VERSION ""

NS_ :

BS_:

BU_:

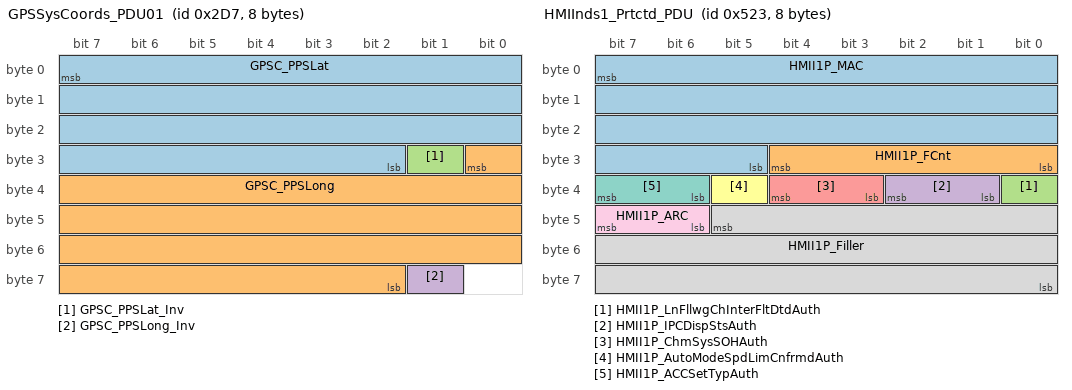
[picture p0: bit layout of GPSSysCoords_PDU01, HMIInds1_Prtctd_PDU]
BO_ 727 GPSSysCoords_PDU01: 8 Vector__XXX
 SG_ GPSC_PPSLat : 7|30@0- (1,0) [-5.36871e+008|5.36871e+008] "ms arc" ACP2_MCU,BSM,VICM,ECM,EOCM,EOCM_HC_Superset,FCM,E44,PCM,VDM,ECP_E
 SG_ GPSC_PPSLong : 24|31@0- (1,0) [-1.07374e+009|1.07374e+009] "ms arc" ACP2_MCU,BSM,VICM,ECM,EOCM,EOCM_HC_Superset,FCM,E44,PCM,VDM,ECP_E
 SG_ GPSC_PPSLat_Inv : 25|1@0+ (1,0) [0|1] "" ACP2_MCU,BSM,VICM,EOCM,EOCM_HC_Superset,FCM,E44,VDM,ECP_E
 SG_ GPSC_PPSLong_Inv : 57|1@0+ (1,0) [0|1] "" ACP2_MCU,BSM,VICM,EOCM,EOCM_HC_Superset,FCM,E44,VDM,ECP_E

BO_ 1385 HMIInds1_PCSM_PDU: 8 Vector__XXX
 SG_ HMIInds1_PCSM : 7|64@0+ (1,0) [0|1.84467e+019] "" ACP2_MCU,EOCM,EOCM_HC_Superset,FCM

BO_ 1315 HMIInds1_Prtctd_PDU: 8 Vector__XXX
 SG_ HMII1P_MAC : 7|27@0+ (1,0) [0|1.34218e+008] "" ACP2_MCU,EOCM,EOCM_HC_Superset,FCM
 SG_ HMII1P_FCnt : 28|5@0+ (1,0) [0|31] "" ACP2_MCU,EOCM,EOCM_HC_Superset,FCM
 SG_ HMII1P_LnFllwgChInterFltDtdAuth : 32|1@0+ (1,0) [0|1] "" ACP2_MCU,EOCM,EOCM_HC_Superset,FCM
 SG_ HMII1P_IPCDispStsAuth : 34|2@0+ (1,0) [0|2] "" ACP2_MCU,EOCM,EOCM_HC_Superset,FCM
 SG_ HMII1P_ChmSysSOHAuth : 36|2@0+ (1,0) [0|2] "" ACP2_MCU,EOCM,EOCM_HC_Superset,FCM
 SG_ HMII1P_AutoModeSpdLimCnfrmdAuth : 37|1@0+ (1,0) [0|1] "" ACP2_MCU,ECM,EOCM,EOCM_HC_Superset,FCM,PCM,ECP_E
 SG_ HMII1P_ACCSetTypAuth : 39|2@0+ (1,0) [0|1] "" ACP2_MCU,EOCM,EOCM_HC_Superset,FCM
 SG_ HMII1P_Filler : 45|22@0+ (1,0) [0|4.1943e+006] "" ACP2_MCU,EOCM,EOCM_HC_Superset,FCM
 SG_ HMII1P_ARC : 47|2@0+ (1,0) [0|3] "" ACP2_MCU,EOCM,EOCM_HC_Superset,FCM

BO_ 2147745832 Message0346_PDU: 6 Vector__XXX
 SG_ Sig3538 : 7|1@0+ (1,0) [0|1] "" CGM

BO_ 916 Message0351_PDU: 8 Vector__XXX
 SG_ Sig3618 : 7|64@0+ (1,0) [0|1.84467e+019] "" BSM_MH

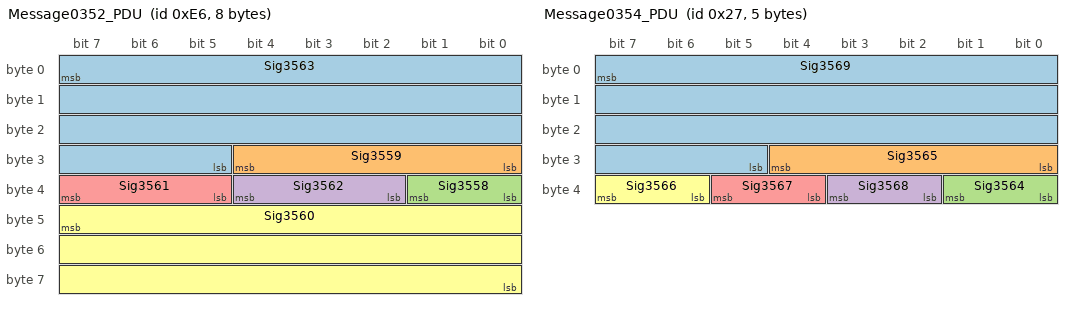
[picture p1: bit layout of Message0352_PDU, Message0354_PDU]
BO_ 230 Message0352_PDU: 8 Vector__XXX
 SG_ Sig3563 : 7|27@0+ (1,0) [0|1.34218e+008] "" BSM_MH
 SG_ Sig3559 : 28|5@0+ (1,0) [0|31] "" BSM_MH
 SG_ Sig3558 : 33|2@0+ (1,0) [0|3] "" BSM_MH
 SG_ Sig3562 : 36|3@0+ (1,0) [0|3] "" BSM_MH
 SG_ Sig3561 : 39|3@0+ (1,0) [0|4] "" BSM_MH
 SG_ Sig3560 : 47|24@0+ (1,0) [0|1.67772e+007] "" BSM_MH

BO_ 915 Message0353_PDU: 8 Vector__XXX
 SG_ Sig3619 : 7|64@0+ (1,0) [0|1.84467e+019] "" ECM,ECP_MC,PCM

BO_ 39 Message0354_PDU: 5 Vector__XXX
 SG_ Sig3569 : 7|27@0+ (1,0) [0|1.34218e+008] "" ECM,ECP_MC,PCM
 SG_ Sig3565 : 28|5@0+ (1,0) [0|31] "" ECM,ECP_MC,PCM
 SG_ Sig3564 : 33|2@0+ (1,0) [0|3] "" ECM,ECP_MC,PCM
 SG_ Sig3568 : 35|2@0+ (1,0) [0|3] "" ECM,ECP_MC,PCM
 SG_ Sig3567 : 37|2@0+ (1,0) [0|2] "" ECM,ECP_MC,PCM
 SG_ Sig3566 : 39|2@0+ (1,0) [0|2] "" ECM,ECP_MC,PCM

BO_ 1384 HptcSt_PCSM_PDU: 8 Vector__XXX
 SG_ HptcSt_PCSM : 7|64@0+ (1,0) [0|1.84467e+019] "" ACP2_MCU,EOCM,EOCM_HC_Superset,FCM

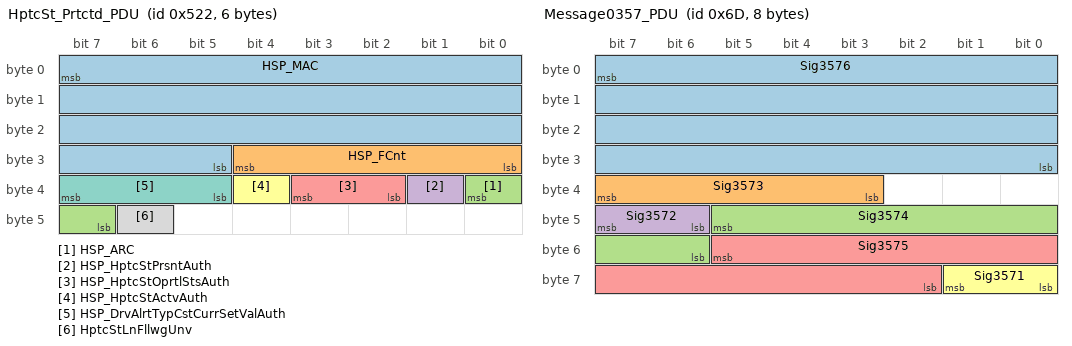
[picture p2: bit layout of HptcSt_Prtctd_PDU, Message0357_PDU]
BO_ 1314 HptcSt_Prtctd_PDU: 6 Vector__XXX
 SG_ HSP_MAC : 7|27@0+ (1,0) [0|1.34218e+008] "" ACP2_MCU,EOCM,EOCM_HC_Superset,FCM
 SG_ HSP_FCnt : 28|5@0+ (1,0) [0|31] "" ACP2_MCU,EOCM,EOCM_HC_Superset,FCM
 SG_ HSP_ARC : 32|2@0+ (1,0) [0|3] "" ACP2_MCU,EOCM,EOCM_HC_Superset,FCM
 SG_ HSP_HptcStPrsntAuth : 33|1@0+ (1,0) [0|1] "" ACP2_MCU,EOCM,EOCM_HC_Superset,FCM
 SG_ HSP_HptcStOprtlStsAuth : 35|2@0+ (1,0) [0|2] "" ACP2_MCU,EOCM,EOCM_HC_Superset,FCM
 SG_ HSP_HptcStActvAuth : 36|1@0+ (1,0) [0|1] "" ACP2_MCU,EOCM,EOCM_HC_Superset,FCM
 SG_ HSP_DrvAlrtTypCstCurrSetValAuth : 39|3@0+ (1,0) [0|2] "" ACP2_MCU,EOCM,EOCM_HC_Superset,FCM,NVM
 SG_ HptcStLnFllwgUnv : 46|1@0+ (1,0) [0|1] "" ACP2_MCU,EOCM,EOCM_HC_Superset,FCM

BO_ 914 HstVehPathParms_PCSM_PDU: 8 Vector__XXX
 SG_ HstVehPathParms_PCSM : 7|64@0+ (1,0) [0|1.84467e+019] "" DMS

BO_ 87 HstVehPathParms_Prtctd_PDU: 32 Vector__XXX
 SG_ HVPPP_MAC : 7|32@0+ (1,0) [0|4.29497e+009] "" CGM,DMS
 SG_ HVPPP_FCnt : 39|5@0+ (1,0) [0|31] "" CGM,DMS
 SG_ HVPPP_HstVehLatVelAuth : 46|8@0+ (0.05,-6.4) [-6.4|6.35] "m/s" CGM,DMS
 SG_ HVPPP_FrwdVsnModeCmdAuth : 47|1@0+ (1,0) [0|1] "" CGM,DMS
 SG_ HVPPP_HstVehLngVelAuth : 53|12@0+ (0.0625,-128) [-128|127.938] "m/s" CGM,DMS,NVM
 SG_ HVPPP_HstVehLatVelAuth_Inv : 54|1@0+ (1,0) [0|1] "" CGM,DMS
 SG_ HVPPP_HstVehPathCrvAuth : 56|16@0- (1e-05,0) [-0.32768|0.32767] "1/m" CGM,DMS
 SG_ HVPPP_HstVehLngVelAuth_Inv : 57|1@0+ (1,0) [0|1] "" CGM,DMS
 SG_ HVPPP_HstVehPathCrvDrvtAuth : 72|15@0+ (0.001,-16) [-16|16.767] "1/m-s" CGM,DMS
 SG_ HVPPP_HstVehPathModeAuth : 89|2@0+ (1,0) [0|2] "" CGM,DMS
 SG_ HVPPP_HstVehSdslAngAuth : 103|12@0+ (0.0625,-128) [-128|127.938] "deg/s" CGM,DMS
 SG_ HVPPP_HstVehTrnCntrLatOfstAuth : 107|14@0+ (1,-8192) [-8192|8191] "m" CGM,DMS
 SG_ HVPPP_HstVehTrnCntrLngOfstAuth : 125|8@0+ (0.1,-12.8) [-12.8|12.7] "m" CGM,DMS
 SG_ HVPPP_HstVehVelAuth : 131|12@0+ (0.0625,-128) [-128|127.938] "m/s" CGM,DMS
 SG_ HVPPP_HstVehTrvlDirAuth : 133|2@0+ (1,0) [0|3] "" CGM,DMS
 SG_ HVPPP_HstVehYawRateAuth : 150|12@0+ (0.0625,-128) [-128|127.938] "deg/s" CGM,DMS,NVM
 SG_ HVPPP_HstVehVelAuth_Inv : 151|1@0+ (1,0) [0|1] "" CGM,DMS
 SG_ HVPPP_LngRngRadarModeCmdAuth : 153|2@0+ (1,0) [0|2] "" CGM,DMS
 SG_ HVPPP_HstVehYawRateAuth_Inv : 154|1@0+ (1,0) [0|1] "" CGM,DMS,NVM
 SG_ HVPPP_ObjSnsrTmSyncMstrClckAuth : 167|32@0+ (1,0) [0|4.29497e+009] "ms" CGM,DMS
 SG_ HVPPP_ARC : 193|2@0+ (1,0) [0|3] "" CGM,DMS
 SG_ HVPPP_ShrtRngRadarModeCmdAuth : 195|2@0+ (1,0) [0|2] "" CGM,DMS
 SG_ HVPPP_ObjsRetndRrwdSnsrsAuth : 197|2@0+ (1,0) [0|2] "" CGM,DMS
 SG_ HVPPP_ObjsRetndFrwdSnsrsAuth : 199|2@0+ (1,0) [0|2] "" CGM,DMS
 SG_ HstVehRideHghtOfst : 201|9@0- (1,0) [-256|255] "mm" CGM,DMS
 SG_ DrvrMonSysModeCmd : 203|2@0+ (1,0) [0|2] "" CGM,DMS
 SG_ LnFllwgFtrStatAuth : 207|4@0+ (1,0) [0|10] "" CGM,DMS
 SG_ HstVehRideHghtOfst_Inv : 208|1@0+ (1,0) [0|1] "" CGM,DMS
 SG_ HVPPP_Filler : 222|19@0+ (1,0) [0|524287] "" CGM,DMS
 SG_ HstVehRideHghtOfstSts : 223|1@0+ (1,0) [0|1] "" CGM,DMS
 SG_ HVPPP_FillerExtnd : 235|20@0+ (1,0) [0|1.04858e+006] "" CGM,DMS

BO_ 687 Message0356_PDU: 8 Vector__XXX
 SG_ Sig3623 : 7|64@0+ (1,0) [0|1.84467e+019] "" Vector__XXX

BO_ 109 Message0357_PDU: 8 Vector__XXX
 SG_ Sig3576 : 7|32@0+ (1,0) [0|4.29497e+009] "" Vector__XXX
 SG_ Sig3573 : 39|5@0+ (1,0) [0|31] "" Vector__XXX
 SG_ Sig3574 : 45|8@0- (0.05,0) [-6.4|6.35] "m/s" Vector__XXX
 SG_ Sig3572 : 47|2@0+ (1,0) [0|3] "" Vector__XXX
 SG_ Sig3575 : 53|12@0- (0.0625,0) [-128|127.938] "m/s" Vector__XXX
 SG_ Sig3571 : 57|2@0+ (1,0) [0|3] "" Vector__XXX

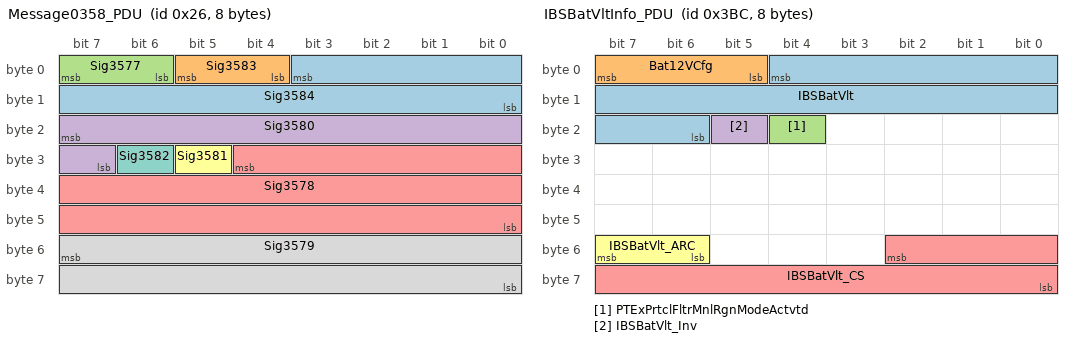
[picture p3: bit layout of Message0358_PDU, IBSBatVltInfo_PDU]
BO_ 38 Message0358_PDU: 8 Vector__XXX
 SG_ Sig3584 : 3|12@0- (0.0625,0) [-128|127.938] "deg/s" Vector__XXX
 SG_ Sig3583 : 5|2@0+ (1,0) [0|3] "" Vector__XXX
 SG_ Sig3577 : 7|2@0+ (1,0) [0|3] "" Vector__XXX
 SG_ Sig3580 : 23|9@0- (1,0) [-256|255] "mm" Vector__XXX
 SG_ Sig3578 : 28|21@0+ (1,0) [0|2.09715e+006] "" Vector__XXX
 SG_ Sig3581 : 29|1@0+ (1,0) [0|1] "" Vector__XXX
 SG_ Sig3582 : 30|1@0+ (1,0) [0|1] "" Vector__XXX
 SG_ Sig3579 : 55|16@0+ (1,0) [0|65535] "" Vector__XXX

BO_ 956 IBSBatVltInfo_PDU: 8 Vector__XXX
 SG_ IBSBatVlt : 4|15@0+ (0.001,0) [0|32.767] "" ECM,PCM
 SG_ Bat12VCfg : 7|3@0+ (1,0) [0|7] "" ECM,PCM
 SG_ PTExPrtclFltrMnlRgnModeActvtd : 20|1@0+ (1,0) [0|1] "" ECM,PCM
 SG_ IBSBatVlt_Inv : 21|1@0+ (1,0) [0|1] "" ECM,PCM
 SG_ IBSBatVlt_CS : 50|11@0+ (1,0) [0|2047] "" ECM,PCM
 SG_ IBSBatVlt_ARC : 55|2@0+ (1,0) [0|3] "" ECM,PCM

BO_ 729 ImoInf_PDU: 8 Vector__XXX
 SG_ ImoInf : 7|64@0+ (1,0) [0|1.84467e+019] "" ECM,PCM,ECP_X1

BO_ 1285 Isolated_GWCGM_PDU02: 6 Vector__XXX
 SG_ HptcStFldIndOn : 15|1@0+ (1,0) [0|1] "" ACP2_MCU,EOCM_HC_Superset,FCM

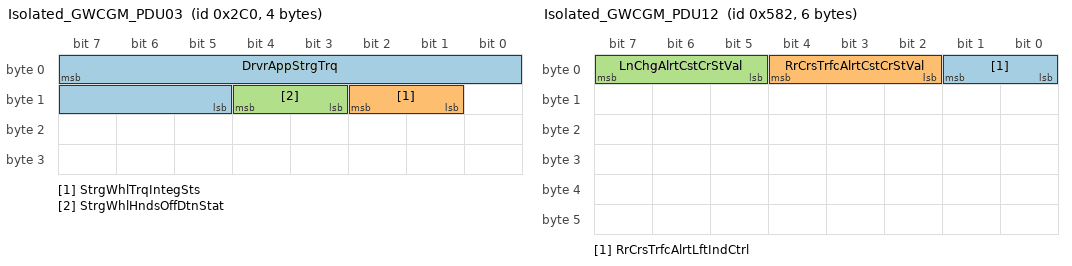
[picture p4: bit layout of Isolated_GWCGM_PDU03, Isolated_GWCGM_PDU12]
BO_ 704 Isolated_GWCGM_PDU03: 4 Vector__XXX
 SG_ DrvrAppStrgTrq : 7|11@0- (0.01,0) [-10.24|10.23] "Nm" Vector__XXX
 SG_ StrgWhlTrqIntegSts : 10|2@0+ (1,0) [0|3] "" Vector__XXX
 SG_ StrgWhlHndsOffDtnStat : 12|2@0+ (1,0) [0|2] "" Vector__XXX

BO_ 1419 Message0367_PDU: 6 Vector__XXX
 SG_ Sig7713 : 1|2@0+ (1,0) [0|3] "" Vector__XXX
 SG_ Sig7709 : 4|3@0+ (1,0) [0|7] "" Vector__XXX
 SG_ Sig3506 : 7|3@0+ (1,0) [0|7] "" Vector__XXX
 SG_ Sig3504 : 8|1@0+ (1,0) [0|1] "" Vector__XXX
 SG_ Sig3503 : 9|1@0+ (1,0) [0|1] "" Vector__XXX
 SG_ Sig3502 : 10|1@0+ (1,0) [0|1] "" Vector__XXX
 SG_ Sig3501 : 11|1@0+ (1,0) [0|1] "" Vector__XXX
 SG_ Sig3500 : 12|1@0+ (1,0) [0|1] "" Vector__XXX
 SG_ Sig3499 : 13|1@0+ (1,0) [0|1] "" Vector__XXX
 SG_ Sig3498 : 14|1@0+ (1,0) [0|1] "" Vector__XXX
 SG_ Sig0451 : 15|1@0+ (1,0) [0|1] "" Vector__XXX
 SG_ Sig7707 : 16|1@0+ (1,0) [0|1] "" Vector__XXX
 SG_ Sig7706 : 17|1@0+ (1,0) [0|1] "" Vector__XXX
 SG_ Sig7705 : 18|1@0+ (1,0) [0|1] "" Vector__XXX
 SG_ Sig7704 : 19|1@0+ (1,0) [0|1] "" Vector__XXX
 SG_ Sig7703 : 20|1@0+ (1,0) [0|1] "" Vector__XXX
 SG_ Sig7702 : 21|1@0+ (1,0) [0|1] "" Vector__XXX
 SG_ Sig7701 : 22|1@0+ (1,0) [0|1] "" Vector__XXX
 SG_ Sig3507 : 23|1@0+ (1,0) [0|1] "" Vector__XXX
 SG_ Sig7710 : 31|1@0+ (1,0) [0|1] "" Vector__XXX

BO_ 1501 Message0368_PDU: 8 Vector__XXX
 SG_ Sig7554 : 7|8@0+ (1,0) [0|255] "" Vector__XXX
 SG_ Sig7559 : 9|6@0+ (1,0) [0|54] "" Vector__XXX
 SG_ Sig7557 : 15|6@0+ (1,0) [0|54] "" Vector__XXX
 SG_ Sig7567 : 19|6@0+ (1,0) [0|45] "" Vector__XXX
 SG_ Sig7569 : 29|6@0+ (1,0) [0|45] "" Vector__XXX
 SG_ Sig7558 : 35|4@0+ (1,0) [0|15] "" Vector__XXX
 SG_ Sig7556 : 39|4@0+ (1,0) [0|15] "" Vector__XXX
 SG_ Sig3474 : 40|1@0+ (1,0) [0|1] "" Vector__XXX
 SG_ Sig3473 : 41|1@0+ (1,0) [0|1] "" Vector__XXX
 SG_ Sig7568 : 44|3@0+ (1,0) [0|5] "" Vector__XXX
 SG_ Sig7566 : 47|3@0+ (1,0) [0|5] "" Vector__XXX
 SG_ Sig7711 : 48|1@0+ (1,0) [0|1] "" Vector__XXX
 SG_ Sig7700 : 49|1@0+ (1,0) [0|1] "" Vector__XXX
 SG_ Sig7564 : 50|1@0+ (1,0) [0|1] "" Vector__XXX
 SG_ Sig7562 : 51|1@0+ (1,0) [0|1] "" Vector__XXX
 SG_ Sig7561 : 52|1@0+ (1,0) [0|1] "" Vector__XXX
 SG_ Sig7560 : 53|1@0+ (1,0) [0|1] "" Vector__XXX
 SG_ Sig7553 : 54|1@0+ (1,0) [0|1] "" Vector__XXX
 SG_ Sig3475 : 55|1@0+ (1,0) [0|1] "" Vector__XXX
 SG_ Sig7712 : 63|1@0+ (1,0) [0|1] "" Vector__XXX

BO_ 1427 Isolated_GWCGM_PDU06: 6 Vector__XXX
 SG_ SBZALCAVisIndStatLt : 7|2@0+ (1,0) [0|2] "" ACP2_MCU,EOCM,EOCM_HC_Superset,FCM

BO_ 1428 Isolated_GWCGM_PDU07: 6 Vector__XXX
 SG_ SBZALCAVisIndStatRt : 7|2@0+ (1,0) [0|2] "" ACP2_MCU,EOCM,EOCM_HC_Superset,FCM

BO_ 1420 Isolated_GWCGM_PDU09: 6 Vector__XXX
 SG_ TLAHSR_HptcStRqstSeqNmb : 1|2@0+ (1,0) [0|3] "counts" Vector__XXX
 SG_ TLAHSR_HptcStRqstPls : 7|6@0+ (1,0) [0|63] "pulses" Vector__XXX

BO_ 1432 Isolated_GWCGM_PDU10: 6 Vector__XXX
 SG_ AutoHgBmActReq : 7|1@0+ (1,0) [0|1] "" Vector__XXX

BO_ 706 Isolated_GWCGM_PDU11: 4 Vector__XXX
 SG_ Sig4151 : 7|8@0- (1,0) [-128|127] "Kph" AHL_AFL,FCM
 SG_ LtFstAprchgVehObjDtd : 15|1@0+ (1,0) [0|1] "" AHL_AFL,FCM

BO_ 1410 Isolated_GWCGM_PDU12: 6 Vector__XXX
 SG_ RrCrsTrfcAlrtLftIndCtrl : 1|2@0+ (1,0) [0|2] "" ACP2_MCU,EOCM,EOCM_HC_Superset,FCM
 SG_ RrCrsTrfcAlrtCstCrStVal : 4|3@0+ (1,0) [0|7] "" ACP2_MCU,EOCM,EOCM_HC_Superset,FCM
 SG_ LnChgAlrtCstCrStVal : 7|3@0+ (1,0) [0|7] "" ACP2_MCU,EOCM,EOCM_HC_Superset,FCM

BO_ 1444 Isolated_GWCGM_PDU13: 6 Vector__XXX
 SG_ LtSdVehObjDtd : 5|1@0+ (1,0) [0|1] "" ACP2_MCU,AHL_AFL,EOCM,EOCM_HC_Superset,FCM
 SG_ SBZALCAOvrllOplSts : 7|2@0+ (1,0) [0|2] "" ACP2_MCU,EOCM,EOCM_HC_Superset,FCM

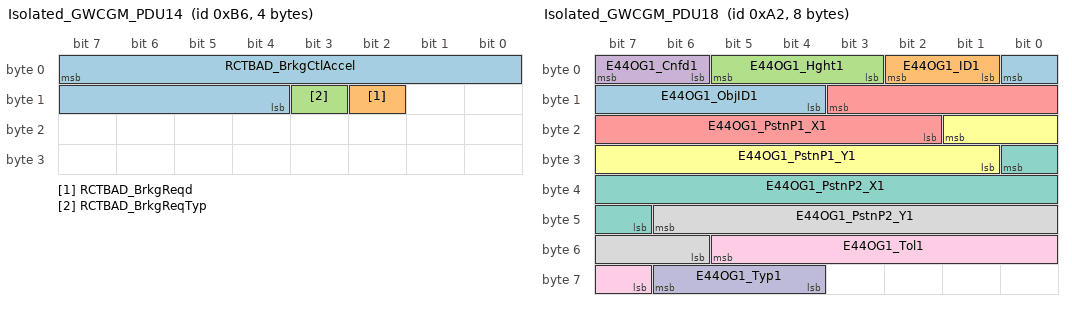
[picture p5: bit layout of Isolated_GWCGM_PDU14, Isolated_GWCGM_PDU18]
BO_ 182 Isolated_GWCGM_PDU14: 4 Vector__XXX
 SG_ RCTBAD_BrkgCtlAccel : 7|12@0- (0.01,0) [-20.48|20.47] "m/s2" EBCM
 SG_ RCTBAD_BrkgReqd : 10|1@0+ (1,0) [0|1] "" ACP2_MCU,EBCM,EOCM,EOCM_HC_Superset
 SG_ RCTBAD_BrkgReqTyp : 11|1@0+ (1,0) [0|1] "" EBCM

BO_ 708 Isolated_GWCGM_PDU16: 4 Vector__XXX
 SG_ Sig5569 : 7|8@0- (1,0) [-128|127] "Kph" AHL_AFL,FCM
 SG_ RtFstAprchgVehObjDtd : 15|1@0+ (1,0) [0|1] "" AHL_AFL,FCM

BO_ 1412 Isolated_GWCGM_PDU17: 6 Vector__XXX
 SG_ RtSdVehObjDtd : 3|1@0+ (1,0) [0|1] "" ACP2_MCU,AHL_AFL,EOCM,EOCM_HC_Superset,FCM
 SG_ RrCrsTrfcAlrtRgIndCtrl : 7|2@0+ (1,0) [0|2] "" ACP2_MCU,EOCM,EOCM_HC_Superset,FCM

BO_ 162 Isolated_GWCGM_PDU18: 8 Vector__XXX
 SG_ E44OG1_ObjID1 : 0|5@0+ (1,0) [0|31] "" FCM
 SG_ E44OG1_ID1 : 2|2@0+ (1,0) [0|3] "" FCM
 SG_ E44OG1_Hght1 : 5|3@0+ (1,0) [0|3] "" FCM
 SG_ E44OG1_Cnfd1 : 7|2@0+ (1,0) [0|3] "" FCM
 SG_ E44OG1_PstnP1_X1 : 11|10@0+ (1,-1023) [-1023|0] "cm" FCM
 SG_ E44OG1_PstnP1_Y1 : 17|9@0- (1,0) [-256|255] "cm" FCM
 SG_ E44OG1_PstnP2_X1 : 24|10@0+ (1,-1023) [-1023|0] "cm" FCM
 SG_ E44OG1_PstnP2_Y1 : 46|9@0- (1,0) [-256|255] "cm" FCM
 SG_ E44OG1_Tol1 : 53|7@0+ (1,0) [0|127] "cm" FCM
 SG_ E44OG1_Typ1 : 62|3@0+ (1,0) [0|6] "" FCM

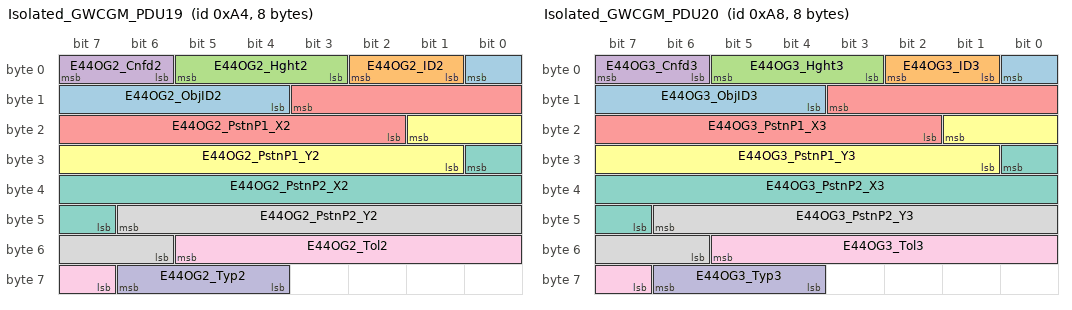
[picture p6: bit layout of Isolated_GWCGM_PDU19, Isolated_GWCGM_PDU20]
BO_ 164 Isolated_GWCGM_PDU19: 8 Vector__XXX
 SG_ E44OG2_ObjID2 : 0|5@0+ (1,0) [0|31] "" FCM
 SG_ E44OG2_ID2 : 2|2@0+ (1,0) [0|3] "" FCM
 SG_ E44OG2_Hght2 : 5|3@0+ (1,0) [0|3] "" FCM
 SG_ E44OG2_Cnfd2 : 7|2@0+ (1,0) [0|3] "" FCM
 SG_ E44OG2_PstnP1_X2 : 11|10@0+ (1,-1023) [-1023|0] "cm" FCM
 SG_ E44OG2_PstnP1_Y2 : 17|9@0- (1,0) [-256|255] "cm" FCM
 SG_ E44OG2_PstnP2_X2 : 24|10@0+ (1,-1023) [-1023|0] "cm" FCM
 SG_ E44OG2_PstnP2_Y2 : 46|9@0- (1,0) [-256|255] "cm" FCM
 SG_ E44OG2_Tol2 : 53|7@0+ (1,0) [0|127] "cm" FCM
 SG_ E44OG2_Typ2 : 62|3@0+ (1,0) [0|6] "" FCM

BO_ 168 Isolated_GWCGM_PDU20: 8 Vector__XXX
 SG_ E44OG3_ObjID3 : 0|5@0+ (1,0) [0|31] "" FCM
 SG_ E44OG3_ID3 : 2|2@0+ (1,0) [0|3] "" FCM
 SG_ E44OG3_Hght3 : 5|3@0+ (1,0) [0|3] "" FCM
 SG_ E44OG3_Cnfd3 : 7|2@0+ (1,0) [0|3] "" FCM
 SG_ E44OG3_PstnP1_X3 : 11|10@0+ (1,-1023) [-1023|0] "cm" FCM
 SG_ E44OG3_PstnP1_Y3 : 17|9@0- (1,0) [-256|255] "cm" FCM
 SG_ E44OG3_PstnP2_X3 : 24|10@0+ (1,-1023) [-1023|0] "cm" FCM
 SG_ E44OG3_PstnP2_Y3 : 46|9@0- (1,0) [-256|255] "cm" FCM
 SG_ E44OG3_Tol3 : 53|7@0+ (1,0) [0|127] "cm" FCM
 SG_ E44OG3_Typ3 : 62|3@0+ (1,0) [0|6] "" FCM

BO_ 2147745821 Message0370_PDU: 1 Vector__XXX
 SG_ Sig4007 : 7|1@0+ (1,0) [0|1] "" CGM

BO_ 1421 LnFllwgFtrStat_CAN2_PDU01: 6 Vector__XXX
 SG_ LnFllwgFtrStat : 7|4@0+ (1,0) [0|10] "" Vector__XXX

BO_ 1383 LnFllwgHptcStReqs_PCSM_PDU: 8 Vector__XXX
 SG_ LnFllwgHptcStReqs_PCSM : 7|64@0+ (1,0) [0|1.84467e+019] "" Vector__XXX

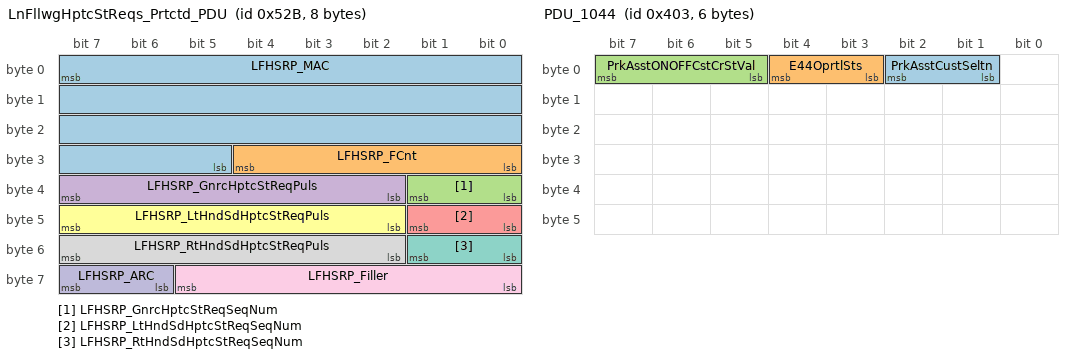
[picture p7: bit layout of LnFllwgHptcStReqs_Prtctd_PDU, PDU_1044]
BO_ 1323 LnFllwgHptcStReqs_Prtctd_PDU: 8 Vector__XXX
 SG_ LFHSRP_MAC : 7|27@0+ (1,0) [0|1.34218e+008] "" Vector__XXX
 SG_ LFHSRP_FCnt : 28|5@0+ (1,0) [0|31] "" Vector__XXX
 SG_ LFHSRP_GnrcHptcStReqSeqNum : 33|2@0+ (1,0) [0|3] "count" Vector__XXX
 SG_ LFHSRP_GnrcHptcStReqPuls : 39|6@0+ (1,0) [0|63] "counts" Vector__XXX
 SG_ LFHSRP_LtHndSdHptcStReqSeqNum : 41|2@0+ (1,0) [0|3] "count" Vector__XXX
 SG_ LFHSRP_LtHndSdHptcStReqPuls : 47|6@0+ (1,0) [0|63] "counts" Vector__XXX
 SG_ LFHSRP_RtHndSdHptcStReqSeqNum : 49|2@0+ (1,0) [0|3] "count" Vector__XXX
 SG_ LFHSRP_RtHndSdHptcStReqPuls : 55|6@0+ (1,0) [0|63] "counts" Vector__XXX
 SG_ LFHSRP_Filler : 61|6@0+ (1,0) [0|63] "" Vector__XXX
 SG_ LFHSRP_ARC : 63|2@0+ (1,0) [0|3] "" Vector__XXX

BO_ 1027 PDU_1044: 6 Vector__XXX
 SG_ PrkAsstCustSeltn : 2|2@0+ (1,0) [0|2] "" FCM
 SG_ E44OprtlSts : 4|2@0+ (1,0) [0|2] "" FCM
 SG_ PrkAsstONOFFCstCrStVal : 7|3@0+ (1,0) [0|7] "" CGM,FCM

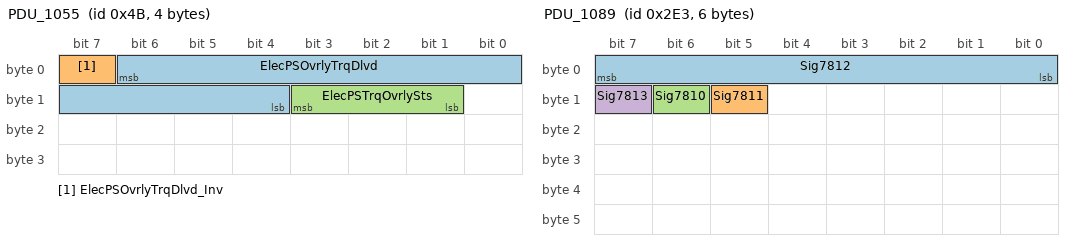
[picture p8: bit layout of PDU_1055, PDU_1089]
BO_ 75 PDU_1055: 4 Vector__XXX
 SG_ ElecPSOvrlyTrqDlvd : 6|11@0- (0.01,0) [-10.24|10.23] "" EBCM
 SG_ ElecPSOvrlyTrqDlvd_Inv : 7|1@0+ (1,0) [0|1] "" EBCM
 SG_ ElecPSTrqOvrlySts : 11|3@0+ (1,0) [0|5] "" CGM,EBCM

BO_ 32 PDU_1062: 6 Vector__XXX
 SG_ StrgEstdRckF : 6|11@0- (25,0) [-25600|25575] "N" ECP_E
 SG_ StrgEstdRckF_Inv : 7|1@0+ (1,0) [0|1] "" ECP_E

BO_ 739 PDU_1089: 6 Vector__XXX
 SG_ Sig7812 : 7|8@0+ (10,500) [500|3050] "RPM" ECM
 SG_ Sig7811 : 13|1@0+ (1,0) [0|1] "" ECM
 SG_ Sig7810 : 14|1@0+ (1,0) [0|1] "" ECM
 SG_ Sig7813 : 15|1@0+ (1,0) [0|1] "" ECM

BO_ 946 PDU_2000: 8 Vector__XXX
 SG_ Sig0417 : 1|2@0+ (1,0) [0|3] "" CGM
 SG_ Sig4160 : 4|3@0+ (1,0) [0|7] "" CGM
 SG_ Sig0415 : 7|3@0+ (1,0) [0|7] "" CGM
 SG_ Sig0109 : 8|1@0+ (1,0) [0|1] "" CGM
 SG_ AFLServHdlmpsIndOn : 9|1@0+ (1,0) [0|1] "" CGM
 SG_ Sig0108 : 10|1@0+ (1,0) [0|1] "" CGM
 SG_ Sig0107 : 11|1@0+ (1,0) [0|1] "" CGM
 SG_ Sig0106 : 12|1@0+ (1,0) [0|1] "" CGM
 SG_ Sig0105 : 13|1@0+ (1,0) [0|1] "" CGM
 SG_ Sig0104 : 14|1@0+ (1,0) [0|1] "" CGM
 SG_ Sig0103 : 15|1@0+ (1,0) [0|1] "" CGM
 SG_ Sig0413 : 16|1@0+ (1,0) [0|1] "" CGM
 SG_ Sig0412 : 17|1@0+ (1,0) [0|1] "" CGM
 SG_ Sig0411 : 18|1@0+ (1,0) [0|1] "" CGM
 SG_ Sig0410 : 19|1@0+ (1,0) [0|1] "" CGM
 SG_ Sig0409 : 20|1@0+ (1,0) [0|1] "" CGM
 SG_ Sig0408 : 21|1@0+ (1,0) [0|1] "" CGM
 SG_ Sig0407 : 22|1@0+ (1,0) [0|1] "" CGM
 SG_ Sig0110 : 23|1@0+ (1,0) [0|1] "" CGM
 SG_ Sig4157 : 24|1@0+ (1,0) [0|1] "" CGM
 SG_ Sig4156 : 25|1@0+ (1,0) [0|1] "" CGM
 SG_ Sig4155 : 26|1@0+ (1,0) [0|1] "" CGM
 SG_ Sig4154 : 27|1@0+ (1,0) [0|1] "" CGM
 SG_ Sig4153 : 28|1@0+ (1,0) [0|1] "" CGM
 SG_ Sig4152 : 29|1@0+ (1,0) [0|1] "" CGM
 SG_ AdvdFrtLgtSysHiBmIndOnReqd : 30|1@0+ (1,0) [0|1] "" CGM
 SG_ Sig0416 : 31|1@0+ (1,0) [0|1] "" CGM
 SG_ Sig4161 : 38|1@0+ (1,0) [0|1] "" CGM
 SG_ Sig4158 : 39|1@0+ (1,0) [0|1] "" CGM

BO_ 701 PDU_2001: 2 Vector__XXX
 SG_ AE44CtrlTctlFdbk : 7|1@0+ (1,0) [0|1] "" CGM,EPS,EPSb

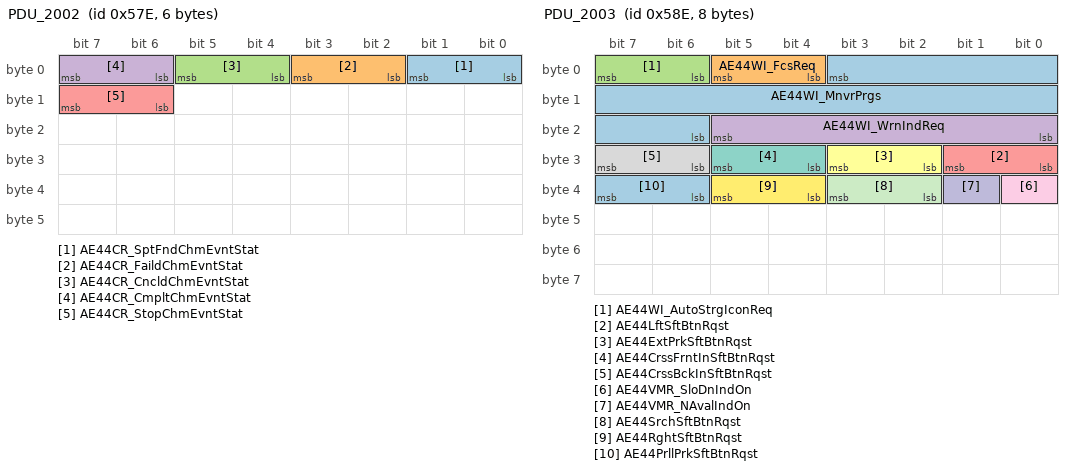
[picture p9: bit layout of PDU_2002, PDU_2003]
BO_ 1406 PDU_2002: 6 Vector__XXX
 SG_ AE44CR_SptFndChmEvntStat : 1|2@0+ (1,0) [0|2] "" CGM
 SG_ AE44CR_FaildChmEvntStat : 3|2@0+ (1,0) [0|2] "" CGM
 SG_ AE44CR_CncldChmEvntStat : 5|2@0+ (1,0) [0|2] "" CGM
 SG_ AE44CR_CmpltChmEvntStat : 7|2@0+ (1,0) [0|2] "" CGM
 SG_ AE44CR_StopChmEvntStat : 15|2@0+ (1,0) [0|2] "" CGM

BO_ 1422 PDU_2003: 8 Vector__XXX
 SG_ AE44WI_MnvrPrgs : 3|14@0+ (0.01,0) [0|163.83] "" CGM
 SG_ AE44WI_FcsReq : 5|2@0+ (1,0) [0|2] "" CGM
 SG_ AE44WI_AutoStrgIconReq : 7|2@0+ (1,0) [0|2] "" CGM
 SG_ AE44WI_WrnIndReq : 21|6@0+ (1,0) [0|59] "" CGM
 SG_ AE44LftSftBtnRqst : 25|2@0+ (1,0) [0|3] "" CGM
 SG_ AE44ExtPrkSftBtnRqst : 27|2@0+ (1,0) [0|3] "" CGM
 SG_ AE44CrssFrntInSftBtnRqst : 29|2@0+ (1,0) [0|3] "" CGM
 SG_ AE44CrssBckInSftBtnRqst : 31|2@0+ (1,0) [0|3] "" CGM
 SG_ AE44VMR_SloDnIndOn : 32|1@0+ (1,0) [0|1] "" CGM
 SG_ AE44VMR_NAvalIndOn : 33|1@0+ (1,0) [0|1] "" CGM
 SG_ AE44SrchSftBtnRqst : 35|2@0+ (1,0) [0|3] "" CGM
 SG_ AE44RghtSftBtnRqst : 37|2@0+ (1,0) [0|3] "" CGM
 SG_ AE44PrllPrkSftBtnRqst : 39|2@0+ (1,0) [0|3] "" CGM

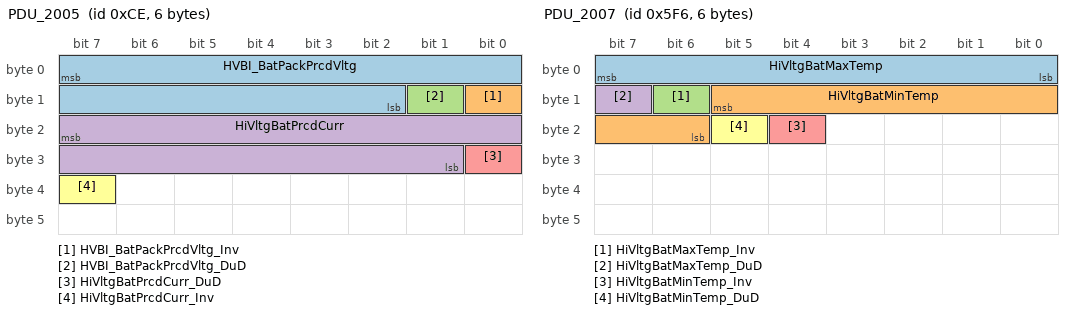
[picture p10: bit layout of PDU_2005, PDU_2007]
BO_ 206 PDU_2005: 6 Vector__XXX
 SG_ HVBI_BatPackPrcdVltg : 7|14@0+ (0.0624,0) [0|1022.3] "V" CGM,ECM,PCM,VDM,ECP_E,ECP_S,ECP_S2,ECP_X1
 SG_ HVBI_BatPackPrcdVltg_Inv : 8|1@0+ (1,0) [0|1] "" CGM,ECM,PCM,VDM,ECP_E,ECP_S,ECP_S2,ECP_X1
 SG_ HVBI_BatPackPrcdVltg_DuD : 9|1@0+ (1,0) [0|1] "" CGM,ECP_X1
 SG_ HiVltgBatPrcdCurr : 23|15@0- (0.3,0) [-4915.2|4914.9] "A" CGM,ECM,PCM,VDM,ECP_E,ECP_S2,ECP_X1
 SG_ HiVltgBatPrcdCurr_DuD : 24|1@0+ (1,0) [0|1] "" ECM,PCM,ECP_E,ECP_S2,ECP_X1
 SG_ HiVltgBatPrcdCurr_Inv : 39|1@0+ (1,0) [0|1] "" CGM,ECM,PCM,VDM,ECP_E,ECP_S2,ECP_X1

BO_ 722 PDU_2006: 16 Vector__XXX
 SG_ HVBSOC_BatSOC : 7|16@0+ (0.0015259,0) [0|100] "%" ADIMa,ADIMb,CGM,ECM,PCM,VDM,ECP_E,ECP_S,ECP_S2,ECP_X1
 SG_ HVBSOC_BatSOCMin : 23|8@0+ (0.392157,0) [0|100] "%" ECM,PCM,ECP_E,ECP_S2,ECP_X1
 SG_ HVBSOC_BatSOCTgt : 31|16@0+ (0.0015259,0) [0|100] "%" ECM,PCM,ECP_E,ECP_S2,ECP_X1
 SG_ HVBVL_VltgLwrLim : 46|10@0+ (0.52,0) [0|531.96] "V" ECM,PCM,ECP_E,ECP_S2,ECP_X1
 SG_ HVBSOC_BatSOC_Inv : 47|1@0+ (1,0) [0|1] "" ADIMa,ADIMb,CGM,ECM,PCM,ECP_E,ECP_S,ECP_S2,ECP_X1
 SG_ HVBVL_VltgLwrLimCrnk : 52|10@0+ (0.52,0) [0|531.96] "V" ECP_E,ECP_S2,ECP_X1
 SG_ HVBVL_VltgUpprLim : 58|10@0+ (0.52,0) [0|531.96] "V" ECM,PCM,ECP_E,ECP_S2,ECP_X1
 SG_ HVBCL_CurrLwrLim : 64|14@0+ (0.3,0) [0|4914.9] "A" ECM,PCM,ECP_E,ECP_S2,ECP_X1
 SG_ HVBCL_CurrUpprLim : 82|14@0+ (0.3,0) [0|4914.9] "A" ECM,PCM,ECP_E,ECP_S2,ECP_X1

BO_ 1526 PDU_2007: 6 Vector__XXX
 SG_ HiVltgBatMaxTemp : 7|8@0+ (0.5,-40) [-40|87.5] "Deg C" CGM,ECM,PCM,VDM,ECP_E,ECP_S,ECP_S2,ECP_X1
 SG_ HiVltgBatMinTemp : 13|8@0+ (0.5,-40) [-40|87.5] "Deg C" CGM,ECM,PCM,VDM,ECP_E,ECP_S,ECP_S2,ECP_X1
 SG_ HiVltgBatMaxTemp_Inv : 14|1@0+ (1,0) [0|1] "" CGM,ECM,PCM,VDM,ECP_E,ECP_S,ECP_S2,ECP_X1
 SG_ HiVltgBatMaxTemp_DuD : 15|1@0+ (1,0) [0|1] "" ECP_X1
 SG_ HiVltgBatMinTemp_Inv : 20|1@0+ (1,0) [0|1] "" CGM,ECM,PCM,VDM,ECP_E,ECP_S,ECP_S2,ECP_X1
 SG_ HiVltgBatMinTemp_DuD : 21|1@0+ (1,0) [0|1] "" ECP_X1

BO_ 721 PDU_2008: 2 Vector__XXX
 SG_ Sig2660 : 6|7@0+ (1,0) [0|127] "%" CGM
 SG_ Sig2661 : 7|1@0+ (1,0) [0|1] "" CGM

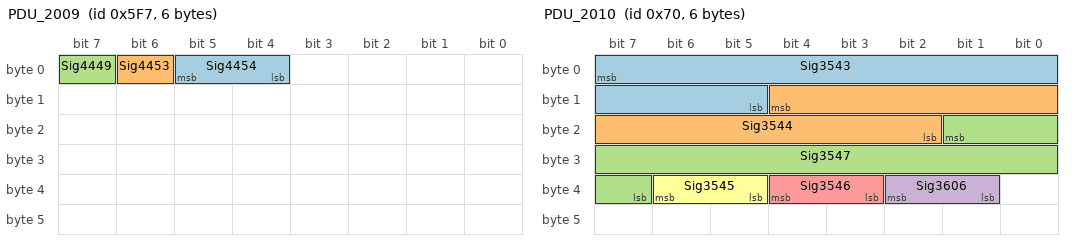
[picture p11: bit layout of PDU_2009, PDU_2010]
BO_ 1527 PDU_2009: 6 Vector__XXX
 SG_ Sig4454 : 5|2@0+ (1,0) [0|3] "" ECM,PCM
 SG_ Sig4453 : 6|1@0+ (1,0) [0|1] "" ECM,PCM
 SG_ Sig4449 : 7|1@0+ (1,0) [0|1] "" ECM,PCM

BO_ 112 PDU_2010: 6 Vector__XXX
 SG_ Sig3543 : 7|11@0+ (0.1,0) [0|204.7] "kW" ECM,PCM
 SG_ Sig3544 : 12|11@0+ (0.1,0) [0|204.7] "kW" ECM,PCM
 SG_ Sig3547 : 17|11@0+ (0.1,0) [0|204.7] "kW" ECM,PCM
 SG_ Sig3606 : 34|2@0+ (1,0) [0|2] "" ECM,PCM
 SG_ Sig3546 : 36|2@0+ (1,0) [0|2] "" ECM,PCM
 SG_ Sig3545 : 38|2@0+ (1,0) [0|2] "" ECM,PCM

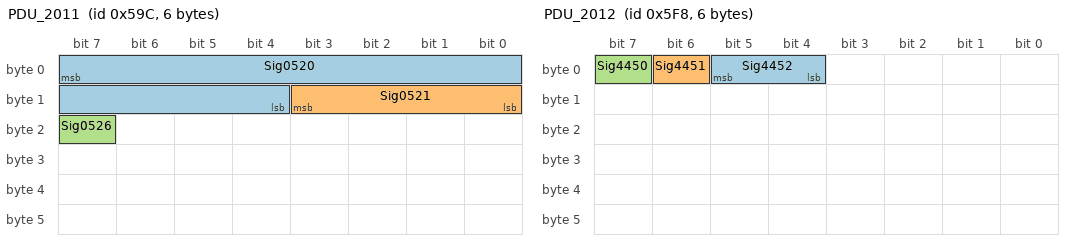
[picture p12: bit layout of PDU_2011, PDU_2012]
BO_ 1436 PDU_2011: 6 Vector__XXX
 SG_ Sig0520 : 7|12@0+ (1,0) [0|4095] "count" ECM,PCM
 SG_ Sig0521 : 11|4@0+ (1,0) [0|15] "" ECM,PCM
 SG_ Sig0526 : 23|1@0+ (1,0) [0|1] "" ECM,PCM

BO_ 1528 PDU_2012: 6 Vector__XXX
 SG_ Sig4452 : 5|2@0+ (1,0) [0|3] "" ECM,PCM
 SG_ Sig4451 : 6|1@0+ (1,0) [0|1] "" ECM,PCM
 SG_ Sig4450 : 7|1@0+ (1,0) [0|1] "" ECM,PCM

BO_ 928 PDU_2013: 6 Vector__XXX
 SG_ Sig4919 : 4|3@0+ (1,0) [0|4] "" ECP_X1
 SG_ HiVltgBatOutOfEngyIndReq : 7|3@0+ (1,0) [0|4] "" CGM

BO_ 723 PDU_2014: 24 Vector__XXX
 SG_ HVBPL_InstnsChrgPwrLim : 7|14@0+ (0.1,0) [0|1638.3] "kW" ECP_E,ECP_S2,ECP_X1
 SG_ HVBPL_InstnsDischrgPwrLim : 9|14@0+ (0.1,0) [0|1638.3] "kW" ECP_E,ECP_S2,ECP_X1
 SG_ HVBPL_LngTrmChrgPwrLim : 27|14@0+ (0.1,0) [0|1638.3] "kW" ECP_E,ECP_S2,ECP_X1
 SG_ HVBPL_LngTrmDischrgPwrLim : 45|14@0+ (0.1,0) [0|1638.3] "kW" ECP_E,ECP_S2,ECP_X1
 SG_ HVBPL_ShrtTrmChrgPwrLim : 63|14@0+ (0.1,0) [0|1638.3] "kW" ECP_E,ECP_S2,ECP_X1
 SG_ PrplDispEngTrq : 73|12@0+ (0.5,-848) [-848|1199.5] "Nm" CGM
 SG_ PrplDispTotTrq : 91|12@0+ (0.5,-848) [-848|1199.5] "Nm" CGM
 SG_ PrplDispEngTrq_Inv : 92|1@0+ (1,0) [0|1] "" CGM
 SG_ PrplDispEngTrq_DuD : 93|1@0+ (1,0) [0|1] "" CGM
 SG_ PwrElecHybAftRunReqTm : 111|11@0+ (0.25,0) [0|511.75] "s" ECM,PCM
 SG_ GrossGridEngyIntoBatSnLstUpdt : 116|10@0+ (0.1,0) [0|102.3] "KWh" ECM,PCM
 SG_ HiVltgThrmlTotPwrUsd : 121|8@0+ (0.2,0) [0|51] "kW" ECP_E,ECP_S2,ECP_X1
 SG_ HiVltgThrmlTotPwrUsd_Inv : 122|1@0+ (1,0) [0|1] "" ECP_E,ECP_S2,ECP_X1
 SG_ NetGridEngyIntoBatSnLstUpdt : 129|9@0+ (0.1,0) [0|51.1] "KWh" ECM,PCM
 SG_ HiVltgThrmlPwrReq : 136|8@0+ (0.2,0) [0|51] "kW" ECP_E,ECP_S2,ECP_X1
 SG_ HiVltgThrmlPwrRqrd : 144|8@0+ (0.2,0) [0|51] "kW" ECP_E,ECP_S2,ECP_X1
 SG_ ChrgSysShfToPrkReqd : 152|1@0+ (1,0) [0|1] "" ECM,PCM,ECP_E,ECP_S,ECP_S2
 SG_ HVBPL_ShrtTrmDischrgPwrLim : 164|14@0+ (0.1,0) [0|1638.3] "kW" ECP_E,ECP_S2,ECP_X1
 SG_ JmpStrtEnbld : 165|1@0+ (1,0) [0|1] "" ECP_X1
 SG_ HiVltgBatGridCnctd : 166|1@0+ (1,0) [0|1] "" ECM,PCM
 SG_ CoolFanFrtEndOutEnbl : 167|1@0+ (1,0) [0|1] "" ECM,PCM

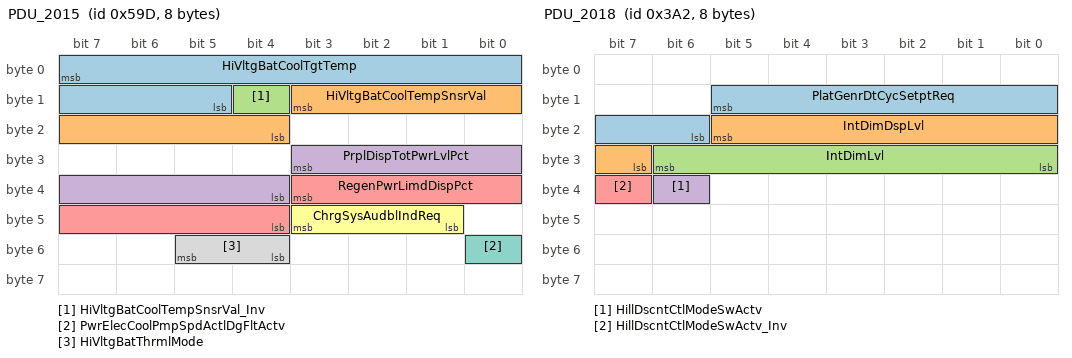
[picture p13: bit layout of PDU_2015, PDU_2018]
BO_ 1437 PDU_2015: 8 Vector__XXX
 SG_ HiVltgBatCoolTgtTemp : 7|11@0+ (0.1,-40) [-40|164.7] "" CGM
 SG_ HiVltgBatCoolTempSnsrVal : 11|8@0+ (1,-40) [-40|215] "Deg C" CGM
 SG_ HiVltgBatCoolTempSnsrVal_Inv : 12|1@0+ (1,0) [0|1] "" CGM
 SG_ PrplDispTotPwrLvlPct : 27|8@0- (1,0) [-128|127] "%" CGM
 SG_ RegenPwrLimdDispPct : 35|8@0- (1,0) [-128|127] "%" CGM
 SG_ ChrgSysAudblIndReq : 43|3@0+ (1,0) [0|7] "" CGM
 SG_ PwrElecCoolPmpSpdActlDgFltActv : 48|1@0+ (1,0) [0|1] "" ECP_E,ECP_S,ECP_S2,ECP_X1
 SG_ HiVltgBatThrmlMode : 53|2@0+ (1,0) [0|2] "" CGM

BO_ 725 PDU_2016: 12 Vector__XXX
 SG_ GPSV_PPSCalcdSpd : 7|8@0+ (1,0) [0|255] "km/h" ACP2_MCU,EOCM,EOCM_HC_Superset,E44,ECP_E
 SG_ GPSV_PPSElvtn : 14|21@0+ (1,-100000) [-100000|1.99715e+006] "cm" ACP2_MCU,EOCM,EOCM_HC_Superset,E44,VDM,ECP_E
 SG_ GPSV_PPSCalcdSpd_Inv : 15|1@0+ (1,0) [0|1] "" ACP2_MCU,EOCM,EOCM_HC_Superset,E44,ECP_E
 SG_ GPSV_PPSHdg : 24|19@0+ (0.001,0) [0|524.287] "deg" ACP2_MCU,EOCM,EOCM_HC_Superset,FCM,E44,VDM,ECP_E
 SG_ GPSV_PPSElvtn_Inv : 25|1@0+ (1,0) [0|1] "" ACP2_MCU,EOCM,EOCM_HC_Superset,E44,VDM,ECP_E
 SG_ GPSQM_PPSPstnDilutnPrcsn : 51|10@0+ (0.1,0) [0|102.3] "m" ACP2_MCU,EOCM,EOCM_HC_Superset,E44
 SG_ GPSQM_PPSPstnDilutnPrcsn_Inv : 52|1@0+ (1,0) [0|1] "" ACP2_MCU,EOCM,EOCM_HC_Superset,E44
 SG_ GPSV_PPSHdg_Inv : 53|1@0+ (1,0) [0|1] "" ACP2_MCU,EOCM,EOCM_HC_Superset,FCM,E44,VDM,ECP_E
 SG_ GPSQM_PPSAbsVelErrEst : 56|5@0+ (1,0) [0|31] "km/hr" ACP2_MCU,EOCM,EOCM_HC_Superset,E44
 SG_ GPSQM_PPSAbsVelErrEst_Inv : 57|1@0+ (1,0) [0|1] "" ACP2_MCU,EOCM,EOCM_HC_Superset,E44
 SG_ GPST_PPSTmOfDy : 66|27@0+ (1,0) [0|1.34218e+008] "ms" ACP2_MCU
 SG_ GPST_PPSTmOfDy_Inv : 67|1@0+ (1,0) [0|1] "" ACP2_MCU

BO_ 720 PDU_2017: 2 Vector__XXX
 SG_ JmpStrtReqd : 7|1@0+ (1,0) [0|1] "" BSM,VICM

BO_ 930 PDU_2018: 8 Vector__XXX
 SG_ PlatGenrDtCycSetptReq : 13|8@0+ (0.39,0) [0|99.45] "%" ECM,PCM
 SG_ IntDimDspLvl : 21|7@0+ (1,0) [0|127] "%" ACP2_MCU,EBCM,EOCM,EOCM_HC_Superset
 SG_ IntDimLvl : 30|7@0+ (1,0) [0|127] "%" EBCM
 SG_ HillDscntCtlModeSwActv : 38|1@0+ (1,0) [0|1] "" EBCM
 SG_ HillDscntCtlModeSwActv_Inv : 39|1@0+ (1,0) [0|1] "" EBCM

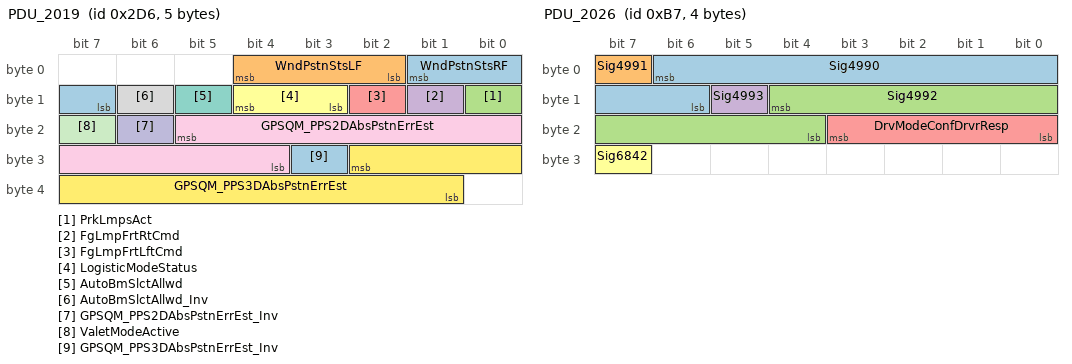
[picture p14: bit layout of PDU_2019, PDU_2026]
BO_ 726 PDU_2019: 5 Vector__XXX
 SG_ WndPstnStsRF : 1|3@0+ (1,0) [0|7] "" ACP2_MCU,DMS,EOCM,EOCM_HC_Superset
 SG_ WndPstnStsLF : 4|3@0+ (1,0) [0|7] "" ACP2_MCU,DMS,EOCM,EOCM_HC_Superset
 SG_ PrkLmpsAct : 8|1@0+ (1,0) [0|1] "" AHL_AFL
 SG_ FgLmpFrtRtCmd : 9|1@0+ (1,0) [0|1] "" FCM
 SG_ FgLmpFrtLftCmd : 10|1@0+ (1,0) [0|1] "" FCM
 SG_ LogisticModeStatus : 12|2@0+ (1,0) [0|3] "" ACP2_MCU,EOCM,EOCM_HC_Superset,FCM
 SG_ AutoBmSlctAllwd : 13|1@0+ (1,0) [0|1] "" FCM
 SG_ AutoBmSlctAllwd_Inv : 14|1@0+ (1,0) [0|1] "" FCM
 SG_ GPSQM_PPS2DAbsPstnErrEst : 21|10@0+ (0.1,0) [0|102.3] "m" ACP2_MCU
 SG_ GPSQM_PPS2DAbsPstnErrEst_Inv : 22|1@0+ (1,0) [0|1] "" ACP2_MCU
 SG_ ValetModeActive : 23|1@0+ (1,0) [0|1] "" EBCM
 SG_ GPSQM_PPS3DAbsPstnErrEst : 26|10@0+ (0.1,0) [0|102.3] "m" ACP2_MCU
 SG_ GPSQM_PPS3DAbsPstnErrEst_Inv : 27|1@0+ (1,0) [0|1] "" ACP2_MCU

BO_ 944 PDU_2020: 6 Vector__XXX
 SG_ EE46etptPrty : 7|2@0+ (1,0) [0|2] "" ECM,PCM

BO_ 1407 PDU_2022: 16 Vector__XXX
 SG_ ChmMngrStat : 7|12@0+ (1,0) [0|4095] "" ACP2_MCU,ADIMa,ADIMb,EOCM,EOCM_HC_Superset,FCM
 SG_ HtdWhlTempAmbtAirEstd : 11|8@0+ (0.5,-40) [-40|87.5] "Deg C" ACP2_MCU,EOCM,EOCM_HC_Superset
 SG_ FrntPCMRspTypCstChgSetReq : 16|3@0+ (1,0) [0|7] "" ACP2_MCU,EOCM,EOCM_HC_Superset,FCM
 SG_ Sig0414 : 19|3@0+ (1,0) [0|7] "" AHL_AFL
 SG_ Sig3505 : 26|3@0+ (1,0) [0|7] "" FCM
 SG_ FrwdImpMtgnOpSlctCstChgSetReq : 29|3@0+ (1,0) [0|7] "" ACP2_MCU,EOCM,EOCM_HC_Superset,FCM
 SG_ Sig7708 : 33|3@0+ (1,0) [0|7] "" FCM
 SG_ Sig4159 : 36|3@0+ (1,0) [0|7] "" AHL_AFL
 SG_ GoNotfrCstChgSetReq : 39|3@0+ (1,0) [0|7] "" ACP2_MCU,EOCM,EOCM_HC_Superset,FCM
 SG_ Sig2570 : 40|2@0+ (1,0) [0|2] "" ECM,PCM
 SG_ DispMeasSysExtnd : 42|2@0+ (1,0) [0|3] "" VICM,FCM
 SG_ CoDrvDrAjrStat : 43|1@0+ (1,0) [0|1] "" ACP2_MCU,EOCM,EOCM_HC_Superset,FCM,E44
 SG_ CoDrvDrAjrStat_Inv : 44|1@0+ (1,0) [0|1] "" ACP2_MCU,EOCM,EOCM_HC_Superset,FCM
 SG_ AutoVehHldSwActv : 45|1@0+ (1,0) [0|1] "" EBCM
 SG_ AutoVehHldSwActv_Inv : 46|1@0+ (1,0) [0|1] "" EBCM
 SG_ LRDrAjrStat_Inv : 48|1@0+ (1,0) [0|1] "" ACP2_MCU,EOCM,EOCM_HC_Superset,FCM
 SG_ LDWCtrlIndStat : 50|2@0+ (1,0) [0|3] "" ACP2_MCU,EOCM,EOCM_HC_Superset,FCM
 SG_ HtdStrgWhlInd : 52|2@0+ (1,0) [0|3] "" ACP2_MCU,EOCM,EOCM_HC_Superset
 SG_ HtdStrgWhlCmd : 54|2@0+ (1,0) [0|3] "" ACP2_MCU,EOCM,EOCM_HC_Superset
 SG_ AE44CrssBckInSftBtnStat : 56|1@0+ (1,0) [0|1] "" ACP2_MCU,EOCM,EOCM_HC_Superset,E44
 SG_ RRDrAjrStat : 57|1@0+ (1,0) [0|1] "" ACP2_MCU,EOCM,EOCM_HC_Superset,FCM,E44
 SG_ RRDrAjrStat_Inv : 58|1@0+ (1,0) [0|1] "" ACP2_MCU,EOCM,EOCM_HC_Superset,FCM
 SG_ Sig4423 : 60|2@0+ (1,0) [0|3] "" NVM
 SG_ Sig4421 : 62|2@0+ (1,0) [0|3] "" NVM
 SG_ LRDrAjrStat : 63|1@0+ (1,0) [0|1] "" ACP2_MCU,EOCM,EOCM_HC_Superset,FCM,E44
 SG_ AE44RghtSftBtnStatIPC : 64|1@0+ (1,0) [0|1] "" ACP2_MCU,EOCM,EOCM_HC_Superset,E44
 SG_ AE44RghtSftBtnStat : 65|1@0+ (1,0) [0|1] "" ACP2_MCU,EOCM,EOCM_HC_Superset,E44
 SG_ AE44PrllPrkSftBtnStat : 66|1@0+ (1,0) [0|1] "" ACP2_MCU,EOCM,EOCM_HC_Superset,E44
 SG_ AE44LftSftBtnStatIPC : 67|1@0+ (1,0) [0|1] "" ACP2_MCU,EOCM,EOCM_HC_Superset,E44
 SG_ AE44LftSftBtnStat : 68|1@0+ (1,0) [0|1] "" ACP2_MCU,EOCM,EOCM_HC_Superset,E44
 SG_ AE44FcStatIPC : 69|1@0+ (1,0) [0|1] "" ACP2_MCU,EOCM,EOCM_HC_Superset,E44
 SG_ AE44FcStatCSM : 70|1@0+ (1,0) [0|1] "" ACP2_MCU,EOCM,EOCM_HC_Superset,E44
 SG_ AE44ExtPrkSftBtnStat : 71|1@0+ (1,0) [0|1] "" ACP2_MCU,EOCM,EOCM_HC_Superset,E44
 SG_ DM5Denied : 72|1@0+ (1,0) [0|1] "" EBCM,ECM,PCM
 SG_ DM4Denied : 73|1@0+ (1,0) [0|1] "" EBCM,ECM,PCM
 SG_ DM3Denied : 74|1@0+ (1,0) [0|1] "" EBCM,ECM,PCM
 SG_ DM2Denied : 75|1@0+ (1,0) [0|1] "" EBCM,ECM,PCM
 SG_ DM1Denied : 76|1@0+ (1,0) [0|1] "" EBCM,ECM,PCM
 SG_ CrshEvntEnbld : 77|1@0+ (1,0) [0|1] "" ACP2_MCU,EOCM,EOCM_HC_Superset,FCM
 SG_ ClsnEvntDatRcrdgTrgrd : 78|1@0+ (1,0) [0|1] "" ACP2_MCU,FCM
 SG_ AE44SrchSftBtnStat : 79|1@0+ (1,0) [0|1] "" ACP2_MCU,EOCM,EOCM_HC_Superset,E44
 SG_ Sig3484 : 80|1@0+ (1,0) [0|1] "" ECM,PCM
 SG_ FlToPsSwAtv : 81|1@0+ (1,0) [0|1] "" AHL_AFL
 SG_ DispMeasSys : 84|1@0+ (1,0) [0|1] "" ACP2_MCU,EBCM,ECM,EOCM,EOCM_HC_Superset,FCM,PCM,ECP_E
 SG_ DM8Denied : 85|1@0+ (1,0) [0|1] "" EBCM,ECM,PCM
 SG_ DM7Denied : 86|1@0+ (1,0) [0|1] "" EBCM,ECM,PCM
 SG_ DM6Denied : 87|1@0+ (1,0) [0|1] "" EBCM,ECM,PCM
 SG_ RstrCstDfltReq : 88|1@0+ (1,0) [0|1] "" AHL_AFL,VICM,FCM
 SG_ LowBmAct : 89|1@0+ (1,0) [0|1] "" ACP2_MCU,AHL_AFL,EOCM,EOCM_HC_Superset,FCM,NVM
 SG_ LDWCSwCktShrtGndDiagFltActv : 90|1@0+ (1,0) [0|1] "" ACP2_MCU,EOCM,EOCM_HC_Superset
 SG_ LDWCSwCktShrtBatOpnDiagFltActv : 91|1@0+ (1,0) [0|1] "" ACP2_MCU,EOCM,EOCM_HC_Superset
 SG_ HtdWhlTempAmbtAirEstdOrgn : 92|1@0+ (1,0) [0|1] "" ACP2_MCU,EOCM,EOCM_HC_Superset
 SG_ HtdStrgWhlEnbl : 93|1@0+ (1,0) [0|1] "" ACP2_MCU,EOCM,EOCM_HC_Superset
 SG_ HtdStrgWhlCtlSrc : 94|1@0+ (1,0) [0|1] "" ACP2_MCU,EOCM,EOCM_HC_Superset
 SG_ HighBmAct : 95|1@0+ (1,0) [0|1] "" AHL_AFL,FCM,NVM
 SG_ SBZAlrtCstCrStVal : 96|3@0+ (1,0) [0|7] "" ACP2_MCU,EOCM,EOCM_HC_Superset,FCM
 SG_ WlcmLgtsActv : 97|1@0+ (1,0) [0|1] "" AHL_AFL,ECM,PCM
 SG_ Sig7578 : 98|1@0+ (1,0) [0|1] "" FCM
 SG_ TargaTopAjrStat : 99|1@0+ (1,0) [0|1] "" EBCM
 SG_ Sig7570 : 100|1@0+ (1,0) [0|1] "" FCM
 SG_ Sig7565 : 101|1@0+ (1,0) [0|1] "" FCM
 SG_ Sig7563 : 102|1@0+ (1,0) [0|1] "" FCM
 SG_ Sig7555 : 103|1@0+ (1,0) [0|1] "" FCM
 SG_ AE44LtSftBtnSts : 104|1@0+ (1,0) [0|1] "" ACP2_MCU,EOCM,EOCM_HC_Superset
 SG_ AE44ExtPrkSftBtnSts : 105|1@0+ (1,0) [0|1] "" ACP2_MCU,EOCM,EOCM_HC_Superset
 SG_ AE44CrssFrntInSftBtnStat : 106|1@0+ (1,0) [0|1] "" ACP2_MCU,EOCM,EOCM_HC_Superset
 SG_ AE44CrsBkInSftBtnSts : 107|1@0+ (1,0) [0|1] "" ACP2_MCU,EOCM,EOCM_HC_Superset
 SG_ Sig0604 : 109|2@0+ (1,0) [0|2] "" ADIMa,ADIMb
 SG_ SuprRmtPrkDctvSoftBtnSts : 112|1@0+ (1,0) [0|1] "" ACP2_MCU,EOCM,EOCM_HC_Superset
 SG_ SD235_ARC : 114|2@0+ (1,0) [0|3] "" ACP2_MCU,EOCM,EOCM_HC_Superset
 SG_ AE44SrchingSftBtnSts : 115|1@0+ (1,0) [0|1] "" ACP2_MCU,EOCM,EOCM_HC_Superset
 SG_ AE44RtSftBtnStsIPC : 116|1@0+ (1,0) [0|1] "" ACP2_MCU,EOCM,EOCM_HC_Superset
 SG_ AE44RtSftBtnSts : 117|1@0+ (1,0) [0|1] "" ACP2_MCU,EOCM,EOCM_HC_Superset
 SG_ AE44ParallelPrkSftBtnSts : 118|1@0+ (1,0) [0|1] "" ACP2_MCU,EOCM,EOCM_HC_Superset
 SG_ AE44LtSftBtnStsIPC : 119|1@0+ (1,0) [0|1] "" ACP2_MCU,EOCM,EOCM_HC_Superset
 SG_ SRPUnableCnctExtSftBtnSts : 123|1@0+ (1,0) [0|1] "" ACP2_MCU,EOCM,EOCM_HC_Superset
 SG_ SRPUnableCnctTryAgnSftBtnSts : 124|1@0+ (1,0) [0|1] "" ACP2_MCU,EOCM,EOCM_HC_Superset
 SG_ SRPSptSeltnRmtSftBtnSts : 125|1@0+ (1,0) [0|1] "" ACP2_MCU,EOCM,EOCM_HC_Superset
 SG_ SRPSptSeltnKeepLkSftBtnSts : 126|1@0+ (1,0) [0|1] "" ACP2_MCU,EOCM,EOCM_HC_Superset
 SG_ SRPSptSeltnAcceptSftBtnSts : 127|1@0+ (1,0) [0|1] "" ACP2_MCU,EOCM,EOCM_HC_Superset

BO_ 1424 PDU_2023: 8 Vector__XXX
 SG_ Sig0076 : 1|6@0+ (1,0) [0|31] "" FCM
 SG_ Sig0074 : 7|6@0+ (1,0) [0|46] "" FCM
 SG_ InfoSysStat : 11|5@0+ (1,0) [0|19] "" VICM
 SG_ Sig0077 : 17|4@0+ (1,0) [0|7] "" FCM
 SG_ CTGI2P_CnvtTopStsAuth_Inv : 18|1@0+ (1,0) [0|1] "" EBCM
 SG_ CTGI2P_CnvtTopStsAuth_DuD : 19|1@0+ (1,0) [0|1] "" EBCM
 SG_ CTGI2P_CnvtTopStsAuth : 22|3@0+ (1,0) [0|5] "" EBCM
 SG_ TDAP_DrvrIdfrAuth : 26|3@0+ (1,0) [0|7] "" ACP2_MCU,AHL_AFL,EBCM,EOCM,EOCM_HC_Superset,FCM
 SG_ Sig0075 : 29|3@0+ (1,0) [0|7] "" FCM
 SG_ Sig0073 : 32|1@0+ (1,0) [0|1] "" FCM
 SG_ Sig0072 : 33|1@0+ (1,0) [0|1] "" FCM
 SG_ TrnSwAct : 35|2@0+ (1,0) [0|2] "" ACP2_MCU,AHL_AFL,ECM,EOCM,EOCM_HC_Superset,FCM,PCM
 SG_ FrtStrgeCmptAjr : 36|1@0+ (1,0) [0|1] "" AHL_AFL,BSM
 SG_ FrtStrgeCmptAjr_Inv : 37|1@0+ (1,0) [0|1] "" AHL_AFL,BSM
 SG_ AE44SftBtnSeltdStatRw : 39|2@0+ (1,0) [0|3] "" ACP2_MCU,EOCM,EOCM_HC_Superset,E44
 SG_ PrkAsstTrHtchPsntCstChgSetReq : 42|3@0+ (1,0) [0|7] "" ACP2_MCU,EOCM,EOCM_HC_Superset
 SG_ PrkAsstOnOffCstChgSetReq : 45|3@0+ (1,0) [0|3] "" ACP2_MCU,EOCM,EOCM_HC_Superset
 SG_ SuprRmtPrkFcsStsVCU : 47|1@0+ (1,0) [0|1] "" ACP2_MCU,EOCM,EOCM_HC_Superset

BO_ 1441 PDU_2024: 32 Vector__XXX
 SG_ RPSU_ExpTmLgth : 2|8@0+ (1,0) [0|255] "min" VICM
 SG_ RPSU_Dy : 7|5@0+ (1,0) [0|31] "day" VICM
 SG_ RPSU_Hr : 10|5@0+ (1,0) [0|31] "hr" VICM
 SG_ RPSU_Mins : 21|6@0+ (1,0) [0|63] "min" VICM
 SG_ RPSU_Secs : 27|6@0+ (1,0) [0|63] "sec" VICM
 SG_ RPSU_Mth : 31|4@0+ (1,0) [0|12] "" VICM
 SG_ RPSU_Yr : 35|8@0+ (1,2000) [2000|2255] "year" VICM
 SG_ RPSU_Sts : 37|2@0+ (1,0) [0|2] "" VICM
 SG_ ONPC_DprtrHrOfDyReq : 40|5@0+ (1,0) [0|31] "h" VICM
 SG_ ONPC_DprtrDyOfWkReq : 43|3@0+ (1,0) [0|7] "" VICM
 SG_ ONPC_DprtrMinOfHrReq : 51|6@0+ (1,0) [0|63] "min" VICM
 SG_ ONPC_TgtChrgLvlReq : 59|7@0+ (1,0) [0|127] "%" VICM
 SG_ ONPC_Req : 61|2@0+ (1,0) [0|2] "" VICM
 SG_ TrlrLgth : 68|12@0+ (1,0) [0|4095] "cm" ACP2_MCU,EOCM,EOCM_HC_Superset,FCM
 SG_ TrlrHght : 72|10@0+ (1,0) [0|1023] "cm" ACP2_MCU,EOCM,EOCM_HC_Superset,FCM
 SG_ TrlrWdth : 94|9@0+ (1,0) [0|511] "cm" ACP2_MCU,EOCM,EOCM_HC_Superset,FCM
 SG_ Sig0631 : 101|8@0+ (1,0) [0|255] "" DMS
 SG_ Sig0632 : 109|8@0+ (1,0) [0|255] "" DMS
 SG_ LnchCtlEngRPMReq : 117|6@0+ (1,0) [0|38] "" EBCM
 SG_ LBCCDRR_PstnNumReq : 120|3@0+ (1,0) [0|4] "" VICM
 SG_ LBCCDRR_ClrStrdPstnReq : 122|2@0+ (1,0) [0|2] "" VICM
 SG_ LnchCtlWhlSlReq : 127|5@0+ (1,0) [0|21] "" EBCM
 SG_ Sig4819 : 129|4@0+ (1,0) [0|15] "" ECM,PCM
 SG_ Sig4614 : 133|4@0+ (1,0) [0|15] "" ECM,PCM
 SG_ AutoLnChgCstChgSetReq : 137|3@0+ (1,0) [0|4] "" ACP2_MCU,EOCM,EOCM_HC_Superset
 SG_ Sig4842 : 141|4@0+ (1,0) [0|15] "" ECM,PCM
 SG_ Sig4867 : 144|3@0+ (1,0) [0|7] "" ECM,PCM
 SG_ LocBsdChrgPstnMdfnReq : 147|3@0+ (1,0) [0|4] "" VICM
 SG_ BrkPadLifeSysDrvrReq : 150|3@0+ (1,0) [0|4] "" EBCM
 SG_ PrkAsstStat : 154|3@0+ (1,0) [0|7] "" ACP2_MCU,CGM,EOCM,EOCM_HC_Superset,FCM
 SG_ Sig4889 : 157|3@0+ (1,0) [0|7] "" ECM,PCM
 SG_ ChrgDatReq : 161|2@0+ (1,0) [0|3] "" VICM
 SG_ ChrgCordThftAlrtCstSetReq : 163|2@0+ (1,0) [0|2] "" VICM
 SG_ LnchCtlModeReq : 169|2@0+ (1,0) [0|3] "" EBCM
 SG_ HillDscntCtlCurrStatReq : 171|2@0+ (1,0) [0|2] "" EBCM
 SG_ ChrgSysAudblIndCstSetReq : 173|2@0+ (1,0) [0|2] "" VICM
 SG_ ChrgPwrLossAlrtCstSetReq : 175|2@0+ (1,0) [0|2] "" VICM
 SG_ Sig4693 : 179|2@0+ (1,0) [0|2] "" ECM,PCM
 SG_ Sig4631 : 181|2@0+ (1,0) [0|2] "" ECM,PCM
 SG_ LocBsdChrgCstSetReq : 183|2@0+ (1,0) [0|2] "" VICM
 SG_ Sig3636 : 184|1@0+ (1,0) [0|1] "" BSM
 SG_ HiVltgBatStopChrgReq : 185|1@0+ (1,0) [0|1] "" VICM
 SG_ Sig3585 : 186|1@0+ (1,0) [0|1] "" AHL_AFL
 SG_ Sig2638 : 187|1@0+ (1,0) [0|1] "" ECM,PCM
 SG_ DrvrSeltdTrlrPrsnt : 188|1@0+ (1,0) [0|1] "" ACP2_MCU,EOCM,EOCM_HC_Superset,FCM
 SG_ Sig0628 : 189|1@0+ (1,0) [0|1] "" NVM
 SG_ Sig7788 : 192|1@0+ (1,0) [0|1] "" PCM,TCM
 SG_ TripBEleclEngyEconRstReqd : 193|1@0+ (1,0) [0|1] "" VICM
 SG_ TripAEleclEngyEconRstReqd : 194|1@0+ (1,0) [0|1] "" VICM
 SG_ StlthModeActv : 195|1@0+ (1,0) [0|1] "" EBCM
 SG_ LnchCtlRelLineLckReqd : 197|1@0+ (1,0) [0|1] "" EBCM
 SG_ LifetmEleclEngyEconRstReqd : 198|1@0+ (1,0) [0|1] "" VICM
 SG_ HzrdReqActv : 199|1@0+ (1,0) [0|1] "" ACP2_MCU,EOCM,EOCM_HC_Superset
 SG_ OvrrdNextPlndCbnPrcndtngReq : 201|2@0+ (1,0) [0|2] "" VICM
 SG_ TrlrProfDrvrReqdSeltn : 206|5@0+ (1,0) [0|21] "" ACP2_MCU,EBCM,EOCM,EOCM_HC_Superset,FCM
 SG_ UIDInStatusSD : 207|1@0+ (1,0) [0|1] "" EBCM

BO_ 1529 PDU_2025: 32 Vector__XXX
 SG_ TmSyncMsg : 7|40@0+ (100,0) [0|1.09951e+014] "ms" AHL_AFL,AHS,ARS,BSM,VECM,VICM,BSM_MH,DCM,DMS,ECM,ECP_MC,EPSRAa,EPS,EPSb,FCM,HUD_CAN,LIB1,NVM,PCM,RDCM,TCCM,TCM,VDM,ECP_E,ECP_S,ECP_S2,ECP_X1
 SG_ UTCHrs : 41|5@0+ (1,0) [0|31] "hour" ACP2_MCU,ECM,EOCM,EOCM_HC_Superset,FCM,PCM,VDM
 SG_ UTCDay_Inv : 42|1@0+ (1,0) [0|1] "" ACP2_MCU,EOCM,EOCM_HC_Superset,FCM,VDM
 SG_ UTCDay : 47|5@0+ (1,0) [0|31] "day" ACP2_MCU,ECM,EOCM,EOCM_HC_Superset,FCM,PCM,VDM
 SG_ UTCMin : 51|6@0+ (1,0) [0|63] "minutes" ACP2_MCU,ECM,EOCM,EOCM_HC_Superset,FCM,PCM,VDM
 SG_ UTCHrs_Inv : 52|1@0+ (1,0) [0|1] "" ACP2_MCU,EOCM,EOCM_HC_Superset,FCM,VDM
 SG_ UTCMth_Inv : 56|1@0+ (1,0) [0|1] "" ACP2_MCU,EOCM,EOCM_HC_Superset,FCM,VDM
 SG_ UTCMth : 60|4@0+ (1,0) [0|12] "" ACP2_MCU,ECM,EOCM,EOCM_HC_Superset,FCM,PCM,VDM
 SG_ UTCMin_Inv : 61|1@0+ (1,0) [0|1] "" ACP2_MCU,EOCM,EOCM_HC_Superset,FCM,VDM
 SG_ UTCYr : 64|8@0+ (1,2000) [2000|2255] "year" ACP2_MCU,ECM,EOCM,EOCM_HC_Superset,FCM,PCM,VDM
 SG_ UTCSec_Inv : 65|1@0+ (1,0) [0|1] "" ACP2_MCU,EOCM,EOCM_HC_Superset,FCM,VDM
 SG_ UTCSec : 71|6@0+ (1,0) [0|63] "seconds" ACP2_MCU,ECM,EOCM,EOCM_HC_Superset,FCM,PCM,VDM
 SG_ UTCYr_Inv : 72|1@0+ (1,0) [0|1] "" ACP2_MCU,EOCM,EOCM_HC_Superset,FCM,VDM
 SG_ EngIdleActvTm : 117|24@0+ (1,0) [0|1.67772e+007] "min" ECM,PCM
 SG_ EngRunActvTm : 141|24@0+ (1,0) [0|1.67772e+007] "min" ECM,PCM
 SG_ ClmCtlTmToRchCbnCmfEstd : 165|12@0+ (1,0) [0|4095] "sec" BSM
 SG_ ClmCtlPwrToMntCbnCmf : 169|10@0+ (0.1,0) [0|102.3] "KW" BSM
 SG_ ClmCtlPwrToRchCbnCmf : 191|10@0+ (0.1,0) [0|102.3] "KW" BSM
 SG_ HtrCoreInltClntTmpCalc : 196|8@0+ (1,-40) [-40|215] "deg C" BSM
 SG_ HtrCoreInltClntTmpCalc_Inv : 197|1@0+ (1,0) [0|1] "" BSM
 SG_ Sig3482 : 204|8@0+ (0.1,0) [0|25.5] "km/L" ECM,PCM
 SG_ ClmCtlCustSetChgd : 224|1@0+ (1,0) [0|1] "" BSM
 SG_ ClmCtlCmfSetRchd : 225|1@0+ (1,0) [0|1] "" BSM
 SG_ ClmCtlCustSeltn : 227|2@0+ (1,0) [0|3] "" BSM
 SG_ RVCOprtgMd : 231|4@0+ (1,0) [0|10] "" FOPM
 SG_ ExtEnvCondChgDtd : 239|1@0+ (1,0) [0|1] "" BSM

BO_ 183 PDU_2026: 4 Vector__XXX
 SG_ Sig4990 : 6|9@0- (1,0) [-256|255] "mm" AHL_AFL
 SG_ Sig4991 : 7|1@0+ (1,0) [0|1] "" AHL_AFL
 SG_ Sig4992 : 12|9@0- (1,0) [-256|255] "mm" AHL_AFL
 SG_ Sig4993 : 13|1@0+ (1,0) [0|1] "" AHL_AFL
 SG_ DrvModeConfDrvrResp : 19|4@0+ (1,0) [0|15] "" EBCM
 SG_ Sig6842 : 31|1@0+ (1,0) [0|1] "" AHL_AFL

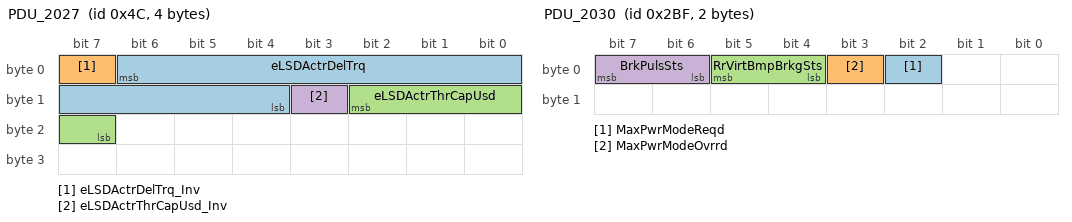
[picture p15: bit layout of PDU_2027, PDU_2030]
BO_ 76 PDU_2027: 4 Vector__XXX
 SG_ eLSDActrDelTrq : 6|11@0+ (5,-5120) [-5120|5115] "Nm" ADIMa,ADIMb,CGM,EBCM,ECP_E
 SG_ eLSDActrDelTrq_Inv : 7|1@0+ (1,0) [0|1] "" ADIMa,ADIMb,CGM,EBCM,ECP_E
 SG_ eLSDActrThrCapUsd : 10|4@0+ (6.7,0) [0|100.5] "%" ADIMa,ADIMb,CGM,EBCM,ECP_E
 SG_ eLSDActrThrCapUsd_Inv : 11|1@0+ (1,0) [0|1] "" ADIMa,ADIMb,CGM,EBCM,ECP_E

BO_ 1480 PDU_2028: 6 Vector__XXX
 SG_ Sig8079 : 6|8@0+ (0.4,0) [0|102] "%" CGM
 SG_ Sig8080 : 7|1@0+ (1,0) [0|1] "" CGM

BO_ 192 PDU_2029: 2 Vector__XXX
 SG_ BrkSysRdGrdAccel : 6|7@0+ (0.0981,-6.2784) [-6.2784|6.1803] "m/s^2" ACP2_MCU,EOCM,EOCM_HC_Superset,FCM
 SG_ BrkSysRdGrdAccel_Inv : 7|1@0+ (1,0) [0|1] "" ACP2_MCU,EOCM,EOCM_HC_Superset,FCM

BO_ 703 PDU_2030: 2 Vector__XXX
 SG_ MaxPwrModeReqd : 2|1@0+ (1,0) [0|1] "" CGM
 SG_ MaxPwrModeOvrrd : 3|1@0+ (1,0) [0|1] "" CGM
 SG_ RrVirtBmpBrkgSts : 5|2@0+ (1,0) [0|2] "" ACP2_MCU,EOCM,EOCM_HC_Superset,FCM
 SG_ BrkPulsSts : 7|2@0+ (1,0) [0|3] "" ACP2_MCU,EOCM,EOCM_HC_Superset,FCM

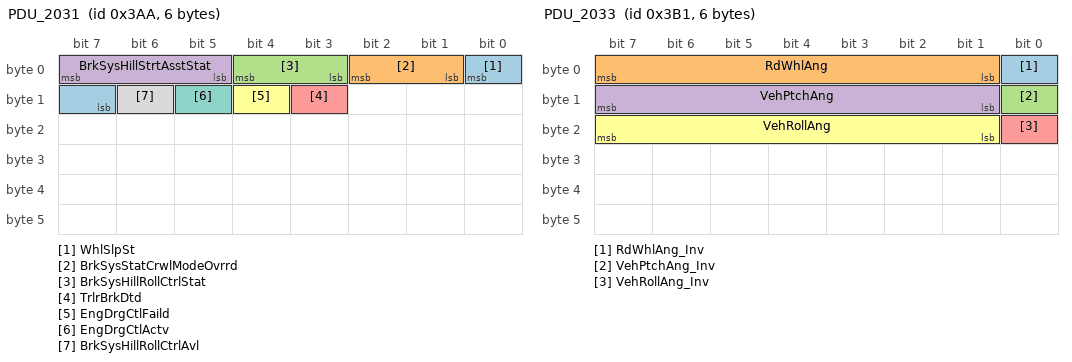
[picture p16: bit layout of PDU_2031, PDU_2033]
BO_ 938 PDU_2031: 6 Vector__XXX
 SG_ WhlSlpSt : 0|2@0+ (1,0) [0|3] "" ACP2_MCU,CGM,ECM,PCM,ECP_E,ECP_S,ECP_S2,ECP_X1
 SG_ BrkSysStatCrwlModeOvrrd : 2|2@0+ (1,0) [0|2] "" ECM,PCM,ECP_E
 SG_ BrkSysHillRollCtrlStat : 4|2@0+ (1,0) [0|3] "" PCM,RDCM,TCCM,TCM
 SG_ BrkSysHillStrtAsstStat : 7|3@0+ (1,0) [0|7] "" CGM,PCM,RDCM,TCCM,TCM
 SG_ TrlrBrkDtd : 11|1@0+ (1,0) [0|1] "" ACP2_MCU,ADIMa,ADIMb,CGM,EOCM,EOCM_HC_Superset,FCM,ECP_E
 SG_ EngDrgCtlFaild : 12|1@0+ (1,0) [0|1] "" PCM,TCM
 SG_ EngDrgCtlActv : 13|1@0+ (1,0) [0|1] "" PCM,TCM
 SG_ BrkSysHillRollCtrlAvl : 14|1@0+ (1,0) [0|1] "" PCM,TCM

BO_ 709 PDU_2032: 2 Vector__XXX
 SG_ TrlrBrkgFOut : 7|8@0+ (0.392157,0) [0|100] "%" CGM

BO_ 945 PDU_2033: 6 Vector__XXX
 SG_ RdWhlAng_Inv : 0|1@0+ (1,0) [0|1] "" ACP2_MCU,CGM
 SG_ RdWhlAng : 7|7@0- (0.703125,0) [-45|44.2969] "deg" ACP2_MCU,CGM
 SG_ VehPtchAng_Inv : 8|1@0+ (1,0) [0|1] "" ACP2_MCU,CGM
 SG_ VehPtchAng : 15|7@0- (0.703125,0) [-45|44.2969] "deg" ACP2_MCU,CGM
 SG_ VehRollAng_Inv : 16|1@0+ (1,0) [0|1] "" ACP2_MCU,CGM
 SG_ VehRollAng : 23|7@0- (0.703125,0) [-45|44.2969] "deg" ACP2_MCU,CGM

BO_ 1414 PDU_2034: 6 Vector__XXX
 SG_ BSTGR_ReqdGr : 5|4@0+ (1,0) [0|10] "" PCM,TCM
 SG_ BSTGR_ReqTyp : 7|2@0+ (1,0) [0|3] "" PCM,TCM

BO_ 1430 PDU_2035: 6 Vector__XXX
 SG_ RrCrsTrfcBrkgSysSts : 7|2@0+ (1,0) [0|2] "" CGM

BO_ 1481 PDU_2036: 8 Vector__XXX
 SG_ BSCERDTC_CdNum : 7|12@0+ (1,0) [0|4095] "" ECM,PCM,ECP_E
 SG_ BSCERDTC_SysDes : 11|4@0+ (1,0) [0|15] "" ECM,PCM,ECP_E
 SG_ EngMntPrfMdRq : 16|3@0+ (1,0) [0|7] "" ECM,PCM
 SG_ ACCPrfMdRq : 19|3@0+ (1,0) [0|7] "" ACP2_MCU,EOCM,EOCM_HC_Superset,FCM
 SG_ TireRRLoTracIndOn : 20|1@0+ (1,0) [0|1] "" CGM
 SG_ TireRFLoTracIndOn : 21|1@0+ (1,0) [0|1] "" CGM
 SG_ TireLRLoTracIndOn : 22|1@0+ (1,0) [0|1] "" CGM
 SG_ TireLFLoTracIndOn : 23|1@0+ (1,0) [0|1] "" CGM
 SG_ RrStrPrfMdRq : 26|3@0+ (1,0) [0|7] "" ARS
 SG_ ExhSndPrfMdRq : 29|3@0+ (1,0) [0|7] "" ECM,PCM
 SG_ WthrSnwModeBrkPedVisDispVal : 33|3@0+ (1,0) [0|7] "" CGM
 SG_ WthrSnwModeActvAeroVisDispVal : 36|3@0+ (1,0) [0|7] "" CGM
 SG_ StrPrfMdRq : 39|3@0+ (1,0) [0|7] "" AHS,CGM,EPS,EPSb,RDCM,TCCM
 SG_ WthrSnwModePwrtrnVisDispVal : 40|3@0+ (1,0) [0|7] "" CGM
 SG_ WthrSnwModeESCVisDispVal : 43|3@0+ (1,0) [0|7] "" CGM
 SG_ WthrSnwModeDrvlineVisDispVal : 46|3@0+ (1,0) [0|7] "" CGM
 SG_ WthrSnwModeSndVisDispVal : 50|3@0+ (1,0) [0|7] "" CGM
 SG_ WthrSnwModeRideHghtVisDispVal : 53|3@0+ (1,0) [0|7] "" CGM
 SG_ DrvModeConfIndReq : 58|3@0+ (1,0) [0|7] "" CGM
 SG_ ESCPrs : 59|1@0+ (1,0) [0|1] "" ECM,PCM,TCM
 SG_ BrkSysCtlEmsnsRltdMalfActv : 60|1@0+ (1,0) [0|1] "" ECM,PCM,ECP_E
 SG_ WthrSnwModeSpnsnVisDispVal : 63|3@0+ (1,0) [0|7] "" CGM

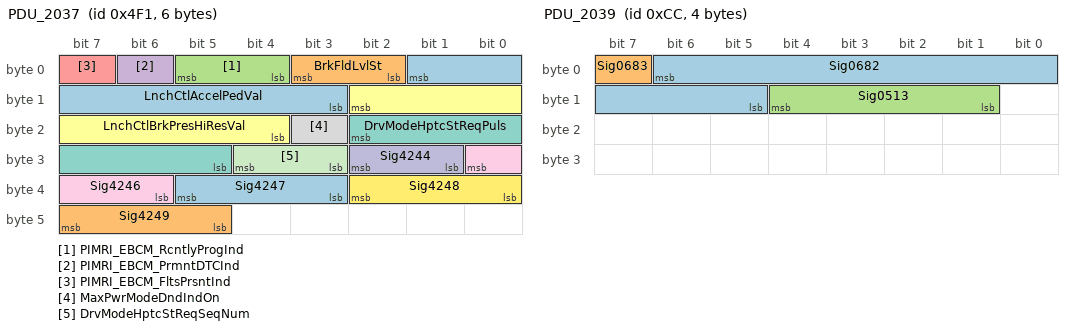
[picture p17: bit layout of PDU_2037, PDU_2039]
BO_ 1265 PDU_2037: 6 Vector__XXX
 SG_ LnchCtlAccelPedVal : 1|7@0+ (1,0) [0|127] "%" CGM
 SG_ BrkFldLvlSt : 3|2@0+ (1,0) [0|2] "" CGM,ECM,PCM,VDM,ECP_E
 SG_ PIMRI_EBCM_RcntlyProgInd : 5|2@0+ (1,0) [0|3] "" ECM,PCM,ECP_E
 SG_ PIMRI_EBCM_PrmntDTCInd : 6|1@0+ (1,0) [0|1] "" ECM,PCM,ECP_E
 SG_ PIMRI_EBCM_FltsPrsntInd : 7|1@0+ (1,0) [0|1] "" ECM,PCM,ECP_E
 SG_ LnchCtlBrkPresHiResVal : 10|7@0+ (1,0) [0|127] "%" CGM
 SG_ DrvModeHptcStReqPuls : 18|6@0+ (1,0) [0|63] "" CGM
 SG_ MaxPwrModeDndIndOn : 19|1@0+ (1,0) [0|1] "" CGM
 SG_ Sig4246 : 24|3@0+ (1,0) [0|4] "" ADIMa,ADIMb
 SG_ Sig4244 : 26|2@0+ (1,0) [0|3] "" ADIMa,ADIMb
 SG_ DrvModeHptcStReqSeqNum : 28|2@0+ (1,0) [0|3] "" CGM
 SG_ Sig4248 : 34|3@0+ (1,0) [0|4] "" ADIMa,ADIMb
 SG_ Sig4247 : 37|3@0+ (1,0) [0|4] "" ADIMa,ADIMb
 SG_ Sig4249 : 47|3@0+ (1,0) [0|4] "" ADIMa,ADIMb

BO_ 69 PDU_2038: 24 Vector__XXX
 SG_ Sig2438 : 7|15@0+ (2,-22534) [-22534|43000] "Nm" TCM
 SG_ Sig2617 : 8|15@0+ (2,-22534) [-22534|43000] "" TCM
 SG_ Sig0676 : 24|12@0+ (0.5,-848) [-848|1199.5] "Nm" TCM
 SG_ Sig0677 : 25|1@0+ (1,0) [0|1] "" TCM
 SG_ Sig0678 : 43|12@0+ (0.5,-848) [-848|1199.5] "Nm" TCM
 SG_ Sig0679 : 44|1@0+ (1,0) [0|1] "" TCM
 SG_ Sig0680 : 62|12@0+ (0.5,-848) [-848|1199.5] "Nm" TCM
 SG_ Sig0681 : 63|1@0+ (1,0) [0|1] "" TCM
 SG_ Sig0684 : 65|12@0+ (0.5,-848) [-848|1199.5] "Nm" TCM
 SG_ Sig0685 : 66|1@0+ (1,0) [0|1] "" TCM
 SG_ Sig0686 : 84|12@0+ (0.5,-848) [-848|1199.5] "Nm" TCM
 SG_ Sig0687 : 85|1@0+ (1,0) [0|1] "" TCM
 SG_ Sig2629 : 88|1@0+ (1,0) [0|1] "" TCM
 SG_ Sig2628 : 103|12@0+ (0.5,-848) [-848|1199.5] "Nm" TCM
 SG_ EngPrdctStdyStTrq : 106|12@0+ (0.5,-848) [-848|1199.5] "Nm" EBCM,TCM
 SG_ EngPrdctStdyStTrq_Inv : 107|1@0+ (1,0) [0|1] "" EBCM,TCM
 SG_ Sig2664 : 126|11@0+ (0.00390625,0) [0|7.99609] "" TCM
 SG_ Sig2665 : 131|11@0+ (0.00390625,0) [0|7.99609] "" TCM
 SG_ Sig2610 : 136|8@0+ (0.00390625,0) [0|0.996094] "" TCM
 SG_ Sig2612 : 144|8@0+ (0.00390625,0) [0|0.996094] "" TCM
 SG_ Sig0606 : 152|3@0+ (1,0) [0|7] "" TCM
 SG_ Sig2624 : 162|3@0+ (1,0) [0|7] "" TCM
 SG_ Sig0607 : 165|3@0+ (1,0) [0|7] "" TCM
 SG_ Sig2657 : 169|3@0+ (1,0) [0|6] "" TCM
 SG_ Sig2656 : 172|3@0+ (1,0) [0|7] "" TCM
 SG_ Sig2625 : 175|3@0+ (1,0) [0|6] "" TCM
 SG_ Sig7777 : 178|1@0+ (1,0) [0|1] "" TCM
 SG_ Sig7778 : 179|1@0+ (1,0) [0|1] "" TCM
 SG_ Sig2622 : 180|1@0+ (1,0) [0|1] "" CGM,TCM
 SG_ Sig2609 : 181|1@0+ (1,0) [0|1] "" TCM
 SG_ Sig0474 : 182|1@0+ (1,0) [0|1] "" TCM

BO_ 204 PDU_2039: 4 Vector__XXX
 SG_ Sig0682 : 6|10@0- (0.5,0) [-256|255.5] "Nm" TCM
 SG_ Sig0683 : 7|1@0+ (1,0) [0|1] "" TCM
 SG_ Sig0513 : 12|4@0+ (1,0) [0|15] "counts" ECP_MC

BO_ 681 PDU_2040: 2 Vector__XXX
 SG_ Sig2613 : 5|1@0+ (1,0) [0|1] "" CGM,TCM
 SG_ Sig2611 : 7|2@0+ (1,0) [0|3] "" CGM,RDCM,TCCM,TCM

BO_ 933 PDU_2041: 16 Vector__XXX
 SG_ Sig2670 : 7|16@0+ (0.25,0) [0|16383.8] "rpm" TCM
 SG_ Sig2522 : 18|4@0+ (1,0) [0|15] "" CGM
 SG_ Sig2521 : 19|1@0+ (1,0) [0|1] "" CGM
 SG_ Sig2520 : 23|4@0+ (1,0) [0|15] "" CGM
 SG_ Sig2669 : 28|10@0+ (8,0) [0|8184] "rpm" TCM
 SG_ Sig2523 : 30|2@0+ (1,0) [0|2] "" CGM
 SG_ EASSI_StrtStpSt : 32|2@0+ (1,0) [0|3] "" ACP2_MCU,AHL_AFL,BSM,VICM,BSM_MH,CGM,EBCM,EOCM,EOCM_HC_Superset,FCM,RDCM,TCCM,TCM,ECP_X1
 SG_ EASSI_StlDtd : 33|1@0+ (1,0) [0|1] "" EBCM,TCM,ECP_X1
 SG_ EASSI_FlRqOn : 34|1@0+ (1,0) [0|1] "" CGM,TCM
 SG_ Sig2413 : 40|8@0- (0.78125,0) [-100|99.2188] "%" CGM
 SG_ Sig2466 : 41|1@0+ (1,0) [0|1] "" TCM
 SG_ Sig2465 : 42|1@0+ (1,0) [0|1] "" TCM,ECP_X1
 SG_ Sig2464 : 43|1@0+ (1,0) [0|1] "" TCM,ECP_X1
 SG_ Sig2463 : 46|3@0+ (1,0) [0|7] "" TCM,ECP_X1
 SG_ Sig2623 : 48|8@0+ (8,0) [0|2040] "rpm" TCM
 SG_ GenFldDutCyc : 56|8@0+ (0.392157,0) [0|100] "%" CGM
 SG_ Sig2584 : 64|7@0+ (1,0) [0|127] "%" CGM
 SG_ Sig2554 : 73|2@0+ (1,0) [0|3] "" TCM
 SG_ Sig2562 : 80|3@0+ (1,0) [0|1] "" TCM
 SG_ Sig2561 : 83|3@0+ (1,0) [0|1] "" TCM
 SG_ Sig2555 : 87|4@0+ (1,0) [0|10] "" TCM
 SG_ Sig7805 : 90|3@0+ (1,0) [0|2] "" ECP_X1
 SG_ Sig2608 : 93|3@0+ (1,0) [0|5] "" CGM,TCM
 SG_ EngAtStpNtPrbl : 96|1@0+ (1,0) [0|1] "" CGM,TCM
 SG_ Sig0470 : 97|1@0+ (1,0) [0|1] "" TCM
 SG_ Sig2589 : 99|2@0+ (1,0) [0|2] "" TCM
 SG_ Sig2571 : 101|2@0+ (1,0) [0|2] "" CGM
 SG_ CltTpTrvAchv : 102|1@0+ (1,0) [0|1] "" ACP2_MCU,CGM,EBCM,EOCM,EOCM_HC_Superset,FCM
 SG_ CltTpTrvAchv_Inv : 103|1@0+ (1,0) [0|1] "" ACP2_MCU,CGM,EBCM,EOCM,EOCM_HC_Superset,FCM
 SG_ Sig8060 : 104|1@0+ (1,0) [0|1] "" TCM
 SG_ Sig7665 : 105|1@0+ (1,0) [0|1] "" TCM
 SG_ Sig5015 : 106|1@0+ (1,0) [0|1] "" CGM,TCM
 SG_ GlwPlgCrnkDlyActv : 107|1@0+ (1,0) [0|1] "" CGM
 SG_ Sig2662 : 108|1@0+ (1,0) [0|1] "" TCM
 SG_ Sig2632 : 109|1@0+ (1,0) [0|1] "" TCM
 SG_ Sig2616 : 110|1@0+ (1,0) [0|1] "" TCM
 SG_ Sig2603 : 111|1@0+ (1,0) [0|1] "" TCM
 SG_ Sig2560 : 114|7@0+ (1,0) [0|127] "%" TCM
 SG_ Sig2559 : 117|3@0+ (1,0) [0|5] "" TCM
 SG_ Sig2556 : 119|2@0+ (1,0) [0|3] "" TCM
 SG_ Sig0665 : 121|1@0+ (1,0) [0|1] "" ECP_X1
 SG_ Sig5717 : 123|2@0+ (1,0) [0|3] "" ECP_X1

BA_DEF_ SG_  "SignalType" STRING ;
BA_DEF_ SG_  "SignalLongName" STRING ;
BA_DEF_ BO_  "GenMsgCycleTime" INT 0 10000;
BA_DEF_ BO_  "GenMsgSendType" ENUM "cyclicX","spontanX","cyclicIfActiveX","spontanWithDelay","cyclicAndSpontanX","cyclicAndSpontanWithDelay","spontanWithRepetition","cyclicIfActiveAndSpontanWD";
BA_DEF_ BO_  "VFrameFormat" ENUM  "StandardCAN","ExtendedCAN","reserved","reserved","reserved","reserved","reserved","reserved","reserved","reserved","reserved","reserved","reserved","reserved","StandardCAN_FD","ExtendedCAN_FD";
BA_DEF_DEF_  "SignalType" "";
BA_DEF_DEF_  "SignalLongName" "";
BA_DEF_DEF_  "GenMsgCycleTime" 0;
BA_DEF_DEF_  "GenMsgSendType" "cyclicX";
BA_DEF_DEF_  "VFrameFormat" "StandardCAN";
BA_ "GenMsgCycleTime" BO_ 727 100;
BA_ "VFrameFormat" BO_ 727 14;
BA_ "GenMsgCycleTime" BO_ 1385 3500;
BA_ "VFrameFormat" BO_ 1385 14;
BA_ "GenMsgCycleTime" BO_ 1315 1000;
BA_ "VFrameFormat" BO_ 1315 14;
BA_ "GenMsgCycleTime" BO_ 2147745832 1000;
BA_ "VFrameFormat" BO_ 916 14;
BA_ "GenMsgCycleTime" BO_ 230 25;
BA_ "VFrameFormat" BO_ 230 14;
BA_ "VFrameFormat" BO_ 915 14;
BA_ "GenMsgCycleTime" BO_ 39 20;
BA_ "VFrameFormat" BO_ 39 14;
BA_ "GenMsgCycleTime" BO_ 1384 3500;
BA_ "VFrameFormat" BO_ 1384 14;
BA_ "GenMsgCycleTime" BO_ 1314 500;
BA_ "VFrameFormat" BO_ 1314 14;
BA_ "VFrameFormat" BO_ 914 14;
BA_ "GenMsgCycleTime" BO_ 87 10;
BA_ "VFrameFormat" BO_ 87 14;
BA_ "VFrameFormat" BO_ 687 14;
BA_ "GenMsgCycleTime" BO_ 109 20;
BA_ "VFrameFormat" BO_ 109 14;
BA_ "GenMsgCycleTime" BO_ 38 20;
BA_ "VFrameFormat" BO_ 38 14;
BA_ "GenMsgCycleTime" BO_ 956 100;
BA_ "VFrameFormat" BO_ 956 14;
BA_ "GenMsgCycleTime" BO_ 729 100;
BA_ "VFrameFormat" BO_ 729 14;
BA_ "GenMsgCycleTime" BO_ 1285 1000;
BA_ "VFrameFormat" BO_ 1285 14;
BA_ "GenMsgCycleTime" BO_ 704 100;
BA_ "VFrameFormat" BO_ 704 14;
BA_ "GenMsgCycleTime" BO_ 1419 1000;
BA_ "VFrameFormat" BO_ 1419 14;
BA_ "GenMsgCycleTime" BO_ 1501 1000;
BA_ "VFrameFormat" BO_ 1501 14;
BA_ "GenMsgCycleTime" BO_ 1427 1000;
BA_ "VFrameFormat" BO_ 1427 14;
BA_ "GenMsgCycleTime" BO_ 1428 1000;
BA_ "VFrameFormat" BO_ 1428 14;
BA_ "GenMsgCycleTime" BO_ 1420 1000;
BA_ "VFrameFormat" BO_ 1420 14;
BA_ "GenMsgCycleTime" BO_ 1432 1000;
BA_ "VFrameFormat" BO_ 1432 14;
BA_ "GenMsgCycleTime" BO_ 706 100;
BA_ "VFrameFormat" BO_ 706 14;
BA_ "GenMsgCycleTime" BO_ 1410 1000;
BA_ "VFrameFormat" BO_ 1410 14;
BA_ "GenMsgCycleTime" BO_ 1444 1000;
BA_ "VFrameFormat" BO_ 1444 14;
BA_ "GenMsgCycleTime" BO_ 182 50;
BA_ "VFrameFormat" BO_ 182 14;
BA_ "GenMsgCycleTime" BO_ 708 100;
BA_ "VFrameFormat" BO_ 708 14;
BA_ "GenMsgCycleTime" BO_ 1412 1000;
BA_ "VFrameFormat" BO_ 1412 14;
BA_ "GenMsgCycleTime" BO_ 162 50;
BA_ "VFrameFormat" BO_ 162 14;
BA_ "GenMsgCycleTime" BO_ 164 50;
BA_ "VFrameFormat" BO_ 164 14;
BA_ "GenMsgCycleTime" BO_ 168 50;
BA_ "VFrameFormat" BO_ 168 14;
BA_ "GenMsgCycleTime" BO_ 2147745821 1000;
BA_ "GenMsgCycleTime" BO_ 1421 1000;
BA_ "VFrameFormat" BO_ 1421 14;
BA_ "GenMsgCycleTime" BO_ 1383 3500;
BA_ "VFrameFormat" BO_ 1383 14;
BA_ "GenMsgCycleTime" BO_ 1323 1000;
BA_ "VFrameFormat" BO_ 1323 14;
BA_ "GenMsgCycleTime" BO_ 1027 1000;
BA_ "VFrameFormat" BO_ 1027 14;
BA_ "GenMsgCycleTime" BO_ 75 10;
BA_ "VFrameFormat" BO_ 75 14;
BA_ "GenMsgCycleTime" BO_ 32 10;
BA_ "VFrameFormat" BO_ 32 14;
BA_ "GenMsgCycleTime" BO_ 739 100;
BA_ "VFrameFormat" BO_ 739 14;
BA_ "GenMsgCycleTime" BO_ 946 500;
BA_ "VFrameFormat" BO_ 946 14;
BA_ "GenMsgCycleTime" BO_ 701 100;
BA_ "VFrameFormat" BO_ 701 14;
BA_ "GenMsgCycleTime" BO_ 1406 1000;
BA_ "VFrameFormat" BO_ 1406 14;
BA_ "GenMsgCycleTime" BO_ 1422 1000;
BA_ "VFrameFormat" BO_ 1422 14;
BA_ "GenMsgCycleTime" BO_ 206 25;
BA_ "VFrameFormat" BO_ 206 14;
BA_ "GenMsgCycleTime" BO_ 722 100;
BA_ "VFrameFormat" BO_ 722 14;
BA_ "GenMsgCycleTime" BO_ 1526 1000;
BA_ "VFrameFormat" BO_ 1526 14;
BA_ "GenMsgCycleTime" BO_ 721 100;
BA_ "VFrameFormat" BO_ 721 14;
BA_ "GenMsgCycleTime" BO_ 1527 1000;
BA_ "VFrameFormat" BO_ 1527 14;
BA_ "GenMsgCycleTime" BO_ 112 20;
BA_ "VFrameFormat" BO_ 112 14;
BA_ "GenMsgCycleTime" BO_ 1436 1000;
BA_ "VFrameFormat" BO_ 1436 14;
BA_ "GenMsgCycleTime" BO_ 1528 1000;
BA_ "VFrameFormat" BO_ 1528 14;
BA_ "GenMsgCycleTime" BO_ 928 250;
BA_ "VFrameFormat" BO_ 928 14;
BA_ "GenMsgCycleTime" BO_ 723 100;
BA_ "VFrameFormat" BO_ 723 14;
BA_ "GenMsgCycleTime" BO_ 1437 1000;
BA_ "VFrameFormat" BO_ 1437 14;
BA_ "GenMsgCycleTime" BO_ 725 100;
BA_ "VFrameFormat" BO_ 725 14;
BA_ "GenMsgCycleTime" BO_ 720 100;
BA_ "VFrameFormat" BO_ 720 14;
BA_ "GenMsgCycleTime" BO_ 930 250;
BA_ "VFrameFormat" BO_ 930 14;
BA_ "GenMsgCycleTime" BO_ 726 100;
BA_ "VFrameFormat" BO_ 726 14;
BA_ "GenMsgCycleTime" BO_ 944 250;
BA_ "VFrameFormat" BO_ 944 14;
BA_ "GenMsgCycleTime" BO_ 1407 1000;
BA_ "VFrameFormat" BO_ 1407 14;
BA_ "GenMsgCycleTime" BO_ 1424 1000;
BA_ "VFrameFormat" BO_ 1424 14;
BA_ "GenMsgCycleTime" BO_ 1441 1000;
BA_ "VFrameFormat" BO_ 1441 14;
BA_ "GenMsgCycleTime" BO_ 1529 1000;
BA_ "VFrameFormat" BO_ 1529 14;
BA_ "GenMsgCycleTime" BO_ 183 50;
BA_ "VFrameFormat" BO_ 183 14;
BA_ "GenMsgCycleTime" BO_ 76 10;
BA_ "VFrameFormat" BO_ 76 14;
BA_ "GenMsgCycleTime" BO_ 1480 1000;
BA_ "VFrameFormat" BO_ 1480 14;
BA_ "GenMsgCycleTime" BO_ 192 30;
BA_ "VFrameFormat" BO_ 192 14;
BA_ "GenMsgCycleTime" BO_ 703 100;
BA_ "VFrameFormat" BO_ 703 14;
BA_ "GenMsgCycleTime" BO_ 938 250;
BA_ "VFrameFormat" BO_ 938 14;
BA_ "GenMsgCycleTime" BO_ 709 100;
BA_ "VFrameFormat" BO_ 709 14;
BA_ "GenMsgCycleTime" BO_ 945 250;
BA_ "VFrameFormat" BO_ 945 14;
BA_ "GenMsgCycleTime" BO_ 1414 1000;
BA_ "VFrameFormat" BO_ 1414 14;
BA_ "GenMsgCycleTime" BO_ 1430 1000;
BA_ "VFrameFormat" BO_ 1430 14;
BA_ "GenMsgCycleTime" BO_ 1481 1000;
BA_ "VFrameFormat" BO_ 1481 14;
BA_ "GenMsgCycleTime" BO_ 1265 1000;
BA_ "VFrameFormat" BO_ 1265 14;
BA_ "GenMsgCycleTime" BO_ 69 12.5;
BA_ "VFrameFormat" BO_ 69 14;
BA_ "GenMsgCycleTime" BO_ 204 25;
BA_ "VFrameFormat" BO_ 204 14;
BA_ "GenMsgCycleTime" BO_ 681 100;
BA_ "VFrameFormat" BO_ 681 14;
BA_ "GenMsgCycleTime" BO_ 933 250;
BA_ "VFrameFormat" BO_ 933 14;
BA_ "SignalLongName" SG_ 727 GPSC_PPSLat "Global Positioning System Coordinates : Precise Positioning System Latitude";
BA_ "SignalLongName" SG_ 727 GPSC_PPSLong "Global Positioning System Coordinates : Precise Positioning System Longitude";
BA_ "SignalType" SG_ 727 GPSC_PPSLat_Inv "ENM";
BA_ "SignalLongName" SG_ 727 GPSC_PPSLat_Inv "Global Positioning System Coordinates : Precise Positioning System Latitude Invalid";
BA_ "SignalType" SG_ 727 GPSC_PPSLong_Inv "ENM";
BA_ "SignalLongName" SG_ 727 GPSC_PPSLong_Inv "Global Positioning System Coordinates : Precise Positioning System Longitude Invalid";
BA_ "SignalLongName" SG_ 1385 HMIInds1_PCSM "HMI Indications 1 Protected Counter Sync Message";
BA_ "SignalLongName" SG_ 1315 HMII1P_MAC "HMI Indications 1 Protected : MAC";
BA_ "SignalLongName" SG_ 1315 HMII1P_FCnt "HMI Indications 1 Protected : Freshness Counter";
BA_ "SignalType" SG_ 1315 HMII1P_LnFllwgChInterFltDtdAuth "ENM";
BA_ "SignalLongName" SG_ 1315 HMII1P_LnFllwgChInterFltDtdAuth "HMI Indications 1 Protected : Lane Following Chime Interface Fault Detected Authenticated";
BA_ "SignalType" SG_ 1315 HMII1P_IPCDispStsAuth "ENM";
BA_ "SignalLongName" SG_ 1315 HMII1P_IPCDispStsAuth "HMI Indications 1 Protected : IPC Display Status Authenticated";
BA_ "SignalType" SG_ 1315 HMII1P_ChmSysSOHAuth "ENM";
BA_ "SignalLongName" SG_ 1315 HMII1P_ChmSysSOHAuth "HMI Indications 1 Protected : Chime System State of Health Authenticated";
BA_ "SignalType" SG_ 1315 HMII1P_AutoModeSpdLimCnfrmdAuth "ENM";
BA_ "SignalLongName" SG_ 1315 HMII1P_AutoModeSpdLimCnfrmdAuth "HMI Indications 1 Protected : Auto Mode Speed Limit Confirmed Authenticated";
BA_ "SignalType" SG_ 1315 HMII1P_ACCSetTypAuth "ENM";
BA_ "SignalLongName" SG_ 1315 HMII1P_ACCSetTypAuth "HMI Indications 1 Protected : Adaptive Cruise Control Setting Type Authenticated";
BA_ "SignalLongName" SG_ 1315 HMII1P_Filler "HMI Indications 1 Protected : Filler";
BA_ "SignalLongName" SG_ 1315 HMII1P_ARC "HMI Indications 1 Protected : Alive Rolling Count";
BA_ "SignalType" SG_ 2147745832 Sig3538 "ENM";
BA_ "SignalLongName" SG_ 2147745832 Sig3538 "Signal3912";
BA_ "SignalLongName" SG_ 916 Sig3618 "Signal3982";
BA_ "SignalLongName" SG_ 230 Sig3563 "Signal3981";
BA_ "SignalLongName" SG_ 230 Sig3559 "Signal3978";
BA_ "SignalLongName" SG_ 230 Sig3558 "Signal3976";
BA_ "SignalType" SG_ 230 Sig3562 "ENM";
BA_ "SignalLongName" SG_ 230 Sig3562 "Signal3980";
BA_ "SignalType" SG_ 230 Sig3561 "ENM";
BA_ "SignalLongName" SG_ 230 Sig3561 "Signal3979";
BA_ "SignalLongName" SG_ 230 Sig3560 "Signal3977";
BA_ "SignalLongName" SG_ 915 Sig3619 "Signal3989";
BA_ "SignalLongName" SG_ 39 Sig3569 "Signal3988";
BA_ "SignalLongName" SG_ 39 Sig3565 "Signal3984";
BA_ "SignalLongName" SG_ 39 Sig3564 "Signal3983";
BA_ "SignalType" SG_ 39 Sig3568 "ENM";
BA_ "SignalLongName" SG_ 39 Sig3568 "Signal3987";
BA_ "SignalType" SG_ 39 Sig3567 "ENM";
BA_ "SignalLongName" SG_ 39 Sig3567 "Signal3985";
BA_ "SignalType" SG_ 39 Sig3566 "ENM";
BA_ "SignalLongName" SG_ 39 Sig3566 "Signal3986";
BA_ "SignalLongName" SG_ 1384 HptcSt_PCSM "Haptic Seat Protected Counter Sync Message";
BA_ "SignalLongName" SG_ 1314 HSP_MAC "Haptic Seat Protected : MAC";
BA_ "SignalLongName" SG_ 1314 HSP_FCnt "Haptic Seat Protected : Freshness Counter";
BA_ "SignalLongName" SG_ 1314 HSP_ARC "Haptic Seat Protected : Alive Rolling Count";
BA_ "SignalType" SG_ 1314 HSP_HptcStPrsntAuth "ENM";
BA_ "SignalLongName" SG_ 1314 HSP_HptcStPrsntAuth "Haptic Seat Protected : Haptic Seat Present Authenticated";
BA_ "SignalType" SG_ 1314 HSP_HptcStOprtlStsAuth "ENM";
BA_ "SignalLongName" SG_ 1314 HSP_HptcStOprtlStsAuth "Haptic Seat Protected : Haptic Seat Operational Status Authenticated";
BA_ "SignalType" SG_ 1314 HSP_HptcStActvAuth "ENM";
BA_ "SignalLongName" SG_ 1314 HSP_HptcStActvAuth "Haptic Seat Protected : Haptic Seat Active Authenticated";
BA_ "SignalType" SG_ 1314 HSP_DrvAlrtTypCstCurrSetValAuth "ENM";
BA_ "SignalLongName" SG_ 1314 HSP_DrvAlrtTypCstCurrSetValAuth "Haptic Seat Protected : Driver Alert Type Customization Current Setting Value Authenticated";
BA_ "SignalType" SG_ 1314 HptcStLnFllwgUnv "ENM";
BA_ "SignalLongName" SG_ 1314 HptcStLnFllwgUnv "Haptic Seat Protected : Haptic Seat Lane Following Unavailable";
BA_ "SignalLongName" SG_ 914 HstVehPathParms_PCSM "Host Vehicle Path Parameters Protected Counter Sync Message";
BA_ "SignalLongName" SG_ 87 HVPPP_MAC "Host Vehicle Path Parameters Protected : MAC";
BA_ "SignalLongName" SG_ 87 HVPPP_FCnt "Host Vehicle Path Parameters Protected : Freshness Counter";
BA_ "SignalLongName" SG_ 87 HVPPP_HstVehLatVelAuth "Host Vehicle Path Parameters Protected : Host Vehicle Lateral Velocity Authenticated";
BA_ "SignalType" SG_ 87 HVPPP_FrwdVsnModeCmdAuth "ENM";
BA_ "SignalLongName" SG_ 87 HVPPP_FrwdVsnModeCmdAuth "Host Vehicle Path Parameters Protected : Forward Vision Mode Command Authenticated";
BA_ "SignalLongName" SG_ 87 HVPPP_HstVehLngVelAuth "Host Vehicle Path Parameters Protected : Host Vehicle Longitudinal Velocity Authenticated";
BA_ "SignalType" SG_ 87 HVPPP_HstVehLatVelAuth_Inv "ENM";
BA_ "SignalLongName" SG_ 87 HVPPP_HstVehLatVelAuth_Inv "Host Vehicle Path Parameters Protected : Host Vehicle Lateral Velocity Authenticated Invalid";
BA_ "SignalLongName" SG_ 87 HVPPP_HstVehPathCrvAuth "Host Vehicle Path Parameters Protected : Host Vehicle Path Curvature Authenticated";
BA_ "SignalType" SG_ 87 HVPPP_HstVehLngVelAuth_Inv "ENM";
BA_ "SignalLongName" SG_ 87 HVPPP_HstVehLngVelAuth_Inv "Host Vehicle Path Parameters Protected : Host Vehicle Longitudinal Velocity Authenticated Invalid";
BA_ "SignalLongName" SG_ 87 HVPPP_HstVehPathCrvDrvtAuth "Host Vehicle Path Parameters Protected : Host Vehicle Path Curvature Derivative Authenticated";
BA_ "SignalType" SG_ 87 HVPPP_HstVehPathModeAuth "ENM";
BA_ "SignalLongName" SG_ 87 HVPPP_HstVehPathModeAuth "Host Vehicle Path Parameters Protected : Host Vehicle Path Mode Authenticated";
BA_ "SignalLongName" SG_ 87 HVPPP_HstVehSdslAngAuth "Host Vehicle Path Parameters Protected : Host Vehicle Sideslip Angle Authenticated";
BA_ "SignalLongName" SG_ 87 HVPPP_HstVehTrnCntrLatOfstAuth "Host Vehicle Path Parameters Protected : Host Vehicle Turn Center Lateral Offset Authenticated";
BA_ "SignalLongName" SG_ 87 HVPPP_HstVehTrnCntrLngOfstAuth "Host Vehicle Path Parameters Protected : Host Vehicle Turn Center Longitudinal Offset Authenticated";
BA_ "SignalLongName" SG_ 87 HVPPP_HstVehVelAuth "Host Vehicle Path Parameters Protected : Host Vehicle Velocity Authenticated";
BA_ "SignalType" SG_ 87 HVPPP_HstVehTrvlDirAuth "ENM";
BA_ "SignalLongName" SG_ 87 HVPPP_HstVehTrvlDirAuth "Host Vehicle Path Parameters Protected : Host Vehicle Travel Direction Authenticated";
BA_ "SignalLongName" SG_ 87 HVPPP_HstVehYawRateAuth "Host Vehicle Path Parameters Protected : Host Vehicle Yaw Rate Authenticated";
BA_ "SignalType" SG_ 87 HVPPP_HstVehVelAuth_Inv "ENM";
BA_ "SignalLongName" SG_ 87 HVPPP_HstVehVelAuth_Inv "Host Vehicle Path Parameters Protected : Host Vehicle Velocity Authenticated Invalid";
BA_ "SignalType" SG_ 87 HVPPP_LngRngRadarModeCmdAuth "ENM";
BA_ "SignalLongName" SG_ 87 HVPPP_LngRngRadarModeCmdAuth "Host Vehicle Path Parameters Protected : Long Range Radar Mode Command Authenticated";
BA_ "SignalType" SG_ 87 HVPPP_HstVehYawRateAuth_Inv "ENM";
BA_ "SignalLongName" SG_ 87 HVPPP_HstVehYawRateAuth_Inv "Host Vehicle Path Parameters Protected : Host Vehicle Yaw Rate Authenticated Invalid";
BA_ "SignalLongName" SG_ 87 HVPPP_ObjSnsrTmSyncMstrClckAuth "Host Vehicle Path Parameters Protected : Object Sensor Time Sync Master Clock Authenticated";
BA_ "SignalLongName" SG_ 87 HVPPP_ARC "Host Vehicle Path Parameters Protected : Alive Rolling Count";
BA_ "SignalType" SG_ 87 HVPPP_ShrtRngRadarModeCmdAuth "ENM";
BA_ "SignalLongName" SG_ 87 HVPPP_ShrtRngRadarModeCmdAuth "Host Vehicle Path Parameters Protected : Short Range Radar Mode Command Authenticated";
BA_ "SignalType" SG_ 87 HVPPP_ObjsRetndRrwdSnsrsAuth "ENM";
BA_ "SignalLongName" SG_ 87 HVPPP_ObjsRetndRrwdSnsrsAuth "Host Vehicle Path Parameters Protected : Objects Returned from Rearward Sensors Authenticated";
BA_ "SignalType" SG_ 87 HVPPP_ObjsRetndFrwdSnsrsAuth "ENM";
BA_ "SignalLongName" SG_ 87 HVPPP_ObjsRetndFrwdSnsrsAuth "Host Vehicle Path Parameters Protected : Objects Returned from Forward Sensors Authenticated";
BA_ "SignalLongName" SG_ 87 HstVehRideHghtOfst "Host Vehicle Path Parameters Protected : Host Vehicle Ride Height Offset";
BA_ "SignalType" SG_ 87 DrvrMonSysModeCmd "ENM";
BA_ "SignalLongName" SG_ 87 DrvrMonSysModeCmd "Host Vehicle Path Parameters Protected : Driver Monitoring System Mode Command";
BA_ "SignalType" SG_ 87 LnFllwgFtrStatAuth "ENM";
BA_ "SignalLongName" SG_ 87 LnFllwgFtrStatAuth "Host Vehicle Path Parameters Protected : Lane Following Feature State Authenticated";
BA_ "SignalType" SG_ 87 HstVehRideHghtOfst_Inv "ENM";
BA_ "SignalLongName" SG_ 87 HstVehRideHghtOfst_Inv "Host Vehicle Path Parameters Protected : Host Vehicle Ride Height Offset Invalid";
BA_ "SignalLongName" SG_ 87 HVPPP_Filler "Host Vehicle Path Parameters Protected : Filler";
BA_ "SignalType" SG_ 87 HstVehRideHghtOfstSts "ENM";
BA_ "SignalLongName" SG_ 87 HstVehRideHghtOfstSts "Host Vehicle Path Parameters Protected : Host Vehicle Ride Height Offset Status";
BA_ "SignalLongName" SG_ 87 HVPPP_FillerExtnd "Host Vehicle Path Parameters Protected : Filler Extended";
BA_ "SignalLongName" SG_ 687 Sig3623 "Signal4008";
BA_ "SignalLongName" SG_ 109 Sig3576 "Signal3999";
BA_ "SignalLongName" SG_ 109 Sig3573 "Signal3996";
BA_ "SignalLongName" SG_ 109 Sig3574 "Signal3997";
BA_ "SignalLongName" SG_ 109 Sig3572 "Signal3995";
BA_ "SignalLongName" SG_ 109 Sig3575 "Signal3998";
BA_ "SignalLongName" SG_ 109 Sig3571 "Signal3994";
BA_ "SignalLongName" SG_ 38 Sig3584 "Signal4007";
BA_ "SignalType" SG_ 38 Sig3583 "ENM";
BA_ "SignalLongName" SG_ 38 Sig3583 "Signal4006";
BA_ "SignalLongName" SG_ 38 Sig3577 "Signal4000";
BA_ "SignalLongName" SG_ 38 Sig3580 "Signal4003";
BA_ "SignalLongName" SG_ 38 Sig3578 "Signal4001";
BA_ "SignalType" SG_ 38 Sig3581 "ENM";
BA_ "SignalLongName" SG_ 38 Sig3581 "Signal4005";
BA_ "SignalType" SG_ 38 Sig3582 "ENM";
BA_ "SignalLongName" SG_ 38 Sig3582 "Signal4004";
BA_ "SignalLongName" SG_ 38 Sig3579 "Signal4002";
BA_ "SignalLongName" SG_ 956 IBSBatVlt "IBS 12V Battery Voltage Information : IBS 12V Battery Voltage";
BA_ "SignalType" SG_ 956 Bat12VCfg "ENM";
BA_ "SignalLongName" SG_ 956 Bat12VCfg "IBS 12V Battery Voltage Information : Battery 12V Configuration";
BA_ "SignalType" SG_ 956 PTExPrtclFltrMnlRgnModeActvtd "ENM";
BA_ "SignalLongName" SG_ 956 PTExPrtclFltrMnlRgnModeActvtd "IBS 12V Battery Voltage Information : Powertrain Exhaust Particle Filter Manual Regeneration Mode Activated";
BA_ "SignalType" SG_ 956 IBSBatVlt_Inv "ENM";
BA_ "SignalLongName" SG_ 956 IBSBatVlt_Inv "IBS 12V Battery Voltage Information : IBS 12V Battery Voltage Invalid";
BA_ "SignalLongName" SG_ 956 IBSBatVlt_CS "IBS 12V Battery Voltage Information : IBS 12V Battery Voltage Checksum";
BA_ "SignalLongName" SG_ 956 IBSBatVlt_ARC "IBS 12V Battery Voltage Information : IBS 12V Battery Voltage Alive Rolling Count";
BA_ "SignalLongName" SG_ 729 ImoInf "Response to Challenge";
BA_ "SignalType" SG_ 1285 HptcStFldIndOn "ENM";
BA_ "SignalLongName" SG_ 1285 HptcStFldIndOn "Haptic Seat Failed Indication On";
BA_ "SignalLongName" SG_ 704 DrvrAppStrgTrq "Driver Applied Steering Torque";
BA_ "SignalType" SG_ 704 StrgWhlTrqIntegSts "ENM";
BA_ "SignalLongName" SG_ 704 StrgWhlTrqIntegSts "Steering Wheel Torque Integrity Status";
BA_ "SignalType" SG_ 704 StrgWhlHndsOffDtnStat "ENM";
BA_ "SignalLongName" SG_ 704 StrgWhlHndsOffDtnStat "Steering Wheel Hands Off Detection State";
BA_ "SignalType" SG_ 1419 Sig7713 "ENM";
BA_ "SignalLongName" SG_ 1419 Sig7713 "Signal7611";
BA_ "SignalType" SG_ 1419 Sig7709 "ENM";
BA_ "SignalLongName" SG_ 1419 Sig7709 "Signal7607";
BA_ "SignalType" SG_ 1419 Sig3506 "ENM";
BA_ "SignalLongName" SG_ 1419 Sig3506 "Signal3895";
BA_ "SignalType" SG_ 1419 Sig3504 "ENM";
BA_ "SignalLongName" SG_ 1419 Sig3504 "Signal3893";
BA_ "SignalType" SG_ 1419 Sig3503 "ENM";
BA_ "SignalLongName" SG_ 1419 Sig3503 "Signal3892";
BA_ "SignalType" SG_ 1419 Sig3502 "ENM";
BA_ "SignalLongName" SG_ 1419 Sig3502 "Signal3891";
BA_ "SignalType" SG_ 1419 Sig3501 "ENM";
BA_ "SignalLongName" SG_ 1419 Sig3501 "Signal3890";
BA_ "SignalType" SG_ 1419 Sig3500 "ENM";
BA_ "SignalLongName" SG_ 1419 Sig3500 "Signal3889";
BA_ "SignalType" SG_ 1419 Sig3499 "ENM";
BA_ "SignalLongName" SG_ 1419 Sig3499 "Signal3888";
BA_ "SignalType" SG_ 1419 Sig3498 "ENM";
BA_ "SignalLongName" SG_ 1419 Sig3498 "Signal3887";
BA_ "SignalType" SG_ 1419 Sig0451 "ENM";
BA_ "SignalLongName" SG_ 1419 Sig0451 "Signal0310";
BA_ "SignalType" SG_ 1419 Sig7707 "ENM";
BA_ "SignalLongName" SG_ 1419 Sig7707 "Signal7605";
BA_ "SignalType" SG_ 1419 Sig7706 "ENM";
BA_ "SignalLongName" SG_ 1419 Sig7706 "Signal7604";
BA_ "SignalType" SG_ 1419 Sig7705 "ENM";
BA_ "SignalLongName" SG_ 1419 Sig7705 "Signal7603";
BA_ "SignalType" SG_ 1419 Sig7704 "ENM";
BA_ "SignalLongName" SG_ 1419 Sig7704 "Signal7602";
BA_ "SignalType" SG_ 1419 Sig7703 "ENM";
BA_ "SignalLongName" SG_ 1419 Sig7703 "Signal7601";
BA_ "SignalType" SG_ 1419 Sig7702 "ENM";
BA_ "SignalLongName" SG_ 1419 Sig7702 "Signal7600";
BA_ "SignalType" SG_ 1419 Sig7701 "ENM";
BA_ "SignalLongName" SG_ 1419 Sig7701 "Signal7599";
BA_ "SignalType" SG_ 1419 Sig3507 "ENM";
BA_ "SignalLongName" SG_ 1419 Sig3507 "Signal3896";
BA_ "SignalType" SG_ 1419 Sig7710 "ENM";
BA_ "SignalLongName" SG_ 1419 Sig7710 "Signal7608";
BA_ "SignalLongName" SG_ 1501 Sig7554 "Signal7613";
BA_ "SignalType" SG_ 1501 Sig7559 "ENM";
BA_ "SignalLongName" SG_ 1501 Sig7559 "Signal7627";
BA_ "SignalType" SG_ 1501 Sig7557 "ENM";
BA_ "SignalLongName" SG_ 1501 Sig7557 "Signal7629";
BA_ "SignalType" SG_ 1501 Sig7567 "ENM";
BA_ "SignalLongName" SG_ 1501 Sig7567 "Signal7660";
BA_ "SignalType" SG_ 1501 Sig7569 "ENM";
BA_ "SignalLongName" SG_ 1501 Sig7569 "Signal7662";
BA_ "SignalType" SG_ 1501 Sig7558 "ENM";
BA_ "SignalLongName" SG_ 1501 Sig7558 "Signal7626";
BA_ "SignalType" SG_ 1501 Sig7556 "ENM";
BA_ "SignalLongName" SG_ 1501 Sig7556 "Signal7628";
BA_ "SignalType" SG_ 1501 Sig3474 "ENM";
BA_ "SignalLongName" SG_ 1501 Sig3474 "Signal3336";
BA_ "SignalType" SG_ 1501 Sig3473 "ENM";
BA_ "SignalLongName" SG_ 1501 Sig3473 "Signal3335";
BA_ "SignalType" SG_ 1501 Sig7568 "ENM";
BA_ "SignalLongName" SG_ 1501 Sig7568 "Signal7661";
BA_ "SignalType" SG_ 1501 Sig7566 "ENM";
BA_ "SignalLongName" SG_ 1501 Sig7566 "Signal7659";
BA_ "SignalType" SG_ 1501 Sig7711 "ENM";
BA_ "SignalLongName" SG_ 1501 Sig7711 "Signal7609";
BA_ "SignalType" SG_ 1501 Sig7700 "ENM";
BA_ "SignalLongName" SG_ 1501 Sig7700 "Signal7598";
BA_ "SignalType" SG_ 1501 Sig7564 "ENM";
BA_ "SignalLongName" SG_ 1501 Sig7564 "Signal7647";
BA_ "SignalType" SG_ 1501 Sig7562 "ENM";
BA_ "SignalLongName" SG_ 1501 Sig7562 "Signal7644";
BA_ "SignalType" SG_ 1501 Sig7561 "ENM";
BA_ "SignalLongName" SG_ 1501 Sig7561 "Signal7631";
BA_ "SignalType" SG_ 1501 Sig7560 "ENM";
BA_ "SignalLongName" SG_ 1501 Sig7560 "Signal7630";
BA_ "SignalType" SG_ 1501 Sig7553 "ENM";
BA_ "SignalLongName" SG_ 1501 Sig7553 "Signal7612";
BA_ "SignalType" SG_ 1501 Sig3475 "ENM";
BA_ "SignalLongName" SG_ 1501 Sig3475 "Signal3337";
BA_ "SignalType" SG_ 1501 Sig7712 "ENM";
BA_ "SignalLongName" SG_ 1501 Sig7712 "Signal7610";
BA_ "SignalType" SG_ 1427 SBZALCAVisIndStatLt "ENM";
BA_ "SignalLongName" SG_ 1427 SBZALCAVisIndStatLt "SBZA - LCA Visual Indication State Left";
BA_ "SignalType" SG_ 1428 SBZALCAVisIndStatRt "ENM";
BA_ "SignalLongName" SG_ 1428 SBZALCAVisIndStatRt "SBZA - LCA Visual Indication State Right";
BA_ "SignalLongName" SG_ 1420 TLAHSR_HptcStRqstSeqNmb "Traffic Light Assist Haptic Seat Request : Traffic Light Assist Haptic Seat Request Sequence Number";
BA_ "SignalLongName" SG_ 1420 TLAHSR_HptcStRqstPls "Traffic Light Assist Haptic Seat Request : Traffic Light Assist Haptic Seat Request Pulses";
BA_ "SignalType" SG_ 1432 AutoHgBmActReq "ENM";
BA_ "SignalLongName" SG_ 1432 AutoHgBmActReq "Auto High Beam Activation Request";
BA_ "SignalLongName" SG_ 706 Sig4151 "Signal4125";
BA_ "SignalType" SG_ 706 LtFstAprchgVehObjDtd "ENM";
BA_ "SignalLongName" SG_ 706 LtFstAprchgVehObjDtd "Left Fast Approaching Vehicle Object Detected";
BA_ "SignalType" SG_ 1410 RrCrsTrfcAlrtLftIndCtrl "ENM";
BA_ "SignalLongName" SG_ 1410 RrCrsTrfcAlrtLftIndCtrl "Rear Cross Traffic Alert Left Indication Control";
BA_ "SignalType" SG_ 1410 RrCrsTrfcAlrtCstCrStVal "ENM";
BA_ "SignalLongName" SG_ 1410 RrCrsTrfcAlrtCstCrStVal "Rear Cross Traffic Alert Customization Current Setting Value";
BA_ "SignalType" SG_ 1410 LnChgAlrtCstCrStVal "ENM";
BA_ "SignalLongName" SG_ 1410 LnChgAlrtCstCrStVal "Lane Change Alert Customization Current Setting Value";
BA_ "SignalType" SG_ 1444 LtSdVehObjDtd "ENM";
BA_ "SignalLongName" SG_ 1444 LtSdVehObjDtd "Left Side Vehicle Object Detected";
BA_ "SignalType" SG_ 1444 SBZALCAOvrllOplSts "ENM";
BA_ "SignalLongName" SG_ 1444 SBZALCAOvrllOplSts "Side Blind Zone Alert Lane Change Alert Overall Operational Status";
BA_ "SignalLongName" SG_ 182 RCTBAD_BrkgCtlAccel "Rear Cross Traffic Braking Automatic Data : Braking Control Acceleration";
BA_ "SignalType" SG_ 182 RCTBAD_BrkgReqd "ENM";
BA_ "SignalLongName" SG_ 182 RCTBAD_BrkgReqd "Rear Cross Traffic Braking Automatic Data : Braking Requested";
BA_ "SignalType" SG_ 182 RCTBAD_BrkgReqTyp "ENM";
BA_ "SignalLongName" SG_ 182 RCTBAD_BrkgReqTyp "Rear Cross Traffic Braking Automatic Data : Braking Request Type";
BA_ "SignalLongName" SG_ 708 Sig5569 "Signal5352";
BA_ "SignalType" SG_ 708 RtFstAprchgVehObjDtd "ENM";
BA_ "SignalLongName" SG_ 708 RtFstAprchgVehObjDtd "Right Fast Approaching Vehicle Object Detected";
BA_ "SignalType" SG_ 1412 RtSdVehObjDtd "ENM";
BA_ "SignalLongName" SG_ 1412 RtSdVehObjDtd "Right Side Vehicle Object Detected";
BA_ "SignalType" SG_ 1412 RrCrsTrfcAlrtRgIndCtrl "ENM";
BA_ "SignalLongName" SG_ 1412 RrCrsTrfcAlrtRgIndCtrl "Rear Cross Traffic Alert Right Indication Control";
BA_ "SignalLongName" SG_ 162 E44OG1_ObjID1 "Park Assist Objects Group 1 : Object ID 1";
BA_ "SignalLongName" SG_ 162 E44OG1_ID1 "Park Assist Objects Group 1 : ID 1";
BA_ "SignalType" SG_ 162 E44OG1_Hght1 "ENM";
BA_ "SignalLongName" SG_ 162 E44OG1_Hght1 "Park Assist Objects Group 1 : Height 1";
BA_ "SignalType" SG_ 162 E44OG1_Cnfd1 "ENM";
BA_ "SignalLongName" SG_ 162 E44OG1_Cnfd1 "Park Assist Objects Group 1 : Confidence 1";
BA_ "SignalLongName" SG_ 162 E44OG1_PstnP1_X1 "Park Assist Objects Group 1 : Position P1_X 1";
BA_ "SignalLongName" SG_ 162 E44OG1_PstnP1_Y1 "Park Assist Objects Group 1 : Position P1_Y 1";
BA_ "SignalLongName" SG_ 162 E44OG1_PstnP2_X1 "Park Assist Objects Group 1 : Position P2_X 1";
BA_ "SignalLongName" SG_ 162 E44OG1_PstnP2_Y1 "Park Assist Objects Group 1 : Position P2_Y 1";
BA_ "SignalLongName" SG_ 162 E44OG1_Tol1 "Park Assist Objects Group 1 : Tolerance 1";
BA_ "SignalType" SG_ 162 E44OG1_Typ1 "ENM";
BA_ "SignalLongName" SG_ 162 E44OG1_Typ1 "Park Assist Objects Group 1 : Type 1";
BA_ "SignalLongName" SG_ 164 E44OG2_ObjID2 "Park Assist Objects Group 2 : Object ID 2";
BA_ "SignalLongName" SG_ 164 E44OG2_ID2 "Park Assist Objects Group 2 : ID 2";
BA_ "SignalType" SG_ 164 E44OG2_Hght2 "ENM";
BA_ "SignalLongName" SG_ 164 E44OG2_Hght2 "Park Assist Objects Group 2 : Height 2";
BA_ "SignalType" SG_ 164 E44OG2_Cnfd2 "ENM";
BA_ "SignalLongName" SG_ 164 E44OG2_Cnfd2 "Park Assist Objects Group 2 : Confidence 2";
BA_ "SignalLongName" SG_ 164 E44OG2_PstnP1_X2 "Park Assist Objects Group 2 : Position P1_X 2";
BA_ "SignalLongName" SG_ 164 E44OG2_PstnP1_Y2 "Park Assist Objects Group 2 : Position P1_Y 2";
BA_ "SignalLongName" SG_ 164 E44OG2_PstnP2_X2 "Park Assist Objects Group 2 : Position P2_X 2";
BA_ "SignalLongName" SG_ 164 E44OG2_PstnP2_Y2 "Park Assist Objects Group 2 : Position P2_Y 2";
BA_ "SignalLongName" SG_ 164 E44OG2_Tol2 "Park Assist Objects Group 2 : Tolerance 2";
BA_ "SignalType" SG_ 164 E44OG2_Typ2 "ENM";
BA_ "SignalLongName" SG_ 164 E44OG2_Typ2 "Park Assist Objects Group 2 : Type 2";
BA_ "SignalLongName" SG_ 168 E44OG3_ObjID3 "Park Assist Objects Group 3 : Object ID 3";
BA_ "SignalLongName" SG_ 168 E44OG3_ID3 "Park Assist Objects Group 3 : ID 3";
BA_ "SignalType" SG_ 168 E44OG3_Hght3 "ENM";
BA_ "SignalLongName" SG_ 168 E44OG3_Hght3 "Park Assist Objects Group 3 : Height 3";
BA_ "SignalType" SG_ 168 E44OG3_Cnfd3 "ENM";
BA_ "SignalLongName" SG_ 168 E44OG3_Cnfd3 "Park Assist Objects Group 3 : Confidence 3";
BA_ "SignalLongName" SG_ 168 E44OG3_PstnP1_X3 "Park Assist Objects Group 3 : Position P1_X 3";
BA_ "SignalLongName" SG_ 168 E44OG3_PstnP1_Y3 "Park Assist Objects Group 3 : Position P1_Y 3";
BA_ "SignalLongName" SG_ 168 E44OG3_PstnP2_X3 "Park Assist Objects Group 3 : Position P2_X 3";
BA_ "SignalLongName" SG_ 168 E44OG3_PstnP2_Y3 "Park Assist Objects Group 3 : Position P2_Y 3";
BA_ "SignalLongName" SG_ 168 E44OG3_Tol3 "Park Assist Objects Group 3 : Tolerance 3";
BA_ "SignalType" SG_ 168 E44OG3_Typ3 "ENM";
BA_ "SignalLongName" SG_ 168 E44OG3_Typ3 "Park Assist Objects Group 3 : Type 3";
BA_ "SignalType" SG_ 2147745821 Sig4007 "ENM";
BA_ "SignalLongName" SG_ 2147745821 Sig4007 "Signal4053";
BA_ "SignalType" SG_ 1421 LnFllwgFtrStat "ENM";
BA_ "SignalLongName" SG_ 1421 LnFllwgFtrStat "Lane Following Feature State";
BA_ "SignalLongName" SG_ 1383 LnFllwgHptcStReqs_PCSM "Lane Following Haptic Seat Requests Protected Counter Sync Message";
BA_ "SignalLongName" SG_ 1323 LFHSRP_MAC "Lane Following Haptic Seat Requests Protected : MAC";
BA_ "SignalLongName" SG_ 1323 LFHSRP_FCnt "Lane Following Haptic Seat Requests Protected : Freshness Counter";
BA_ "SignalLongName" SG_ 1323 LFHSRP_GnrcHptcStReqSeqNum "Lane Following Haptic Seat Requests Protected : Generic Haptic Seat Request Sequence Number Authenticated";
BA_ "SignalLongName" SG_ 1323 LFHSRP_GnrcHptcStReqPuls "Lane Following Haptic Seat Requests Protected : Generic Haptic Seat Request Pulses Authenticated";
BA_ "SignalLongName" SG_ 1323 LFHSRP_LtHndSdHptcStReqSeqNum "Lane Following Haptic Seat Requests Protected : Left Hand Side Haptic Seat Request Sequence Number Authenticated";
BA_ "SignalLongName" SG_ 1323 LFHSRP_LtHndSdHptcStReqPuls "Lane Following Haptic Seat Requests Protected : Left Hand Side Haptic Seat Request Pulses Authenticated";
BA_ "SignalLongName" SG_ 1323 LFHSRP_RtHndSdHptcStReqSeqNum "Lane Following Haptic Seat Requests Protected : Right Hand Side Haptic Seat Request Sequence Number Authenticated";
BA_ "SignalLongName" SG_ 1323 LFHSRP_RtHndSdHptcStReqPuls "Lane Following Haptic Seat Requests Protected : Right Hand Side Haptic Seat Request Pulses Authenticated";
BA_ "SignalLongName" SG_ 1323 LFHSRP_Filler "Lane Following Haptic Seat Requests Protected : Filler";
BA_ "SignalLongName" SG_ 1323 LFHSRP_ARC "Lane Following Haptic Seat Requests Protected : Alive Rolling Count";
BA_ "SignalType" SG_ 1027 PrkAsstCustSeltn "ENM";
BA_ "SignalLongName" SG_ 1027 PrkAsstCustSeltn "Park Assist Customer Selection";
BA_ "SignalType" SG_ 1027 E44OprtlSts "ENM";
BA_ "SignalLongName" SG_ 1027 E44OprtlSts "Park Assist Operational Status";
BA_ "SignalType" SG_ 1027 PrkAsstONOFFCstCrStVal "ENM";
BA_ "SignalLongName" SG_ 1027 PrkAsstONOFFCstCrStVal "Park Assist On Off Customization Current Setting Value";
BA_ "SignalLongName" SG_ 75 ElecPSOvrlyTrqDlvd "Electronic Power Steering OverlayTorque Delivered";
BA_ "SignalType" SG_ 75 ElecPSOvrlyTrqDlvd_Inv "ENM";
BA_ "SignalLongName" SG_ 75 ElecPSOvrlyTrqDlvd_Inv "Electronic Power Steering Overlay Torque Delivered Invalid";
BA_ "SignalType" SG_ 75 ElecPSTrqOvrlySts "ENM";
BA_ "SignalLongName" SG_ 75 ElecPSTrqOvrlySts "Electronic Power Steering Torque Overlay Status";
BA_ "SignalLongName" SG_ 32 StrgEstdRckF "Steering Estimated Rack Force";
BA_ "SignalType" SG_ 32 StrgEstdRckF_Inv "ENM";
BA_ "SignalLongName" SG_ 32 StrgEstdRckF_Inv "Steering Estimated Rack Force Invalid";
BA_ "SignalLongName" SG_ 739 Sig7812 "Signal7831";
BA_ "SignalType" SG_ 739 Sig7811 "ENM";
BA_ "SignalLongName" SG_ 739 Sig7811 "Signal7830";
BA_ "SignalType" SG_ 739 Sig7810 "ENM";
BA_ "SignalLongName" SG_ 739 Sig7810 "Signal7829";
BA_ "SignalType" SG_ 739 Sig7813 "ENM";
BA_ "SignalLongName" SG_ 739 Sig7813 "Signal7832";
BA_ "SignalType" SG_ 946 Sig0417 "ENM";
BA_ "SignalLongName" SG_ 946 Sig0417 "Signal0173";
BA_ "SignalType" SG_ 946 Sig4160 "ENM";
BA_ "SignalLongName" SG_ 946 Sig4160 "Signal4185";
BA_ "SignalType" SG_ 946 Sig0415 "ENM";
BA_ "SignalLongName" SG_ 946 Sig0415 "Signal0171";
BA_ "SignalType" SG_ 946 Sig0109 "ENM";
BA_ "SignalLongName" SG_ 946 Sig0109 "Signal0051";
BA_ "SignalType" SG_ 946 AFLServHdlmpsIndOn "ENM";
BA_ "SignalLongName" SG_ 946 AFLServHdlmpsIndOn "Adaptive Forward Lighting Service Headlamps Indication On";
BA_ "SignalType" SG_ 946 Sig0108 "ENM";
BA_ "SignalLongName" SG_ 946 Sig0108 "Signal0050";
BA_ "SignalType" SG_ 946 Sig0107 "ENM";
BA_ "SignalLongName" SG_ 946 Sig0107 "Signal0049";
BA_ "SignalType" SG_ 946 Sig0106 "ENM";
BA_ "SignalLongName" SG_ 946 Sig0106 "Signal0048";
BA_ "SignalType" SG_ 946 Sig0105 "ENM";
BA_ "SignalLongName" SG_ 946 Sig0105 "Signal0047";
BA_ "SignalType" SG_ 946 Sig0104 "ENM";
BA_ "SignalLongName" SG_ 946 Sig0104 "Signal0046";
BA_ "SignalType" SG_ 946 Sig0103 "ENM";
BA_ "SignalLongName" SG_ 946 Sig0103 "Signal0045";
BA_ "SignalType" SG_ 946 Sig0413 "ENM";
BA_ "SignalLongName" SG_ 946 Sig0413 "Signal0169";
BA_ "SignalType" SG_ 946 Sig0412 "ENM";
BA_ "SignalLongName" SG_ 946 Sig0412 "Signal0168";
BA_ "SignalType" SG_ 946 Sig0411 "ENM";
BA_ "SignalLongName" SG_ 946 Sig0411 "Signal0167";
BA_ "SignalType" SG_ 946 Sig0410 "ENM";
BA_ "SignalLongName" SG_ 946 Sig0410 "Signal0166";
BA_ "SignalType" SG_ 946 Sig0409 "ENM";
BA_ "SignalLongName" SG_ 946 Sig0409 "Signal0165";
BA_ "SignalType" SG_ 946 Sig0408 "ENM";
BA_ "SignalLongName" SG_ 946 Sig0408 "Signal0164";
BA_ "SignalType" SG_ 946 Sig0407 "ENM";
BA_ "SignalLongName" SG_ 946 Sig0407 "Signal0163";
BA_ "SignalType" SG_ 946 Sig0110 "ENM";
BA_ "SignalLongName" SG_ 946 Sig0110 "Signal0052";
BA_ "SignalType" SG_ 946 Sig4157 "ENM";
BA_ "SignalLongName" SG_ 946 Sig4157 "Signal4182";
BA_ "SignalType" SG_ 946 Sig4156 "ENM";
BA_ "SignalLongName" SG_ 946 Sig4156 "Signal4181";
BA_ "SignalType" SG_ 946 Sig4155 "ENM";
BA_ "SignalLongName" SG_ 946 Sig4155 "Signal4180";
BA_ "SignalType" SG_ 946 Sig4154 "ENM";
BA_ "SignalLongName" SG_ 946 Sig4154 "Signal4179";
BA_ "SignalType" SG_ 946 Sig4153 "ENM";
BA_ "SignalLongName" SG_ 946 Sig4153 "Signal4178";
BA_ "SignalType" SG_ 946 Sig4152 "ENM";
BA_ "SignalLongName" SG_ 946 Sig4152 "Signal4177";
BA_ "SignalType" SG_ 946 AdvdFrtLgtSysHiBmIndOnReqd "ENM";
BA_ "SignalLongName" SG_ 946 AdvdFrtLgtSysHiBmIndOnReqd "Advanced Front Lighting System High Beam Indication On Requested";
BA_ "SignalType" SG_ 946 Sig0416 "ENM";
BA_ "SignalLongName" SG_ 946 Sig0416 "Signal0172";
BA_ "SignalType" SG_ 946 Sig4161 "ENM";
BA_ "SignalLongName" SG_ 946 Sig4161 "Signal4186";
BA_ "SignalType" SG_ 946 Sig4158 "ENM";
BA_ "SignalLongName" SG_ 946 Sig4158 "Signal4183";
BA_ "SignalType" SG_ 701 AE44CtrlTctlFdbk "ENM";
BA_ "SignalLongName" SG_ 701 AE44CtrlTctlFdbk "Advanced Park Assist Advanced Park Assist Control Tactile Feedback";
BA_ "SignalType" SG_ 1406 AE44CR_SptFndChmEvntStat "ENM";
BA_ "SignalLongName" SG_ 1406 AE44CR_SptFndChmEvntStat "Advanced Park Assist Chime Requests : Advanced Park Assist Spot Found Chime Event State";
BA_ "SignalType" SG_ 1406 AE44CR_FaildChmEvntStat "ENM";
BA_ "SignalLongName" SG_ 1406 AE44CR_FaildChmEvntStat "Advanced Park Assist Chime Requests : Advanced Park Assist Failed Chime Event State";
BA_ "SignalType" SG_ 1406 AE44CR_CncldChmEvntStat "ENM";
BA_ "SignalLongName" SG_ 1406 AE44CR_CncldChmEvntStat "Advanced Park Assist Chime Requests : Advanced Park Assist Canceled Chime Event State";
BA_ "SignalType" SG_ 1406 AE44CR_CmpltChmEvntStat "ENM";
BA_ "SignalLongName" SG_ 1406 AE44CR_CmpltChmEvntStat "Advanced Park Assist Chime Requests : Advanced Park Assist Complete Chime Event State";
BA_ "SignalType" SG_ 1406 AE44CR_StopChmEvntStat "ENM";
BA_ "SignalLongName" SG_ 1406 AE44CR_StopChmEvntStat "Advanced Park Assist Chime Requests : Advanced Park Assist Stop Chime Event State";
BA_ "SignalLongName" SG_ 1422 AE44WI_MnvrPrgs "Advanced Park Assist Warning Indications : Advanced Park Assist Maneuver Progress";
BA_ "SignalType" SG_ 1422 AE44WI_FcsReq "ENM";
BA_ "SignalLongName" SG_ 1422 AE44WI_FcsReq "Advanced Park Assist Warning Indications : Advanced Park Assist Focus Request";
BA_ "SignalType" SG_ 1422 AE44WI_AutoStrgIconReq "ENM";
BA_ "SignalLongName" SG_ 1422 AE44WI_AutoStrgIconReq "Advanced Park Assist Warning Indications : Advanced Park Assist Auto Steering Icon Request";
BA_ "SignalType" SG_ 1422 AE44WI_WrnIndReq "ENM";
BA_ "SignalLongName" SG_ 1422 AE44WI_WrnIndReq "Advanced Park Assist Warning Indications : Advanced Park Assist Warning Indication Request";
BA_ "SignalType" SG_ 1422 AE44LftSftBtnRqst "ENM";
BA_ "SignalLongName" SG_ 1422 AE44LftSftBtnRqst "Advanced Park Assist Left Soft Button Request";
BA_ "SignalType" SG_ 1422 AE44ExtPrkSftBtnRqst "ENM";
BA_ "SignalLongName" SG_ 1422 AE44ExtPrkSftBtnRqst "Advanced Park Assist Exit Park Soft Button Request";
BA_ "SignalType" SG_ 1422 AE44CrssFrntInSftBtnRqst "ENM";
BA_ "SignalLongName" SG_ 1422 AE44CrssFrntInSftBtnRqst "Advanced Park Assist Cross Front-In Soft Button Reques";
BA_ "SignalType" SG_ 1422 AE44CrssBckInSftBtnRqst "ENM";
BA_ "SignalLongName" SG_ 1422 AE44CrssBckInSftBtnRqst "Advanced Park Assist Cross Back-In Soft Button Request";
BA_ "SignalType" SG_ 1422 AE44VMR_SloDnIndOn "ENM";
BA_ "SignalLongName" SG_ 1422 AE44VMR_SloDnIndOn "Advanced Park Assist Visual Message Requests : Advanced Park Assist Slow Down Indication On";
BA_ "SignalType" SG_ 1422 AE44VMR_NAvalIndOn "ENM";
BA_ "SignalLongName" SG_ 1422 AE44VMR_NAvalIndOn "Advanced Park Assist Visual Message Requests : Advanced Park Assist Not Available Indication On";
BA_ "SignalType" SG_ 1422 AE44SrchSftBtnRqst "ENM";
BA_ "SignalLongName" SG_ 1422 AE44SrchSftBtnRqst "Advanced Park Assist Searching Soft Button Request";
BA_ "SignalType" SG_ 1422 AE44RghtSftBtnRqst "ENM";
BA_ "SignalLongName" SG_ 1422 AE44RghtSftBtnRqst "Advanced Park Assist Right Soft Button Request";
BA_ "SignalType" SG_ 1422 AE44PrllPrkSftBtnRqst "ENM";
BA_ "SignalLongName" SG_ 1422 AE44PrllPrkSftBtnRqst "Advanced Park Assist Parallel Parking Soft Button Request";
BA_ "SignalLongName" SG_ 206 HVBI_BatPackPrcdVltg "High Voltage Battery Information : Battery Pack Processed Voltage";
BA_ "SignalType" SG_ 206 HVBI_BatPackPrcdVltg_Inv "ENM";
BA_ "SignalLongName" SG_ 206 HVBI_BatPackPrcdVltg_Inv "High Voltage Battery Information : Battery Pack Processed Voltage Invalid";
BA_ "SignalType" SG_ 206 HVBI_BatPackPrcdVltg_DuD "ENM";
BA_ "SignalLongName" SG_ 206 HVBI_BatPackPrcdVltg_DuD "High Voltage Battery Information : Battery Pack Processed Voltage Don't Use Data";
BA_ "SignalLongName" SG_ 206 HiVltgBatPrcdCurr "High Voltage Battery Processed Current";
BA_ "SignalType" SG_ 206 HiVltgBatPrcdCurr_DuD "ENM";
BA_ "SignalLongName" SG_ 206 HiVltgBatPrcdCurr_DuD "High Voltage Battery Processed Current Don't Use Data";
BA_ "SignalType" SG_ 206 HiVltgBatPrcdCurr_Inv "ENM";
BA_ "SignalLongName" SG_ 206 HiVltgBatPrcdCurr_Inv "High Voltage Battery Processed Current Invalid";
BA_ "SignalLongName" SG_ 722 HVBSOC_BatSOC "High Voltage Battery State of Charge : Battery State of Charge";
BA_ "SignalLongName" SG_ 722 HVBSOC_BatSOCMin "High Voltage Battery State of Charge : Battery State of Charge Minimum";
BA_ "SignalLongName" SG_ 722 HVBSOC_BatSOCTgt "High Voltage Battery State of Charge : Battery State of Charge Target";
BA_ "SignalLongName" SG_ 722 HVBVL_VltgLwrLim "High Voltage Battery Voltage Limit : Voltage Lower Limit";
BA_ "SignalType" SG_ 722 HVBSOC_BatSOC_Inv "ENM";
BA_ "SignalLongName" SG_ 722 HVBSOC_BatSOC_Inv "High Voltage Battery State of Charge : Battery State of Charge Invalid";
BA_ "SignalLongName" SG_ 722 HVBVL_VltgLwrLimCrnk "High Voltage Battery Voltage Limit : Voltage Lower Limit Crank";
BA_ "SignalLongName" SG_ 722 HVBVL_VltgUpprLim "High Voltage Battery Voltage Limit : Voltage Upper Limit";
BA_ "SignalLongName" SG_ 722 HVBCL_CurrLwrLim "High Voltage Battery Current Limit : Current Lower Limit";
BA_ "SignalLongName" SG_ 722 HVBCL_CurrUpprLim "High Voltage Battery Current Limit : Current Upper Limit";
BA_ "SignalLongName" SG_ 1526 HiVltgBatMaxTemp "High Voltage Battery Maximum Temperature";
BA_ "SignalLongName" SG_ 1526 HiVltgBatMinTemp "High Voltage Battery Minimum Temperature";
BA_ "SignalType" SG_ 1526 HiVltgBatMaxTemp_Inv "ENM";
BA_ "SignalLongName" SG_ 1526 HiVltgBatMaxTemp_Inv "High Voltage Battery Maximum Temperature Invalid";
BA_ "SignalType" SG_ 1526 HiVltgBatMaxTemp_DuD "ENM";
BA_ "SignalLongName" SG_ 1526 HiVltgBatMaxTemp_DuD "High Voltage Battery Maximum Temperature Don't Use Data";
BA_ "SignalType" SG_ 1526 HiVltgBatMinTemp_Inv "ENM";
BA_ "SignalLongName" SG_ 1526 HiVltgBatMinTemp_Inv "High Voltage Battery Minimum Temperature Invalid";
BA_ "SignalType" SG_ 1526 HiVltgBatMinTemp_DuD "ENM";
BA_ "SignalLongName" SG_ 1526 HiVltgBatMinTemp_DuD "High Voltage Battery Minimum Temperature Don't Use Data";
BA_ "SignalLongName" SG_ 721 Sig2660 "Signal2667";
BA_ "SignalType" SG_ 721 Sig2661 "ENM";
BA_ "SignalLongName" SG_ 721 Sig2661 "Signal2668";
BA_ "SignalLongName" SG_ 1527 Sig4454 "Signal5075";
BA_ "SignalType" SG_ 1527 Sig4453 "ENM";
BA_ "SignalLongName" SG_ 1527 Sig4453 "Signal5074";
BA_ "SignalType" SG_ 1527 Sig4449 "ENM";
BA_ "SignalLongName" SG_ 1527 Sig4449 "Signal5073";
BA_ "SignalLongName" SG_ 112 Sig3543 "Signal3962";
BA_ "SignalLongName" SG_ 112 Sig3544 "Signal3963";
BA_ "SignalLongName" SG_ 112 Sig3547 "Signal3951";
BA_ "SignalType" SG_ 112 Sig3606 "ENM";
BA_ "SignalLongName" SG_ 112 Sig3606 "Signal3950";
BA_ "SignalType" SG_ 112 Sig3546 "ENM";
BA_ "SignalLongName" SG_ 112 Sig3546 "Signal3949";
BA_ "SignalType" SG_ 112 Sig3545 "ENM";
BA_ "SignalLongName" SG_ 112 Sig3545 "Signal3948";
BA_ "SignalLongName" SG_ 1436 Sig0520 "Signal0421";
BA_ "SignalType" SG_ 1436 Sig0521 "ENM";
BA_ "SignalLongName" SG_ 1436 Sig0521 "Signal0422";
BA_ "SignalType" SG_ 1436 Sig0526 "ENM";
BA_ "SignalLongName" SG_ 1436 Sig0526 "Signal0423";
BA_ "SignalLongName" SG_ 1528 Sig4452 "Signal5078";
BA_ "SignalType" SG_ 1528 Sig4451 "ENM";
BA_ "SignalLongName" SG_ 1528 Sig4451 "Signal5077";
BA_ "SignalType" SG_ 1528 Sig4450 "ENM";
BA_ "SignalLongName" SG_ 1528 Sig4450 "Signal5076";
BA_ "SignalType" SG_ 928 Sig4919 "ENM";
BA_ "SignalLongName" SG_ 928 Sig4919 "Signal4649";
BA_ "SignalType" SG_ 928 HiVltgBatOutOfEngyIndReq "ENM";
BA_ "SignalLongName" SG_ 928 HiVltgBatOutOfEngyIndReq "High Voltage Battery Out Of Energy Indication Request";
BA_ "SignalLongName" SG_ 723 HVBPL_InstnsChrgPwrLim "High Voltage Battery Power Limit : Crank Charge Power Limit";
BA_ "SignalLongName" SG_ 723 HVBPL_InstnsDischrgPwrLim "High Voltage Battery Power Limit : Crank Discharge Power Limit";
BA_ "SignalLongName" SG_ 723 HVBPL_LngTrmChrgPwrLim "High Voltage Battery Power Limit : Long Term Charge Power Limit";
BA_ "SignalLongName" SG_ 723 HVBPL_LngTrmDischrgPwrLim "High Voltage Battery Power Limit : Long Term Discharge Power Limit";
BA_ "SignalLongName" SG_ 723 HVBPL_ShrtTrmChrgPwrLim "High Voltage Battery Power Limit : Short Term Charge Power Limit";
BA_ "SignalLongName" SG_ 723 PrplDispEngTrq "Propulsion Display Engine Torque";
BA_ "SignalLongName" SG_ 723 PrplDispTotTrq "Propulsion Display Total Torque";
BA_ "SignalType" SG_ 723 PrplDispEngTrq_Inv "ENM";
BA_ "SignalLongName" SG_ 723 PrplDispEngTrq_Inv "Propulsion Display Engine Torque Invalid";
BA_ "SignalType" SG_ 723 PrplDispEngTrq_DuD "ENM";
BA_ "SignalLongName" SG_ 723 PrplDispEngTrq_DuD "Propulsion Display Engine Torque Don't Use Data";
BA_ "SignalLongName" SG_ 723 PwrElecHybAftRunReqTm "Power Electronics Hybrid After Run Request Time";
BA_ "SignalLongName" SG_ 723 GrossGridEngyIntoBatSnLstUpdt "Gross Grid Energy Into Battery Since Last Update";
BA_ "SignalLongName" SG_ 723 HiVltgThrmlTotPwrUsd "High Voltage Thermal Total Power Used";
BA_ "SignalType" SG_ 723 HiVltgThrmlTotPwrUsd_Inv "ENM";
BA_ "SignalLongName" SG_ 723 HiVltgThrmlTotPwrUsd_Inv "High Voltage Thermal Total Power Used Invalid";
BA_ "SignalLongName" SG_ 723 NetGridEngyIntoBatSnLstUpdt "Net Grid Energy Into Battery Since Last Update";
BA_ "SignalLongName" SG_ 723 HiVltgThrmlPwrReq "High Voltage Thermal Power Request";
BA_ "SignalLongName" SG_ 723 HiVltgThrmlPwrRqrd "High Voltage Thermal Power Required";
BA_ "SignalType" SG_ 723 ChrgSysShfToPrkReqd "ENM";
BA_ "SignalLongName" SG_ 723 ChrgSysShfToPrkReqd "Charging System Shift To Park Requested";
BA_ "SignalLongName" SG_ 723 HVBPL_ShrtTrmDischrgPwrLim "High Voltage Battery Power Limit : Short Term Discharge Power Limit";
BA_ "SignalType" SG_ 723 JmpStrtEnbld "ENM";
BA_ "SignalLongName" SG_ 723 JmpStrtEnbld "Jump Start Enabled";
BA_ "SignalType" SG_ 723 HiVltgBatGridCnctd "ENM";
BA_ "SignalLongName" SG_ 723 HiVltgBatGridCnctd "High Voltage Battery Grid Connected";
BA_ "SignalType" SG_ 723 CoolFanFrtEndOutEnbl "ENM";
BA_ "SignalLongName" SG_ 723 CoolFanFrtEndOutEnbl "Cooling Fan Front End Output Enable";
BA_ "SignalLongName" SG_ 1437 HiVltgBatCoolTgtTemp "High Voltage Battery Coolant Target Temperature";
BA_ "SignalLongName" SG_ 1437 HiVltgBatCoolTempSnsrVal "High Voltage Battery Coolant Temperature Sensor Value";
BA_ "SignalType" SG_ 1437 HiVltgBatCoolTempSnsrVal_Inv "ENM";
BA_ "SignalLongName" SG_ 1437 HiVltgBatCoolTempSnsrVal_Inv "High Voltage Battery Coolant Temperature Sensor Value Invalid";
BA_ "SignalLongName" SG_ 1437 PrplDispTotPwrLvlPct "Propulsion Display Total Power Level Percent";
BA_ "SignalLongName" SG_ 1437 RegenPwrLimdDispPct "Regenerative Power Limited Display Percent";
BA_ "SignalType" SG_ 1437 ChrgSysAudblIndReq "ENM";
BA_ "SignalLongName" SG_ 1437 ChrgSysAudblIndReq "Charging System Audible Indication Request";
BA_ "SignalType" SG_ 1437 PwrElecCoolPmpSpdActlDgFltActv "ENM";
BA_ "SignalLongName" SG_ 1437 PwrElecCoolPmpSpdActlDgFltActv "Power Electronics Coolant Pump Speed Actual Diagnostic Fault Active";
BA_ "SignalType" SG_ 1437 HiVltgBatThrmlMode "ENM";
BA_ "SignalLongName" SG_ 1437 HiVltgBatThrmlMode "High Voltage Battery Thermal Mode";
BA_ "SignalLongName" SG_ 725 GPSV_PPSCalcdSpd "Global Positioning System Velocity : Precise Positioning System Calculated Speed";
BA_ "SignalLongName" SG_ 725 GPSV_PPSElvtn "Global Positioning System Velocity : Precise Positioning System Elevation";
BA_ "SignalType" SG_ 725 GPSV_PPSCalcdSpd_Inv "ENM";
BA_ "SignalLongName" SG_ 725 GPSV_PPSCalcdSpd_Inv "Global Positioning System Velocity : Precise Positioning System Calculated Speed Invalid";
BA_ "SignalLongName" SG_ 725 GPSV_PPSHdg "Global Positioning System Velocity : Precise Positioning System Heading";
BA_ "SignalType" SG_ 725 GPSV_PPSElvtn_Inv "ENM";
BA_ "SignalLongName" SG_ 725 GPSV_PPSElvtn_Inv "Global Positioning System Velocity : Precise Positioning System Elevation Invalid";
BA_ "SignalLongName" SG_ 725 GPSQM_PPSPstnDilutnPrcsn "Global Positioning System Quality Metrics : Precise Positioning System Position Dilution of Precision";
BA_ "SignalType" SG_ 725 GPSQM_PPSPstnDilutnPrcsn_Inv "ENM";
BA_ "SignalLongName" SG_ 725 GPSQM_PPSPstnDilutnPrcsn_Inv "Global Positioning System Quality Metrics : Precise Positioning System Position Dilution of Precision Invalid";
BA_ "SignalType" SG_ 725 GPSV_PPSHdg_Inv "ENM";
BA_ "SignalLongName" SG_ 725 GPSV_PPSHdg_Inv "Global Positioning System Velocity : Precise Positioning System Heading Invalid";
BA_ "SignalLongName" SG_ 725 GPSQM_PPSAbsVelErrEst "Global Positioning System Quality Metrics : Precise Positioning System Absolute Velocity Error Estimate";
BA_ "SignalType" SG_ 725 GPSQM_PPSAbsVelErrEst_Inv "ENM";
BA_ "SignalLongName" SG_ 725 GPSQM_PPSAbsVelErrEst_Inv "Global Positioning System Quality Metrics : Precise Positioning System Absolute Velocity Error Estimate Invalid";
BA_ "SignalLongName" SG_ 725 GPST_PPSTmOfDy "Global Positioning System Time : Precise Positioning System Time of Day";
BA_ "SignalType" SG_ 725 GPST_PPSTmOfDy_Inv "ENM";
BA_ "SignalLongName" SG_ 725 GPST_PPSTmOfDy_Inv "Global Positioning System Time : Precise Positioning System Time of Day Invalid";
BA_ "SignalType" SG_ 720 JmpStrtReqd "ENM";
BA_ "SignalLongName" SG_ 720 JmpStrtReqd "Jump Start Requested";
BA_ "SignalLongName" SG_ 930 PlatGenrDtCycSetptReq "Platform Generator Duty Cycle Setpoint Request";
BA_ "SignalLongName" SG_ 930 IntDimDspLvl "Interior Dimming Display Level";
BA_ "SignalLongName" SG_ 930 IntDimLvl "Interior Dimming Backlighting Level";
BA_ "SignalType" SG_ 930 HillDscntCtlModeSwActv "ENM";
BA_ "SignalLongName" SG_ 930 HillDscntCtlModeSwActv "Hill Descent Control Mode Switch Active";
BA_ "SignalType" SG_ 930 HillDscntCtlModeSwActv_Inv "ENM";
BA_ "SignalLongName" SG_ 930 HillDscntCtlModeSwActv_Inv "Hill Descent Control Mode Switch Active Invalid";
BA_ "SignalType" SG_ 726 WndPstnStsRF "ENM";
BA_ "SignalLongName" SG_ 726 WndPstnStsRF "Window Position Status Right Front";
BA_ "SignalType" SG_ 726 WndPstnStsLF "ENM";
BA_ "SignalLongName" SG_ 726 WndPstnStsLF "Window Position Status Left Front";
BA_ "SignalType" SG_ 726 PrkLmpsAct "ENM";
BA_ "SignalLongName" SG_ 726 PrkLmpsAct "Park Lamps Active";
BA_ "SignalType" SG_ 726 FgLmpFrtRtCmd "ENM";
BA_ "SignalLongName" SG_ 726 FgLmpFrtRtCmd "Fog Lamp Front Right Command";
BA_ "SignalType" SG_ 726 FgLmpFrtLftCmd "ENM";
BA_ "SignalLongName" SG_ 726 FgLmpFrtLftCmd "Fog Lamp Front Left Command";
BA_ "SignalType" SG_ 726 LogisticModeStatus "ENM";
BA_ "SignalLongName" SG_ 726 LogisticModeStatus "Logistic Mode Status";
BA_ "SignalType" SG_ 726 AutoBmSlctAllwd "ENM";
BA_ "SignalLongName" SG_ 726 AutoBmSlctAllwd "Automatic Beam Select Allowed";
BA_ "SignalType" SG_ 726 AutoBmSlctAllwd_Inv "ENM";
BA_ "SignalLongName" SG_ 726 AutoBmSlctAllwd_Inv "Automatic Beam Select Allowed Invalid";
BA_ "SignalLongName" SG_ 726 GPSQM_PPS2DAbsPstnErrEst "Global Positioning System Quality Metrics : Precise Positioning System 2D Absolute Position Error Estimate";
BA_ "SignalType" SG_ 726 GPSQM_PPS2DAbsPstnErrEst_Inv "ENM";
BA_ "SignalLongName" SG_ 726 GPSQM_PPS2DAbsPstnErrEst_Inv "Global Positioning System Quality Metrics : Precise Positioning System 2D Absolute Position Error Estimate Invalid";
BA_ "SignalType" SG_ 726 ValetModeActive "ENM";
BA_ "SignalLongName" SG_ 726 ValetModeActive "Valet Mode Lock Information : Valet Mode Active";
BA_ "SignalLongName" SG_ 726 GPSQM_PPS3DAbsPstnErrEst "Global Positioning System Quality Metrics : Precise Positioning System 3D Absolute Position Error Estimate";
BA_ "SignalType" SG_ 726 GPSQM_PPS3DAbsPstnErrEst_Inv "ENM";
BA_ "SignalLongName" SG_ 726 GPSQM_PPS3DAbsPstnErrEst_Inv "Global Positioning System Quality Metrics : Precise Positioning System 3D Absolute Position Error Estimate Invalid";
BA_ "SignalType" SG_ 944 EE46etptPrty "ENM";
BA_ "SignalLongName" SG_ 944 EE46etptPrty "Electric Power Management Setpoint Priority";
BA_ "SignalLongName" SG_ 1407 ChmMngrStat "Chime Manager Status";
BA_ "SignalLongName" SG_ 1407 HtdWhlTempAmbtAirEstd "Heated Wheel Temperature Ambient Air Estimated";
BA_ "SignalType" SG_ 1407 FrntPCMRspTypCstChgSetReq "ENM";
BA_ "SignalLongName" SG_ 1407 FrntPCMRspTypCstChgSetReq "Front PCM Response Type Customization Change Setting Request";
BA_ "SignalType" SG_ 1407 Sig0414 "ENM";
BA_ "SignalLongName" SG_ 1407 Sig0414 "Signal0170";
BA_ "SignalType" SG_ 1407 Sig3505 "ENM";
BA_ "SignalLongName" SG_ 1407 Sig3505 "Signal3894";
BA_ "SignalType" SG_ 1407 FrwdImpMtgnOpSlctCstChgSetReq "ENM";
BA_ "SignalLongName" SG_ 1407 FrwdImpMtgnOpSlctCstChgSetReq "Forward Impact Mitigation Operation Select Customization Change Setting Request";
BA_ "SignalType" SG_ 1407 Sig7708 "ENM";
BA_ "SignalLongName" SG_ 1407 Sig7708 "Signal7606";
BA_ "SignalType" SG_ 1407 Sig4159 "ENM";
BA_ "SignalLongName" SG_ 1407 Sig4159 "Signal4184";
BA_ "SignalType" SG_ 1407 GoNotfrCstChgSetReq "ENM";
BA_ "SignalLongName" SG_ 1407 GoNotfrCstChgSetReq "Go Notifier Customization Change Setting Request";
BA_ "SignalType" SG_ 1407 Sig2570 "ENM";
BA_ "SignalLongName" SG_ 1407 Sig2570 "Signal2565";
BA_ "SignalType" SG_ 1407 DispMeasSysExtnd "ENM";
BA_ "SignalLongName" SG_ 1407 DispMeasSysExtnd "Display Measurement System Extended";
BA_ "SignalType" SG_ 1407 CoDrvDrAjrStat "ENM";
BA_ "SignalLongName" SG_ 1407 CoDrvDrAjrStat "Co-Driver Door Ajar Status";
BA_ "SignalType" SG_ 1407 CoDrvDrAjrStat_Inv "ENM";
BA_ "SignalLongName" SG_ 1407 CoDrvDrAjrStat_Inv "Co-Driver Door Ajar Status Invalid";
BA_ "SignalType" SG_ 1407 AutoVehHldSwActv "ENM";
BA_ "SignalLongName" SG_ 1407 AutoVehHldSwActv "Automatic Vehicle Hold Switch Active";
BA_ "SignalType" SG_ 1407 AutoVehHldSwActv_Inv "ENM";
BA_ "SignalLongName" SG_ 1407 AutoVehHldSwActv_Inv "Automatic Vehicle Hold Switch Active Invalid";
BA_ "SignalType" SG_ 1407 LRDrAjrStat_Inv "ENM";
BA_ "SignalLongName" SG_ 1407 LRDrAjrStat_Inv "Left Rear Door Ajar Status Invalid";
BA_ "SignalType" SG_ 1407 LDWCtrlIndStat "ENM";
BA_ "SignalLongName" SG_ 1407 LDWCtrlIndStat "Lane Detection Warning And Control Indicator Status";
BA_ "SignalType" SG_ 1407 HtdStrgWhlInd "ENM";
BA_ "SignalLongName" SG_ 1407 HtdStrgWhlInd "Heated Steering Wheel Indication";
BA_ "SignalType" SG_ 1407 HtdStrgWhlCmd "ENM";
BA_ "SignalLongName" SG_ 1407 HtdStrgWhlCmd "Heated Steering Wheel Command";
BA_ "SignalType" SG_ 1407 AE44CrssBckInSftBtnStat "ENM";
BA_ "SignalLongName" SG_ 1407 AE44CrssBckInSftBtnStat "Advanced Park Assist Cross Back-In Soft Button Status";
BA_ "SignalType" SG_ 1407 RRDrAjrStat "ENM";
BA_ "SignalLongName" SG_ 1407 RRDrAjrStat "Right Rear Door Ajar Status";
BA_ "SignalType" SG_ 1407 RRDrAjrStat_Inv "ENM";
BA_ "SignalLongName" SG_ 1407 RRDrAjrStat_Inv "Right Rear Door Ajar Status Invalid";
BA_ "SignalType" SG_ 1407 Sig4423 "ENM";
BA_ "SignalLongName" SG_ 1407 Sig4423 "Signal4614";
BA_ "SignalType" SG_ 1407 Sig4421 "ENM";
BA_ "SignalLongName" SG_ 1407 Sig4421 "Signal4612";
BA_ "SignalType" SG_ 1407 LRDrAjrStat "ENM";
BA_ "SignalLongName" SG_ 1407 LRDrAjrStat "Left Rear Door Ajar Status";
BA_ "SignalType" SG_ 1407 AE44RghtSftBtnStatIPC "ENM";
BA_ "SignalLongName" SG_ 1407 AE44RghtSftBtnStatIPC "Advanced Park Assist Right Soft Button Status IPC";
BA_ "SignalType" SG_ 1407 AE44RghtSftBtnStat "ENM";
BA_ "SignalLongName" SG_ 1407 AE44RghtSftBtnStat "Advanced Park Assist Right Soft Button Status";
BA_ "SignalType" SG_ 1407 AE44PrllPrkSftBtnStat "ENM";
BA_ "SignalLongName" SG_ 1407 AE44PrllPrkSftBtnStat "Advanced Park Assist Parallel Parking Soft Button Status";
BA_ "SignalType" SG_ 1407 AE44LftSftBtnStatIPC "ENM";
BA_ "SignalLongName" SG_ 1407 AE44LftSftBtnStatIPC "Advanced Park Assist Left Soft Button Status IPC";
BA_ "SignalType" SG_ 1407 AE44LftSftBtnStat "ENM";
BA_ "SignalLongName" SG_ 1407 AE44LftSftBtnStat "Advanced Park Assist Left Soft Button Status";
BA_ "SignalType" SG_ 1407 AE44FcStatIPC "ENM";
BA_ "SignalLongName" SG_ 1407 AE44FcStatIPC "Advanced Park Assist Focus Status IPC";
BA_ "SignalType" SG_ 1407 AE44FcStatCSM "ENM";
BA_ "SignalLongName" SG_ 1407 AE44FcStatCSM "Advanced Park Assist Focus Status CSM";
BA_ "SignalType" SG_ 1407 AE44ExtPrkSftBtnStat "ENM";
BA_ "SignalLongName" SG_ 1407 AE44ExtPrkSftBtnStat "Advanced Park Assist Exit Park Soft Button Status";
BA_ "SignalType" SG_ 1407 DM5Denied "ENM";
BA_ "SignalLongName" SG_ 1407 DM5Denied "Drive Mode 5 Denied";
BA_ "SignalType" SG_ 1407 DM4Denied "ENM";
BA_ "SignalLongName" SG_ 1407 DM4Denied "Drive Mode 4 Denied";
BA_ "SignalType" SG_ 1407 DM3Denied "ENM";
BA_ "SignalLongName" SG_ 1407 DM3Denied "Drive Mode 3 Denied";
BA_ "SignalType" SG_ 1407 DM2Denied "ENM";
BA_ "SignalLongName" SG_ 1407 DM2Denied "Drive Mode 2 Denied";
BA_ "SignalType" SG_ 1407 DM1Denied "ENM";
BA_ "SignalLongName" SG_ 1407 DM1Denied "Drive Mode 1 Denied";
BA_ "SignalType" SG_ 1407 CrshEvntEnbld "ENM";
BA_ "SignalLongName" SG_ 1407 CrshEvntEnbld "Crash Event Enabled";
BA_ "SignalType" SG_ 1407 ClsnEvntDatRcrdgTrgrd "ENM";
BA_ "SignalLongName" SG_ 1407 ClsnEvntDatRcrdgTrgrd "Collision Event Data Recording Triggered";
BA_ "SignalType" SG_ 1407 AE44SrchSftBtnStat "ENM";
BA_ "SignalLongName" SG_ 1407 AE44SrchSftBtnStat "Advanced Park Assist Searching Soft Button Status";
BA_ "SignalType" SG_ 1407 Sig3484 "ENM";
BA_ "SignalLongName" SG_ 1407 Sig3484 "Signal3342";
BA_ "SignalType" SG_ 1407 FlToPsSwAtv "ENM";
BA_ "SignalLongName" SG_ 1407 FlToPsSwAtv "Flash To Pass Active";
BA_ "SignalType" SG_ 1407 DispMeasSys "ENM";
BA_ "SignalLongName" SG_ 1407 DispMeasSys "Display Measurement System";
BA_ "SignalType" SG_ 1407 DM8Denied "ENM";
BA_ "SignalLongName" SG_ 1407 DM8Denied "Drive Mode 8 Denied";
BA_ "SignalType" SG_ 1407 DM7Denied "ENM";
BA_ "SignalLongName" SG_ 1407 DM7Denied "Drive Mode 7 Denied";
BA_ "SignalType" SG_ 1407 DM6Denied "ENM";
BA_ "SignalLongName" SG_ 1407 DM6Denied "Drive Mode 6 Denied";
BA_ "SignalType" SG_ 1407 RstrCstDfltReq "ENM";
BA_ "SignalLongName" SG_ 1407 RstrCstDfltReq "Restore Customization Defaults Request";
BA_ "SignalType" SG_ 1407 LowBmAct "ENM";
BA_ "SignalLongName" SG_ 1407 LowBmAct "Low Beams Active";
BA_ "SignalType" SG_ 1407 LDWCSwCktShrtGndDiagFltActv "ENM";
BA_ "SignalLongName" SG_ 1407 LDWCSwCktShrtGndDiagFltActv "LaneDetectionWarningandControlSwitchCircuitShorttoGroundDiagnosticFaultActive";
BA_ "SignalType" SG_ 1407 LDWCSwCktShrtBatOpnDiagFltActv "ENM";
BA_ "SignalLongName" SG_ 1407 LDWCSwCktShrtBatOpnDiagFltActv "LaneDetectionWarningandControlSwitchCircuitShorttoBatteryorOpenDiagnosticFaultActive";
BA_ "SignalType" SG_ 1407 HtdWhlTempAmbtAirEstdOrgn "ENM";
BA_ "SignalLongName" SG_ 1407 HtdWhlTempAmbtAirEstdOrgn "Heated Wheel Temperature Ambient Air Estimated Origin";
BA_ "SignalType" SG_ 1407 HtdStrgWhlEnbl "ENM";
BA_ "SignalLongName" SG_ 1407 HtdStrgWhlEnbl "Heated Steering Wheel Enable";
BA_ "SignalType" SG_ 1407 HtdStrgWhlCtlSrc "ENM";
BA_ "SignalLongName" SG_ 1407 HtdStrgWhlCtlSrc "Heated Steering Wheel Control Source";
BA_ "SignalType" SG_ 1407 HighBmAct "ENM";
BA_ "SignalLongName" SG_ 1407 HighBmAct "High Beams Active";
BA_ "SignalType" SG_ 1407 SBZAlrtCstCrStVal "ENM";
BA_ "SignalLongName" SG_ 1407 SBZAlrtCstCrStVal "Side Blind Zone Alert Customization Current Setting Value";
BA_ "SignalType" SG_ 1407 WlcmLgtsActv "ENM";
BA_ "SignalLongName" SG_ 1407 WlcmLgtsActv "Welcome Lights Active";
BA_ "SignalType" SG_ 1407 Sig7578 "ENM";
BA_ "SignalLongName" SG_ 1407 Sig7578 "Signal7557";
BA_ "SignalType" SG_ 1407 TargaTopAjrStat "ENM";
BA_ "SignalLongName" SG_ 1407 TargaTopAjrStat "Targa Top Ajar Status";
BA_ "SignalType" SG_ 1407 Sig7570 "ENM";
BA_ "SignalLongName" SG_ 1407 Sig7570 "Signal7663";
BA_ "SignalType" SG_ 1407 Sig7565 "ENM";
BA_ "SignalLongName" SG_ 1407 Sig7565 "Signal7648";
BA_ "SignalType" SG_ 1407 Sig7563 "ENM";
BA_ "SignalLongName" SG_ 1407 Sig7563 "Signal7645";
BA_ "SignalType" SG_ 1407 Sig7555 "ENM";
BA_ "SignalLongName" SG_ 1407 Sig7555 "Signal7614";
BA_ "SignalType" SG_ 1407 AE44LtSftBtnSts "ENM";
BA_ "SignalLongName" SG_ 1407 AE44LtSftBtnSts "Advanced Park Assist Soft Button Status : Advanced Park Assist Left Soft Button Status";
BA_ "SignalType" SG_ 1407 AE44ExtPrkSftBtnSts "ENM";
BA_ "SignalLongName" SG_ 1407 AE44ExtPrkSftBtnSts "Advanced Park Assist Soft Button Status : Advanced Park Assist Exit Park Soft Button Status";
BA_ "SignalType" SG_ 1407 AE44CrssFrntInSftBtnStat "ENM";
BA_ "SignalLongName" SG_ 1407 AE44CrssFrntInSftBtnStat "Advanced Park Assist Soft Button Status : Advanced Park Assist Cross Front-In Soft Button Status";
BA_ "SignalType" SG_ 1407 AE44CrsBkInSftBtnSts "ENM";
BA_ "SignalLongName" SG_ 1407 AE44CrsBkInSftBtnSts "Advanced Park Assist Soft Button Status : Advanced Park Assist Cross Back-In Soft Button Status";
BA_ "SignalType" SG_ 1407 Sig0604 "ENM";
BA_ "SignalLongName" SG_ 1407 Sig0604 "Signal0534";
BA_ "SignalType" SG_ 1407 SuprRmtPrkDctvSoftBtnSts "ENM";
BA_ "SignalLongName" SG_ 1407 SuprRmtPrkDctvSoftBtnSts "Serial Data 235 : Supervised Remote Parking Deactivation Soft Button Status";
BA_ "SignalLongName" SG_ 1407 SD235_ARC "Serial Data 235 : Alive Rolling Count";
BA_ "SignalType" SG_ 1407 AE44SrchingSftBtnSts "ENM";
BA_ "SignalLongName" SG_ 1407 AE44SrchingSftBtnSts "Advanced Park Assist Soft Button Status : Advanced Park Assist Searching Soft Button Status";
BA_ "SignalType" SG_ 1407 AE44RtSftBtnStsIPC "ENM";
BA_ "SignalLongName" SG_ 1407 AE44RtSftBtnStsIPC "Advanced Park Assist Soft Button Status : Advanced Park Assist Right Soft Button Status IPC";
BA_ "SignalType" SG_ 1407 AE44RtSftBtnSts "ENM";
BA_ "SignalLongName" SG_ 1407 AE44RtSftBtnSts "Advanced Park Assist Soft Button Status : Advanced Park Assist Right Soft Button Status";
BA_ "SignalType" SG_ 1407 AE44ParallelPrkSftBtnSts "ENM";
BA_ "SignalLongName" SG_ 1407 AE44ParallelPrkSftBtnSts "Advanced Park Assist Soft Button Status : Advanced Park Assist Parallel Parking Soft Button Status";
BA_ "SignalType" SG_ 1407 AE44LtSftBtnStsIPC "ENM";
BA_ "SignalLongName" SG_ 1407 AE44LtSftBtnStsIPC "Advanced Park Assist Soft Button Status : Advanced Park Assist Left Soft Button Status IPC";
BA_ "SignalType" SG_ 1407 SRPUnableCnctExtSftBtnSts "ENM";
BA_ "SignalLongName" SG_ 1407 SRPUnableCnctExtSftBtnSts "Supervised Remote Parking Unable to Connect Status : Supervised Remote Parking Unable to Connect Exit Soft Button Status";
BA_ "SignalType" SG_ 1407 SRPUnableCnctTryAgnSftBtnSts "ENM";
BA_ "SignalLongName" SG_ 1407 SRPUnableCnctTryAgnSftBtnSts "Supervised Remote Parking Unable to Connect Status : Supervised Remote Parking Unable To Connect Try Again Soft Button Status";
BA_ "SignalType" SG_ 1407 SRPSptSeltnRmtSftBtnSts "ENM";
BA_ "SignalLongName" SG_ 1407 SRPSptSeltnRmtSftBtnSts "Serial Data 235 : Supervised Remote Parking Spot Selection Remote Soft Button Status";
BA_ "SignalType" SG_ 1407 SRPSptSeltnKeepLkSftBtnSts "ENM";
BA_ "SignalLongName" SG_ 1407 SRPSptSeltnKeepLkSftBtnSts "Serial Data 235 : Supervised Remote Parking Spot Selection Keep Looking Soft Button Status";
BA_ "SignalType" SG_ 1407 SRPSptSeltnAcceptSftBtnSts "ENM";
BA_ "SignalLongName" SG_ 1407 SRPSptSeltnAcceptSftBtnSts "Serial Data 235 : Supervised Remote Parking Spot Selection Accept Soft Button Status";
BA_ "SignalType" SG_ 1424 Sig0076 "ENM";
BA_ "SignalLongName" SG_ 1424 Sig0076 "Signal0009";
BA_ "SignalType" SG_ 1424 Sig0074 "ENM";
BA_ "SignalLongName" SG_ 1424 Sig0074 "Signal0005";
BA_ "SignalType" SG_ 1424 InfoSysStat "ENM";
BA_ "SignalLongName" SG_ 1424 InfoSysStat "Infotainment System State";
BA_ "SignalType" SG_ 1424 Sig0077 "ENM";
BA_ "SignalLongName" SG_ 1424 Sig0077 "Signal0011";
BA_ "SignalType" SG_ 1424 CTGI2P_CnvtTopStsAuth_Inv "ENM";
BA_ "SignalLongName" SG_ 1424 CTGI2P_CnvtTopStsAuth_Inv "Convertible Top General Information 2 Protected : Convertible Top Status Authenticated Invalid";
BA_ "SignalType" SG_ 1424 CTGI2P_CnvtTopStsAuth_DuD "ENM";
BA_ "SignalLongName" SG_ 1424 CTGI2P_CnvtTopStsAuth_DuD "Convertible Top General Information 2 Protected : Convertible Top Status Authenticated Don't Use Data";
BA_ "SignalType" SG_ 1424 CTGI2P_CnvtTopStsAuth "ENM";
BA_ "SignalLongName" SG_ 1424 CTGI2P_CnvtTopStsAuth "Convertible Top General Information 2 Protected : Convertible Top Status Authenticated";
BA_ "SignalType" SG_ 1424 TDAP_DrvrIdfrAuth "ENM";
BA_ "SignalLongName" SG_ 1424 TDAP_DrvrIdfrAuth "Serial Data 5 Protected : Driver Identifier Authenticated";
BA_ "SignalType" SG_ 1424 Sig0075 "ENM";
BA_ "SignalLongName" SG_ 1424 Sig0075 "Signal0007";
BA_ "SignalType" SG_ 1424 Sig0073 "ENM";
BA_ "SignalLongName" SG_ 1424 Sig0073 "Signal0004";
BA_ "SignalType" SG_ 1424 Sig0072 "ENM";
BA_ "SignalLongName" SG_ 1424 Sig0072 "Signal0003";
BA_ "SignalType" SG_ 1424 TrnSwAct "ENM";
BA_ "SignalLongName" SG_ 1424 TrnSwAct "Turn Switch Activation";
BA_ "SignalType" SG_ 1424 FrtStrgeCmptAjr "ENM";
BA_ "SignalLongName" SG_ 1424 FrtStrgeCmptAjr "Front Storage Compartment Ajar";
BA_ "SignalType" SG_ 1424 FrtStrgeCmptAjr_Inv "ENM";
BA_ "SignalLongName" SG_ 1424 FrtStrgeCmptAjr_Inv "Front Storage Compartment Ajar Invalid";
BA_ "SignalType" SG_ 1424 AE44SftBtnSeltdStatRw "ENM";
BA_ "SignalLongName" SG_ 1424 AE44SftBtnSeltdStatRw "Advanced Park Assist Soft Button Selected State Raw";
BA_ "SignalType" SG_ 1424 PrkAsstTrHtchPsntCstChgSetReq "ENM";
BA_ "SignalLongName" SG_ 1424 PrkAsstTrHtchPsntCstChgSetReq "Park Assist Trailer Hitch Present Customization Change Setting Request";
BA_ "SignalType" SG_ 1424 PrkAsstOnOffCstChgSetReq "ENM";
BA_ "SignalLongName" SG_ 1424 PrkAsstOnOffCstChgSetReq "Park Assist On Off Customization Change Setting Request";
BA_ "SignalType" SG_ 1424 SuprRmtPrkFcsStsVCU "ENM";
BA_ "SignalLongName" SG_ 1424 SuprRmtPrkFcsStsVCU "Supervised Remote Parking Focus Status VCU";
BA_ "SignalLongName" SG_ 1441 RPSU_ExpTmLgth "Remote Programming Scheduled Update : Expected Time Length";
BA_ "SignalLongName" SG_ 1441 RPSU_Dy "Remote Programming Scheduled Update : Day";
BA_ "SignalLongName" SG_ 1441 RPSU_Hr "Remote Programming Scheduled Update : Hour";
BA_ "SignalLongName" SG_ 1441 RPSU_Mins "Remote Programming Scheduled Update : Minutes";
BA_ "SignalLongName" SG_ 1441 RPSU_Secs "Remote Programming Scheduled Update : Seconds";
BA_ "SignalType" SG_ 1441 RPSU_Mth "ENM";
BA_ "SignalLongName" SG_ 1441 RPSU_Mth "Remote Programming Scheduled Update : Month";
BA_ "SignalLongName" SG_ 1441 RPSU_Yr "Remote Programming Scheduled Update : Year";
BA_ "SignalType" SG_ 1441 RPSU_Sts "ENM";
BA_ "SignalLongName" SG_ 1441 RPSU_Sts "Remote Programming Scheduled Update : Status";
BA_ "SignalLongName" SG_ 1441 ONPC_DprtrHrOfDyReq "Override Next Planned Charge : Departure Hour of Day Request";
BA_ "SignalType" SG_ 1441 ONPC_DprtrDyOfWkReq "ENM";
BA_ "SignalLongName" SG_ 1441 ONPC_DprtrDyOfWkReq "Override Next Planned Charge : Departure Day of Week Request";
BA_ "SignalLongName" SG_ 1441 ONPC_DprtrMinOfHrReq "Override Next Planned Charge : Departure Minute of Hour Request";
BA_ "SignalLongName" SG_ 1441 ONPC_TgtChrgLvlReq "Override Next Planned Charge : Target Charge Level Request";
BA_ "SignalType" SG_ 1441 ONPC_Req "ENM";
BA_ "SignalLongName" SG_ 1441 ONPC_Req "Override Next Planned Charge : Request";
BA_ "SignalLongName" SG_ 1441 TrlrLgth "Trailer Length";
BA_ "SignalLongName" SG_ 1441 TrlrHght "Trailer Height";
BA_ "SignalLongName" SG_ 1441 TrlrWdth "Trailer Width";
BA_ "SignalLongName" SG_ 1441 Sig0631 "Signal0544";
BA_ "SignalLongName" SG_ 1441 Sig0632 "Signal0545";
BA_ "SignalType" SG_ 1441 LnchCtlEngRPMReq "ENM";
BA_ "SignalLongName" SG_ 1441 LnchCtlEngRPMReq "Launch Control Engine RPM Request";
BA_ "SignalType" SG_ 1441 LBCCDRR_PstnNumReq "ENM";
BA_ "SignalLongName" SG_ 1441 LBCCDRR_PstnNumReq "Location Based Charging Customer Data Reset Request : Position Number Request";
BA_ "SignalType" SG_ 1441 LBCCDRR_ClrStrdPstnReq "ENM";
BA_ "SignalLongName" SG_ 1441 LBCCDRR_ClrStrdPstnReq "Location Based Charging Customer Data Reset Request : Clear Stored Position Request";
BA_ "SignalType" SG_ 1441 LnchCtlWhlSlReq "ENM";
BA_ "SignalLongName" SG_ 1441 LnchCtlWhlSlReq "Launch Control Wheel Slip Request";
BA_ "SignalType" SG_ 1441 Sig4819 "ENM";
BA_ "SignalLongName" SG_ 1441 Sig4819 "Signal5003";
BA_ "SignalType" SG_ 1441 Sig4614 "ENM";
BA_ "SignalLongName" SG_ 1441 Sig4614 "Signal4921";
BA_ "SignalType" SG_ 1441 AutoLnChgCstChgSetReq "ENM";
BA_ "SignalLongName" SG_ 1441 AutoLnChgCstChgSetReq "Automatic Lane Change Customization Change Setting Request";
BA_ "SignalType" SG_ 1441 Sig4842 "ENM";
BA_ "SignalLongName" SG_ 1441 Sig4842 "Signal5024";
BA_ "SignalType" SG_ 1441 Sig4867 "ENM";
BA_ "SignalLongName" SG_ 1441 Sig4867 "Signal5038";
BA_ "SignalType" SG_ 1441 LocBsdChrgPstnMdfnReq "ENM";
BA_ "SignalLongName" SG_ 1441 LocBsdChrgPstnMdfnReq "Location Based Charging Position Modification Request";
BA_ "SignalType" SG_ 1441 BrkPadLifeSysDrvrReq "ENM";
BA_ "SignalLongName" SG_ 1441 BrkPadLifeSysDrvrReq "Brake Pad Life System Driver Request";
BA_ "SignalType" SG_ 1441 PrkAsstStat "ENM";
BA_ "SignalLongName" SG_ 1441 PrkAsstStat "Park Assist Status";
BA_ "SignalType" SG_ 1441 Sig4889 "ENM";
BA_ "SignalLongName" SG_ 1441 Sig4889 "Signal5051";
BA_ "SignalType" SG_ 1441 ChrgDatReq "ENM";
BA_ "SignalLongName" SG_ 1441 ChrgDatReq "Charging Data Request";
BA_ "SignalType" SG_ 1441 ChrgCordThftAlrtCstSetReq "ENM";
BA_ "SignalLongName" SG_ 1441 ChrgCordThftAlrtCstSetReq "Charge Cord Theft Alert Customization Setting Request";
BA_ "SignalType" SG_ 1441 LnchCtlModeReq "ENM";
BA_ "SignalLongName" SG_ 1441 LnchCtlModeReq "Launch Control Mode Request";
BA_ "SignalType" SG_ 1441 HillDscntCtlCurrStatReq "ENM";
BA_ "SignalLongName" SG_ 1441 HillDscntCtlCurrStatReq "Hill Descent Control Current State Request";
BA_ "SignalType" SG_ 1441 ChrgSysAudblIndCstSetReq "ENM";
BA_ "SignalLongName" SG_ 1441 ChrgSysAudblIndCstSetReq "Charge System Audible Indication Customization Setting Request";
BA_ "SignalType" SG_ 1441 ChrgPwrLossAlrtCstSetReq "ENM";
BA_ "SignalLongName" SG_ 1441 ChrgPwrLossAlrtCstSetReq "Charge Power Loss Alert Customization Setting Request";
BA_ "SignalType" SG_ 1441 Sig4693 "ENM";
BA_ "SignalLongName" SG_ 1441 Sig4693 "Signal4939";
BA_ "SignalType" SG_ 1441 Sig4631 "ENM";
BA_ "SignalLongName" SG_ 1441 Sig4631 "Signal4929";
BA_ "SignalType" SG_ 1441 LocBsdChrgCstSetReq "ENM";
BA_ "SignalLongName" SG_ 1441 LocBsdChrgCstSetReq "Location Based Charging Customization Setting Request";
BA_ "SignalType" SG_ 1441 Sig3636 "ENM";
BA_ "SignalLongName" SG_ 1441 Sig3636 "Signal4021";
BA_ "SignalType" SG_ 1441 HiVltgBatStopChrgReq "ENM";
BA_ "SignalLongName" SG_ 1441 HiVltgBatStopChrgReq "High Voltage Battery Stop Charging Request";
BA_ "SignalType" SG_ 1441 Sig3585 "ENM";
BA_ "SignalLongName" SG_ 1441 Sig3585 "Signal3917";
BA_ "SignalType" SG_ 1441 Sig2638 "ENM";
BA_ "SignalLongName" SG_ 1441 Sig2638 "Signal2645";
BA_ "SignalType" SG_ 1441 DrvrSeltdTrlrPrsnt "ENM";
BA_ "SignalLongName" SG_ 1441 DrvrSeltdTrlrPrsnt "Driver Selected Trailer Present";
BA_ "SignalType" SG_ 1441 Sig0628 "ENM";
BA_ "SignalLongName" SG_ 1441 Sig0628 "Signal0521";
BA_ "SignalType" SG_ 1441 Sig7788 "ENM";
BA_ "SignalLongName" SG_ 1441 Sig7788 "Signal7754";
BA_ "SignalType" SG_ 1441 TripBEleclEngyEconRstReqd "ENM";
BA_ "SignalLongName" SG_ 1441 TripBEleclEngyEconRstReqd "Trip B Electrical Energy Economy Reset Requested";
BA_ "SignalType" SG_ 1441 TripAEleclEngyEconRstReqd "ENM";
BA_ "SignalLongName" SG_ 1441 TripAEleclEngyEconRstReqd "Trip A Electrical Energy Economy Reset Requested";
BA_ "SignalType" SG_ 1441 StlthModeActv "ENM";
BA_ "SignalLongName" SG_ 1441 StlthModeActv "Stealth Mode Active";
BA_ "SignalType" SG_ 1441 LnchCtlRelLineLckReqd "ENM";
BA_ "SignalLongName" SG_ 1441 LnchCtlRelLineLckReqd "Launch Control Release Line Lock Requested";
BA_ "SignalType" SG_ 1441 LifetmEleclEngyEconRstReqd "ENM";
BA_ "SignalLongName" SG_ 1441 LifetmEleclEngyEconRstReqd "Lifetime Electrical Energy Economy Reset Requested";
BA_ "SignalType" SG_ 1441 HzrdReqActv "ENM";
BA_ "SignalLongName" SG_ 1441 HzrdReqActv "Hazard Request Active";
BA_ "SignalType" SG_ 1441 OvrrdNextPlndCbnPrcndtngReq "ENM";
BA_ "SignalLongName" SG_ 1441 OvrrdNextPlndCbnPrcndtngReq "Override Next Planned Charge : Override Next Planned Cabin Preconditioning Request";
BA_ "SignalType" SG_ 1441 TrlrProfDrvrReqdSeltn "ENM";
BA_ "SignalLongName" SG_ 1441 TrlrProfDrvrReqdSeltn "Trailer Profile Driver Requested Selection";
BA_ "SignalType" SG_ 1441 UIDInStatusSD "ENM";
BA_ "SignalLongName" SG_ 1441 UIDInStatusSD "UID in Status";
BA_ "SignalLongName" SG_ 1529 TmSyncMsg "Time Sync Message";
BA_ "SignalLongName" SG_ 1529 UTCHrs "UTC Date and Time : Hours";
BA_ "SignalType" SG_ 1529 UTCDay_Inv "ENM";
BA_ "SignalLongName" SG_ 1529 UTCDay_Inv "UTC Date and Time : Day Invalid";
BA_ "SignalLongName" SG_ 1529 UTCDay "UTC Date and Time : Day";
BA_ "SignalLongName" SG_ 1529 UTCMin "UTC Date and Time : Minutes";
BA_ "SignalType" SG_ 1529 UTCHrs_Inv "ENM";
BA_ "SignalLongName" SG_ 1529 UTCHrs_Inv "UTC Date and Time : Hours Invalid";
BA_ "SignalType" SG_ 1529 UTCMth_Inv "ENM";
BA_ "SignalLongName" SG_ 1529 UTCMth_Inv "UTC Date and Time : Month Invalid";
BA_ "SignalType" SG_ 1529 UTCMth "ENM";
BA_ "SignalLongName" SG_ 1529 UTCMth "UTC Date and Time : Month";
BA_ "SignalType" SG_ 1529 UTCMin_Inv "ENM";
BA_ "SignalLongName" SG_ 1529 UTCMin_Inv "UTC Date and Time : Minutes Invalid";
BA_ "SignalLongName" SG_ 1529 UTCYr "UTC Date and Time : Year";
BA_ "SignalType" SG_ 1529 UTCSec_Inv "ENM";
BA_ "SignalLongName" SG_ 1529 UTCSec_Inv "UTC Date and Time : Seconds Invalid";
BA_ "SignalLongName" SG_ 1529 UTCSec "UTC Date and Time : Seconds";
BA_ "SignalType" SG_ 1529 UTCYr_Inv "ENM";
BA_ "SignalLongName" SG_ 1529 UTCYr_Inv "UTC Date and Time : Year Invalid";
BA_ "SignalLongName" SG_ 1529 EngIdleActvTm "Engine Idle Active Time";
BA_ "SignalLongName" SG_ 1529 EngRunActvTm "Engine Run Active Time";
BA_ "SignalLongName" SG_ 1529 ClmCtlTmToRchCbnCmfEstd "Climate Control Time To Reach Cabin Comfort Estimated";
BA_ "SignalLongName" SG_ 1529 ClmCtlPwrToMntCbnCmf "Climate Control Power To Maintain Cabin Comfort";
BA_ "SignalLongName" SG_ 1529 ClmCtlPwrToRchCbnCmf "Climate Control Power To Reach Cabin Comfort";
BA_ "SignalLongName" SG_ 1529 HtrCoreInltClntTmpCalc "Heater Core Inlet Coolant Temperature Calculated";
BA_ "SignalType" SG_ 1529 HtrCoreInltClntTmpCalc_Inv "ENM";
BA_ "SignalLongName" SG_ 1529 HtrCoreInltClntTmpCalc_Inv "Heater Core Inlet Coolant Temperature Calculated Invalid";
BA_ "SignalLongName" SG_ 1529 Sig3482 "Signal3340";
BA_ "SignalType" SG_ 1529 ClmCtlCustSetChgd "ENM";
BA_ "SignalLongName" SG_ 1529 ClmCtlCustSetChgd "Climate Control Customer Setting Changed";
BA_ "SignalType" SG_ 1529 ClmCtlCmfSetRchd "ENM";
BA_ "SignalLongName" SG_ 1529 ClmCtlCmfSetRchd "Climate Control Comfort Setting Reached";
BA_ "SignalType" SG_ 1529 ClmCtlCustSeltn "ENM";
BA_ "SignalLongName" SG_ 1529 ClmCtlCustSeltn "Climate Control Customer Selection";
BA_ "SignalType" SG_ 1529 RVCOprtgMd "ENM";
BA_ "SignalLongName" SG_ 1529 RVCOprtgMd "Regulated Voltage Control Operating Mode";
BA_ "SignalType" SG_ 1529 ExtEnvCondChgDtd "ENM";
BA_ "SignalLongName" SG_ 1529 ExtEnvCondChgDtd "Exterior Environmental Condition Change Detected";
BA_ "SignalLongName" SG_ 183 Sig4990 "Signal4653";
BA_ "SignalType" SG_ 183 Sig4991 "ENM";
BA_ "SignalLongName" SG_ 183 Sig4991 "Signal4654";
BA_ "SignalLongName" SG_ 183 Sig4992 "Signal4655";
BA_ "SignalType" SG_ 183 Sig4993 "ENM";
BA_ "SignalLongName" SG_ 183 Sig4993 "Signal4656";
BA_ "SignalType" SG_ 183 DrvModeConfDrvrResp "ENM";
BA_ "SignalLongName" SG_ 183 DrvModeConfDrvrResp "Drive Mode Confirmation Driver Response";
BA_ "SignalType" SG_ 183 Sig6842 "ENM";
BA_ "SignalLongName" SG_ 183 Sig6842 "Signal7010";
BA_ "SignalLongName" SG_ 76 eLSDActrDelTrq "Electronic Limited Slip Differential Actuator Delivered Torque";
BA_ "SignalType" SG_ 76 eLSDActrDelTrq_Inv "ENM";
BA_ "SignalLongName" SG_ 76 eLSDActrDelTrq_Inv "Electronic Limited Slip Differential Actuator Delivered Torque Invalid";
BA_ "SignalLongName" SG_ 76 eLSDActrThrCapUsd "Electronic Limited Slip Differential Actuator Thermal Capacity Used";
BA_ "SignalType" SG_ 76 eLSDActrThrCapUsd_Inv "ENM";
BA_ "SignalLongName" SG_ 76 eLSDActrThrCapUsd_Inv "Electronic Limited Slip Differential Actuator Thermal Capacity Used Invalid";
BA_ "SignalLongName" SG_ 1480 Sig8079 "Signal2563";
BA_ "SignalType" SG_ 1480 Sig8080 "ENM";
BA_ "SignalLongName" SG_ 1480 Sig8080 "Signal2564";
BA_ "SignalLongName" SG_ 192 BrkSysRdGrdAccel "Brake System Road Grade Acceleration";
BA_ "SignalType" SG_ 192 BrkSysRdGrdAccel_Inv "ENM";
BA_ "SignalLongName" SG_ 192 BrkSysRdGrdAccel_Inv "Brake System Road Grade Acceleration Invalid";
BA_ "SignalType" SG_ 703 MaxPwrModeReqd "ENM";
BA_ "SignalLongName" SG_ 703 MaxPwrModeReqd "Max Power Mode Requested";
BA_ "SignalType" SG_ 703 MaxPwrModeOvrrd "ENM";
BA_ "SignalLongName" SG_ 703 MaxPwrModeOvrrd "Max Power Mode Override";
BA_ "SignalType" SG_ 703 RrVirtBmpBrkgSts "ENM";
BA_ "SignalLongName" SG_ 703 RrVirtBmpBrkgSts "Rear Virtual Bumper Braking Status";
BA_ "SignalType" SG_ 703 BrkPulsSts "ENM";
BA_ "SignalLongName" SG_ 703 BrkPulsSts "Brake Pulse Status";
BA_ "SignalType" SG_ 938 WhlSlpSt "ENM";
BA_ "SignalLongName" SG_ 938 WhlSlpSt "Wheel Slip Status";
BA_ "SignalType" SG_ 938 BrkSysStatCrwlModeOvrrd "ENM";
BA_ "SignalLongName" SG_ 938 BrkSysStatCrwlModeOvrrd "Brake System State Crawl Mode Override";
BA_ "SignalType" SG_ 938 BrkSysHillRollCtrlStat "ENM";
BA_ "SignalLongName" SG_ 938 BrkSysHillRollCtrlStat "Brake System Hill Rollback Control Status";
BA_ "SignalType" SG_ 938 BrkSysHillStrtAsstStat "ENM";
BA_ "SignalLongName" SG_ 938 BrkSysHillStrtAsstStat "Brake System Hill Start Assist Status";
BA_ "SignalType" SG_ 938 TrlrBrkDtd "ENM";
BA_ "SignalLongName" SG_ 938 TrlrBrkDtd "Trailer Brakes Detected";
BA_ "SignalType" SG_ 938 EngDrgCtlFaild "ENM";
BA_ "SignalLongName" SG_ 938 EngDrgCtlFaild "Engine Drag Control Failed";
BA_ "SignalType" SG_ 938 EngDrgCtlActv "ENM";
BA_ "SignalLongName" SG_ 938 EngDrgCtlActv "Engine Drag Control Active";
BA_ "SignalType" SG_ 938 BrkSysHillRollCtrlAvl "ENM";
BA_ "SignalLongName" SG_ 938 BrkSysHillRollCtrlAvl "Brake System Hill Rollback Control Available";
BA_ "SignalLongName" SG_ 709 TrlrBrkgFOut "Trailer Braking Force Output";
BA_ "SignalType" SG_ 945 RdWhlAng_Inv "ENM";
BA_ "SignalLongName" SG_ 945 RdWhlAng_Inv "Off Road Display Information : Road Wheel Angle Invalid";
BA_ "SignalLongName" SG_ 945 RdWhlAng "Off Road Display Information : Road Wheel Angle";
BA_ "SignalType" SG_ 945 VehPtchAng_Inv "ENM";
BA_ "SignalLongName" SG_ 945 VehPtchAng_Inv "Off Road Display Information : Vehicle Pitch Angle Invalid";
BA_ "SignalLongName" SG_ 945 VehPtchAng "Off Road Display Information : Vehicle Pitch Angle";
BA_ "SignalType" SG_ 945 VehRollAng_Inv "ENM";
BA_ "SignalLongName" SG_ 945 VehRollAng_Inv "Off Road Display Information : Vehicle Roll Angle Invalid";
BA_ "SignalLongName" SG_ 945 VehRollAng "Off Road Display Information : Vehicle Roll Angle";
BA_ "SignalType" SG_ 1414 BSTGR_ReqdGr "ENM";
BA_ "SignalLongName" SG_ 1414 BSTGR_ReqdGr "Brake System Transmission Gear Request : Requested Gear";
BA_ "SignalType" SG_ 1414 BSTGR_ReqTyp "ENM";
BA_ "SignalLongName" SG_ 1414 BSTGR_ReqTyp "Brake System Transmission Gear Request : Request Type";
BA_ "SignalType" SG_ 1430 RrCrsTrfcBrkgSysSts "ENM";
BA_ "SignalLongName" SG_ 1430 RrCrsTrfcBrkgSysSts "Rear Cross Traffic Braking System Status";
BA_ "SignalLongName" SG_ 1481 BSCERDTC_CdNum "Brake System Control Emissions Related DTC : Code Number";
BA_ "SignalType" SG_ 1481 BSCERDTC_SysDes "ENM";
BA_ "SignalLongName" SG_ 1481 BSCERDTC_SysDes "Brake System Control Emissions Related DTC : System Designator";
BA_ "SignalType" SG_ 1481 EngMntPrfMdRq "ENM";
BA_ "SignalLongName" SG_ 1481 EngMntPrfMdRq "Engine Mounts Performance Mode Request";
BA_ "SignalType" SG_ 1481 ACCPrfMdRq "ENM";
BA_ "SignalLongName" SG_ 1481 ACCPrfMdRq "Adaptive Cruise Control Performance Mode Request";
BA_ "SignalType" SG_ 1481 TireRRLoTracIndOn "ENM";
BA_ "SignalLongName" SG_ 1481 TireRRLoTracIndOn "Tire Low Traction Information : Tire Right Rear Low Traction Indication On";
BA_ "SignalType" SG_ 1481 TireRFLoTracIndOn "ENM";
BA_ "SignalLongName" SG_ 1481 TireRFLoTracIndOn "Tire Low Traction Information : Tire Right Front Low Traction Indication On";
BA_ "SignalType" SG_ 1481 TireLRLoTracIndOn "ENM";
BA_ "SignalLongName" SG_ 1481 TireLRLoTracIndOn "Tire Low Traction Information : Tire Left Rear Low Traction Indication On";
BA_ "SignalType" SG_ 1481 TireLFLoTracIndOn "ENM";
BA_ "SignalLongName" SG_ 1481 TireLFLoTracIndOn "Tire Low Traction Information : Tire Left Front Low Traction Indication On";
BA_ "SignalType" SG_ 1481 RrStrPrfMdRq "ENM";
BA_ "SignalLongName" SG_ 1481 RrStrPrfMdRq "Rear Steering Performance Mode Request";
BA_ "SignalType" SG_ 1481 ExhSndPrfMdRq "ENM";
BA_ "SignalLongName" SG_ 1481 ExhSndPrfMdRq "Exhaust Sound Performance Mode Request";
BA_ "SignalType" SG_ 1481 WthrSnwModeBrkPedVisDispVal "ENM";
BA_ "SignalLongName" SG_ 1481 WthrSnwModeBrkPedVisDispVal "Weather Snow Mode Brake Pedal Visualization Display Value";
BA_ "SignalType" SG_ 1481 WthrSnwModeActvAeroVisDispVal "ENM";
BA_ "SignalLongName" SG_ 1481 WthrSnwModeActvAeroVisDispVal "Weather Snow Mode Active Aerodynamics Visualization Display Value";
BA_ "SignalType" SG_ 1481 StrPrfMdRq "ENM";
BA_ "SignalLongName" SG_ 1481 StrPrfMdRq "Steering Performance Mode Request";
BA_ "SignalType" SG_ 1481 WthrSnwModePwrtrnVisDispVal "ENM";
BA_ "SignalLongName" SG_ 1481 WthrSnwModePwrtrnVisDispVal "Weather Snow Mode Powertrain Visualization Display Value";
BA_ "SignalType" SG_ 1481 WthrSnwModeESCVisDispVal "ENM";
BA_ "SignalLongName" SG_ 1481 WthrSnwModeESCVisDispVal "Weather Snow Mode ESC Visualization Display Value";
BA_ "SignalType" SG_ 1481 WthrSnwModeDrvlineVisDispVal "ENM";
BA_ "SignalLongName" SG_ 1481 WthrSnwModeDrvlineVisDispVal "Weather Snow Mode Driveline Visualization Display Value";
BA_ "SignalType" SG_ 1481 WthrSnwModeSndVisDispVal "ENM";
BA_ "SignalLongName" SG_ 1481 WthrSnwModeSndVisDispVal "Weather Snow Mode Sound Visualization Display Value";
BA_ "SignalType" SG_ 1481 WthrSnwModeRideHghtVisDispVal "ENM";
BA_ "SignalLongName" SG_ 1481 WthrSnwModeRideHghtVisDispVal "Weather Snow Mode Ride Height Visualization Display Value";
BA_ "SignalType" SG_ 1481 DrvModeConfIndReq "ENM";
BA_ "SignalLongName" SG_ 1481 DrvModeConfIndReq "Drive Mode Confirmation Indication Request";
BA_ "SignalType" SG_ 1481 ESCPrs "ENM";
BA_ "SignalLongName" SG_ 1481 ESCPrs "Electronic Stability Control Present";
BA_ "SignalType" SG_ 1481 BrkSysCtlEmsnsRltdMalfActv "ENM";
BA_ "SignalLongName" SG_ 1481 BrkSysCtlEmsnsRltdMalfActv "Brake System Control Emissions Related Malfunction Active";
BA_ "SignalType" SG_ 1481 WthrSnwModeSpnsnVisDispVal "ENM";
BA_ "SignalLongName" SG_ 1481 WthrSnwModeSpnsnVisDispVal "Weather Snow Mode Suspension Visualization Display Value";
BA_ "SignalLongName" SG_ 1265 LnchCtlAccelPedVal "Launch Control Accelerator Pedal Value";
BA_ "SignalType" SG_ 1265 BrkFldLvlSt "ENM";
BA_ "SignalLongName" SG_ 1265 BrkFldLvlSt "Brake Fluid Level Status";
BA_ "SignalLongName" SG_ 1265 PIMRI_EBCM_RcntlyProgInd "Programming Inspection and Maintenance Readiness Indication - EBCM : Recently Programmed Indicator";
BA_ "SignalType" SG_ 1265 PIMRI_EBCM_PrmntDTCInd "ENM";
BA_ "SignalLongName" SG_ 1265 PIMRI_EBCM_PrmntDTCInd "Programming Inspection and Maintenance Readiness Indication - EBCM : Permanent DTC Indicator";
BA_ "SignalType" SG_ 1265 PIMRI_EBCM_FltsPrsntInd "ENM";
BA_ "SignalLongName" SG_ 1265 PIMRI_EBCM_FltsPrsntInd "Programming Inspection and Maintenance Readiness Indication - EBCM : Faults Present Indicator";
BA_ "SignalLongName" SG_ 1265 LnchCtlBrkPresHiResVal "Launch Control Brake Pressure High Resolution Value";
BA_ "SignalLongName" SG_ 1265 DrvModeHptcStReqPuls "Drive Mode Haptic Seat Request Information : Drive Mode Haptic Seat Request Pulses";
BA_ "SignalType" SG_ 1265 MaxPwrModeDndIndOn "ENM";
BA_ "SignalLongName" SG_ 1265 MaxPwrModeDndIndOn "Max Power Mode Denied Indication On";
BA_ "SignalType" SG_ 1265 Sig4246 "ENM";
BA_ "SignalLongName" SG_ 1265 Sig4246 "Signal4372";
BA_ "SignalType" SG_ 1265 Sig4244 "ENM";
BA_ "SignalLongName" SG_ 1265 Sig4244 "Signal4370";
BA_ "SignalLongName" SG_ 1265 DrvModeHptcStReqSeqNum "Drive Mode Haptic Seat Request Information : Drive Mode Haptic Seat Request Sequence Number";
BA_ "SignalType" SG_ 1265 Sig4248 "ENM";
BA_ "SignalLongName" SG_ 1265 Sig4248 "Signal4374";
BA_ "SignalType" SG_ 1265 Sig4247 "ENM";
BA_ "SignalLongName" SG_ 1265 Sig4247 "Signal4373";
BA_ "SignalType" SG_ 1265 Sig4249 "ENM";
BA_ "SignalLongName" SG_ 1265 Sig4249 "Signal4375";
BA_ "SignalLongName" SG_ 69 Sig2438 "Signal2343";
BA_ "SignalLongName" SG_ 69 Sig2617 "Signal2620";
BA_ "SignalLongName" SG_ 69 Sig0676 "Signal0590";
BA_ "SignalType" SG_ 69 Sig0677 "ENM";
BA_ "SignalLongName" SG_ 69 Sig0677 "Signal0591";
BA_ "SignalLongName" SG_ 69 Sig0678 "Signal0594";
BA_ "SignalType" SG_ 69 Sig0679 "ENM";
BA_ "SignalLongName" SG_ 69 Sig0679 "Signal0595";
BA_ "SignalLongName" SG_ 69 Sig0680 "Signal0598";
BA_ "SignalType" SG_ 69 Sig0681 "ENM";
BA_ "SignalLongName" SG_ 69 Sig0681 "Signal0599";
BA_ "SignalLongName" SG_ 69 Sig0684 "Signal0600";
BA_ "SignalType" SG_ 69 Sig0685 "ENM";
BA_ "SignalLongName" SG_ 69 Sig0685 "Signal0601";
BA_ "SignalLongName" SG_ 69 Sig0686 "Signal0596";
BA_ "SignalType" SG_ 69 Sig0687 "ENM";
BA_ "SignalLongName" SG_ 69 Sig0687 "Signal0597";
BA_ "SignalType" SG_ 69 Sig2629 "ENM";
BA_ "SignalLongName" SG_ 69 Sig2629 "Signal2633";
BA_ "SignalLongName" SG_ 69 Sig2628 "Signal2632";
BA_ "SignalLongName" SG_ 69 EngPrdctStdyStTrq "Engine Predicted Steady State Torque";
BA_ "SignalType" SG_ 69 EngPrdctStdyStTrq_Inv "ENM";
BA_ "SignalLongName" SG_ 69 EngPrdctStdyStTrq_Inv "Engine Predicted Steady State Torque Invalid";
BA_ "SignalLongName" SG_ 69 Sig2664 "Signal2670";
BA_ "SignalLongName" SG_ 69 Sig2665 "Signal2671";
BA_ "SignalLongName" SG_ 69 Sig2610 "Signal2615";
BA_ "SignalLongName" SG_ 69 Sig2612 "Signal2619";
BA_ "SignalType" SG_ 69 Sig0606 "ENM";
BA_ "SignalLongName" SG_ 69 Sig0606 "Signal0602";
BA_ "SignalType" SG_ 69 Sig2624 "ENM";
BA_ "SignalLongName" SG_ 69 Sig2624 "Signal2630";
BA_ "SignalType" SG_ 69 Sig0607 "ENM";
BA_ "SignalLongName" SG_ 69 Sig0607 "Signal0603";
BA_ "SignalType" SG_ 69 Sig2657 "ENM";
BA_ "SignalLongName" SG_ 69 Sig2657 "Signal2666";
BA_ "SignalType" SG_ 69 Sig2656 "ENM";
BA_ "SignalLongName" SG_ 69 Sig2656 "Signal2665";
BA_ "SignalType" SG_ 69 Sig2625 "ENM";
BA_ "SignalLongName" SG_ 69 Sig2625 "Signal2631";
BA_ "SignalType" SG_ 69 Sig7777 "ENM";
BA_ "SignalLongName" SG_ 69 Sig7777 "Signal7726";
BA_ "SignalType" SG_ 69 Sig7778 "ENM";
BA_ "SignalLongName" SG_ 69 Sig7778 "Signal7727";
BA_ "SignalType" SG_ 69 Sig2622 "ENM";
BA_ "SignalLongName" SG_ 69 Sig2622 "Signal2628";
BA_ "SignalType" SG_ 69 Sig2609 "ENM";
BA_ "SignalLongName" SG_ 69 Sig2609 "Signal2618";
BA_ "SignalType" SG_ 69 Sig0474 "ENM";
BA_ "SignalLongName" SG_ 69 Sig0474 "Signal0424";
BA_ "SignalLongName" SG_ 204 Sig0682 "Signal0592";
BA_ "SignalType" SG_ 204 Sig0683 "ENM";
BA_ "SignalLongName" SG_ 204 Sig0683 "Signal0593";
BA_ "SignalLongName" SG_ 204 Sig0513 "Signal0466";
BA_ "SignalType" SG_ 681 Sig2613 "ENM";
BA_ "SignalLongName" SG_ 681 Sig2613 "Signal2617";
BA_ "SignalType" SG_ 681 Sig2611 "ENM";
BA_ "SignalLongName" SG_ 681 Sig2611 "Signal2616";
BA_ "SignalLongName" SG_ 933 Sig2670 "Signal2675";
BA_ "SignalType" SG_ 933 Sig2522 "ENM";
BA_ "SignalLongName" SG_ 933 Sig2522 "Signal2469";
BA_ "SignalType" SG_ 933 Sig2521 "ENM";
BA_ "SignalLongName" SG_ 933 Sig2521 "Signal2468";
BA_ "SignalType" SG_ 933 Sig2520 "ENM";
BA_ "SignalLongName" SG_ 933 Sig2520 "Signal2467";
BA_ "SignalLongName" SG_ 933 Sig2669 "Signal2676";
BA_ "SignalType" SG_ 933 Sig2523 "ENM";
BA_ "SignalLongName" SG_ 933 Sig2523 "Signal2470";
BA_ "SignalType" SG_ 933 EASSI_StrtStpSt "ENM";
BA_ "SignalLongName" SG_ 933 EASSI_StrtStpSt "Engine Auto Start Stop Information : Start Stop State";
BA_ "SignalType" SG_ 933 EASSI_StlDtd "ENM";
BA_ "SignalLongName" SG_ 933 EASSI_StlDtd "Engine Auto Start Stop Information : Stall Detected";
BA_ "SignalType" SG_ 933 EASSI_FlRqOn "ENM";
BA_ "SignalLongName" SG_ 933 EASSI_FlRqOn "Engine Auto Start Stop Information : Fuel Requested On";
BA_ "SignalLongName" SG_ 933 Sig2413 "Signal2316";
BA_ "SignalType" SG_ 933 Sig2466 "ENM";
BA_ "SignalLongName" SG_ 933 Sig2466 "Signal2585";
BA_ "SignalType" SG_ 933 Sig2465 "ENM";
BA_ "SignalLongName" SG_ 933 Sig2465 "Signal2584";
BA_ "SignalType" SG_ 933 Sig2464 "ENM";
BA_ "SignalLongName" SG_ 933 Sig2464 "Signal2583";
BA_ "SignalType" SG_ 933 Sig2463 "ENM";
BA_ "SignalLongName" SG_ 933 Sig2463 "Signal2582";
BA_ "SignalLongName" SG_ 933 Sig2623 "Signal2629";
BA_ "SignalLongName" SG_ 933 GenFldDutCyc "Generator Field Duty Cycle";
BA_ "SignalLongName" SG_ 933 Sig2584 "Signal2579";
BA_ "SignalType" SG_ 933 Sig2554 "ENM";
BA_ "SignalLongName" SG_ 933 Sig2554 "Signal2683";
BA_ "SignalType" SG_ 933 Sig2562 "ENM";
BA_ "SignalLongName" SG_ 933 Sig2562 "Signal2686";
BA_ "SignalType" SG_ 933 Sig2561 "ENM";
BA_ "SignalLongName" SG_ 933 Sig2561 "Signal2685";
BA_ "SignalType" SG_ 933 Sig2555 "ENM";
BA_ "SignalLongName" SG_ 933 Sig2555 "Signal2684";
BA_ "SignalType" SG_ 933 Sig7805 "ENM";
BA_ "SignalLongName" SG_ 933 Sig7805 "Signal7596";
BA_ "SignalType" SG_ 933 Sig2608 "ENM";
BA_ "SignalLongName" SG_ 933 Sig2608 "Signal2614";
BA_ "SignalType" SG_ 933 EngAtStpNtPrbl "ENM";
BA_ "SignalLongName" SG_ 933 EngAtStpNtPrbl "Engine Auto Stop Not Probable";
BA_ "SignalType" SG_ 933 Sig0470 "ENM";
BA_ "SignalLongName" SG_ 933 Sig0470 "Signal0408";
BA_ "SignalType" SG_ 933 Sig2589 "ENM";
BA_ "SignalLongName" SG_ 933 Sig2589 "Signal2590";
BA_ "SignalType" SG_ 933 Sig2571 "ENM";
BA_ "SignalLongName" SG_ 933 Sig2571 "Signal2566";
BA_ "SignalType" SG_ 933 CltTpTrvAchv "ENM";
BA_ "SignalLongName" SG_ 933 CltTpTrvAchv "Clutch Top of Travel Achieved";
BA_ "SignalType" SG_ 933 CltTpTrvAchv_Inv "ENM";
BA_ "SignalLongName" SG_ 933 CltTpTrvAchv_Inv "Clutch Top of Travel Achieved Invalid";
BA_ "SignalType" SG_ 933 Sig8060 "ENM";
BA_ "SignalLongName" SG_ 933 Sig8060 "Signal8040";
BA_ "SignalType" SG_ 933 Sig7665 "ENM";
BA_ "SignalLongName" SG_ 933 Sig7665 "Signal7597";
BA_ "SignalType" SG_ 933 Sig5015 "ENM";
BA_ "SignalLongName" SG_ 933 Sig5015 "Signal5054";
BA_ "SignalType" SG_ 933 GlwPlgCrnkDlyActv "ENM";
BA_ "SignalLongName" SG_ 933 GlwPlgCrnkDlyActv "Glow Plugs Crank Delay Active";
BA_ "SignalType" SG_ 933 Sig2662 "ENM";
BA_ "SignalLongName" SG_ 933 Sig2662 "Signal2662";
BA_ "SignalType" SG_ 933 Sig2632 "ENM";
BA_ "SignalLongName" SG_ 933 Sig2632 "Signal2638";
BA_ "SignalType" SG_ 933 Sig2616 "ENM";
BA_ "SignalLongName" SG_ 933 Sig2616 "Signal2623";
BA_ "SignalType" SG_ 933 Sig2603 "ENM";
BA_ "SignalLongName" SG_ 933 Sig2603 "Signal2609";
BA_ "SignalLongName" SG_ 933 Sig2560 "Signal2554";
BA_ "SignalType" SG_ 933 Sig2559 "ENM";
BA_ "SignalLongName" SG_ 933 Sig2559 "Signal2553";
BA_ "SignalLongName" SG_ 933 Sig2556 "Signal2552";
BA_ "SignalType" SG_ 933 Sig0665 "ENM";
BA_ "SignalLongName" SG_ 933 Sig0665 "Signal6596";
BA_ "SignalLongName" SG_ 933 Sig5717 "Signal6595";
VAL_ 727 GPSC_PPSLat_Inv 0 "FALSE" 1 "TRUE" ;
VAL_ 727 GPSC_PPSLong_Inv 0 "FALSE" 1 "TRUE" ;
VAL_ 1315 HMII1P_LnFllwgChInterFltDtdAuth 0 "FALSE" 1 "TRUE" ;
VAL_ 1315 HMII1P_IPCDispStsAuth 0 "Unknown" 1 "Normal" 2 "Fault" ;
VAL_ 1315 HMII1P_ChmSysSOHAuth 0 "Unknown" 1 "Healthy" 2 "Faulted" ;
VAL_ 1315 HMII1P_AutoModeSpdLimCnfrmdAuth 0 "FALSE" 1 "TRUE" ;
VAL_ 1315 HMII1P_ACCSetTypAuth 0 "Manual" 1 "Auto" ;
VAL_ 2147745832 Sig3538 0 "FALSE" 1 "TRUE" ;
VAL_ 230 Sig3562 0 "None" 1 "Bus Precharging" 2 "12V Gen Mode" 3 "Battery Connected" ;
VAL_ 230 Sig3561 0 "Request None" 1 "Normal Open" 2 "Controlled Open" 3 "Emergency Open" 4 "Request Close" ;
VAL_ 39 Sig3568 0 "None" 1 "Low Severity" 2 "Medium Severity" 3 "High Severity" ;
VAL_ 39 Sig3567 0 "Open" 1 "Precharge" 2 "Close" ;
VAL_ 39 Sig3566 0 "Indeterminate" 1 "False" 2 "True" ;
VAL_ 1314 HSP_HptcStPrsntAuth 0 "FALSE" 1 "TRUE" ;
VAL_ 1314 HSP_HptcStOprtlStsAuth 0 "Normal Operation" 1 "Unknown" 2 "Failed" ;
VAL_ 1314 HSP_HptcStActvAuth 0 "FALSE" 1 "TRUE" ;
VAL_ 1314 HSP_DrvAlrtTypCstCurrSetValAuth 0 "SETTING_UNKNOWN" 1 "CHIME" 2 "SEAT" ;
VAL_ 1314 HptcStLnFllwgUnv 0 "FALSE" 1 "TRUE" ;
VAL_ 87 HVPPP_FrwdVsnModeCmdAuth 0 "Not Reporting Object Data" 1 "Reporting Object Data" ;
VAL_ 87 HVPPP_HstVehLatVelAuth_Inv 0 "FALSE" 1 "TRUE" ;
VAL_ 87 HVPPP_HstVehLngVelAuth_Inv 0 "FALSE" 1 "TRUE" ;
VAL_ 87 HVPPP_HstVehPathModeAuth 0 "Disabled" 1 "Low Speed" 2 "High Speed" ;
VAL_ 87 HVPPP_HstVehTrvlDirAuth 0 "Unknown" 1 "Forward or Stopped on a Forward Gear" 2 "Reversed or Stopped in a Reverse Gear" 3 "Other" ;
VAL_ 87 HVPPP_HstVehVelAuth_Inv 0 "FALSE" 1 "TRUE" ;
VAL_ 87 HVPPP_LngRngRadarModeCmdAuth 0 "Not Radiating" 1 "Not Reporting Object Data" 2 "Reporting" ;
VAL_ 87 HVPPP_HstVehYawRateAuth_Inv 0 "FALSE" 1 "TRUE" ;
VAL_ 87 HVPPP_ShrtRngRadarModeCmdAuth 0 "Not Radiating" 1 "Not Reporting Object Data" 2 "Reporting Object Data" ;
VAL_ 87 HVPPP_ObjsRetndRrwdSnsrsAuth 0 "Unknown" 1 "Objects Reported" 2 "No Objects Reported" ;
VAL_ 87 HVPPP_ObjsRetndFrwdSnsrsAuth 0 "Unknown" 1 "Objects Reported" 2 "No Objects Reported" ;
VAL_ 87 DrvrMonSysModeCmd 0 "Not Radiating" 1 "Not Reporting Object Data" 2 "Reporting Object Data" ;
VAL_ 87 LnFllwgFtrStatAuth 0 "Off" 1 "Unavailable" 2 "Disabled" 3 "Enabled" 4 "Active" 5 "Cautionary" 6 "Override" 7 "Degraded" 8 "No Return" 9 "Ended" 10 "Non-Responsive Driver" ;
VAL_ 87 HstVehRideHghtOfst_Inv 0 "FALSE" 1 "TRUE" ;
VAL_ 87 HstVehRideHghtOfstSts 0 "In Range" 1 "Out of Range" ;
VAL_ 38 Sig3583 0 "Unknown" 1 "Forward or Stopped on a Forward Gear" 2 "Reversed or Stopped in a Reverse Gear" 3 "Other" ;
VAL_ 38 Sig3581 0 "In Range" 1 "Out of Range" ;
VAL_ 38 Sig3582 0 "FALSE" 1 "TRUE" ;
VAL_ 956 Bat12VCfg 0 "PbA Only" 1 "Li Only" 2 "Dual PbA" 3 "Dual Li" 4 "Dual Mix- PbA Primary" 5 "Dual Mix- Li Primary" 6 "Reserved" 7 "Unknown Batt Type" ;
VAL_ 956 PTExPrtclFltrMnlRgnModeActvtd 0 "FALSE" 1 "TRUE" ;
VAL_ 956 IBSBatVlt_Inv 0 "FALSE" 1 "TRUE" ;
VAL_ 1285 HptcStFldIndOn 0 "FALSE" 1 "TRUE" ;
VAL_ 704 StrgWhlTrqIntegSts 0 "Unknown" 1 "Redundant ASIL D" 2 "Non Redundant ASIL D" 3 "Failed" ;
VAL_ 704 StrgWhlHndsOffDtnStat 0 "Hands On" 1 "Hands Off" 2 "Unknown" ;
VAL_ 1419 Sig7713 0 "NO_ACTION" 1 "ACTIVE" 2 "CANCEL_CHIME" 3 "RESERVED_1" ;
VAL_ 1419 Sig7709 0 "SETTING_UNKNOWN" 1 "OFF" 2 "ALERT" 3 "RESERVED_3" 4 "RESERVED_4" 5 "RESERVED_5" 6 "RESERVED_6" 7 "RESERVED_7" ;
VAL_ 1419 Sig3506 0 "SETTING_UNKNOWN" 1 "AUTOMATIC_HIGH_BEAM" 2 "GLARE_FREE_HIGH_BEAM" 3 "RESERVED_3" 4 "\?? RESERVED_4" 5 "RESERVED_5" 6 "RESERVED_6" 7 "RESERVED_7" ;
VAL_ 1419 Sig3504 0 "FALSE" 1 "TRUE" ;
VAL_ 1419 Sig3503 0 "FALSE" 1 "TRUE" ;
VAL_ 1419 Sig3502 0 "FALSE" 1 "TRUE" ;
VAL_ 1419 Sig3501 0 "FALSE" 1 "TRUE" ;
VAL_ 1419 Sig3500 0 "FALSE" 1 "TRUE" ;
VAL_ 1419 Sig3499 0 "FALSE" 1 "TRUE" ;
VAL_ 1419 Sig3498 0 "FALSE" 1 "TRUE" ;
VAL_ 1419 Sig0451 0 "FALSE" 1 "TRUE" ;
VAL_ 1419 Sig7707 0 "FALSE" 1 "TRUE" ;
VAL_ 1419 Sig7706 0 "FALSE" 1 "TRUE" ;
VAL_ 1419 Sig7705 0 "FALSE" 1 "TRUE" ;
VAL_ 1419 Sig7704 0 "FALSE" 1 "TRUE" ;
VAL_ 1419 Sig7703 0 "FALSE" 1 "TRUE" ;
VAL_ 1419 Sig7702 0 "FALSE" 1 "TRUE" ;
VAL_ 1419 Sig7701 0 "FALSE" 1 "TRUE" ;
VAL_ 1419 Sig3507 0 "FALSE" 1 "TRUE" ;
VAL_ 1419 Sig7710 0 "FALSE" 1 "TRUE" ;
VAL_ 1501 Sig7559 0 "UnKnown" 1 "No Sign Detected" 2 "End of Speed Limit" 3 "End of All Restrictions" 4 "Begin of Motorway" 5 "End of Motorway" 6 "Begin of Expressway" 7 "End of Expressway" 8 "Begin of Play Street Zone" 9 "End of Play Street Zone" 10 "Begin of Passing Restriction" 11 "End of Passing Restriction" 12 "No Entry" 13 "Begin of City Limits" 14 "End of City Limits" 15 "Speed Limit 5" 16 "Speed Limit 10" 17 "Speed Limit 15" 18 "Speed Limit 20" 19 "Speed Limit 25" 20 "Speed Limit 30" 21 "Speed Limit 35" 22 "Speed Limit 40" 23 "Speed Limit 45" 24 "Speed Limit 50" 25 "Speed Limit 55" 26 "Speed Limit 60" 27 "Speed Limit 65" 28 "Speed Limit 70" 29 "Speed Limit 75" 30 "Speed Limit 80" 31 "Speed Limit 85" 32 "Speed Limit 90" 33 "Speed Limit 95" 34 "Speed Limit 100" 35 "Speed Limit 105" 36 "Speed Limit 110" 37 "Speed Limit 115" 38 "Speed Limit 120" 39 "Speed Limit 125" 40 "Speed Limit 130" 41 "Speed Limit 135" 42 "Speed Limit 140" 43 "Speed Limit 145" 44 "Speed Limit 150" 45 "Speed Limit 155" 46 "Speed Limit 160" 47 "Speed Limit 165" 48 "Speed Limit 170" 49 "Speed Limit 175" 50 "Speed Limit 180" 51 "Speed Limit 185" 52 "Speed Limit 190" 53 "Speed Limit 195" 54 "Speed Limit 200" ;
VAL_ 1501 Sig7557 0 "UnKnown" 1 "No Sign Detected" 2 "End of Speed Limit" 3 "End of All Restrictions" 4 "Begin of Motorway" 5 "End of Motorway" 6 "Begin of Expressway" 7 "End of Expressway" 8 "Begin of Play Street Zone" 9 "End of Play Street Zone" 10 "Begin of Passing Restriction" 11 "End of Passing Restriction" 12 "No Entry" 13 "Begin of City Limits" 14 "End of City Limits" 15 "Speed Limit 5" 16 "Speed Limit 10" 17 "Speed Limit 15" 18 "Speed Limit 20" 19 "Speed Limit 25" 20 "Speed Limit 30" 21 "Speed Limit 35" 22 "Speed Limit 40" 23 "Speed Limit 45" 24 "Speed Limit 50" 25 "Speed Limit 55" 26 "Speed Limit 60" 27 "Speed Limit 65" 28 "Speed Limit 70" 29 "Speed Limit 75" 30 "Speed Limit 80" 31 "Speed Limit 85" 32 "Speed Limit 90" 33 "Speed Limit 95" 34 "Speed Limit 100" 35 "Speed Limit 105" 36 "Speed Limit 110" 37 "Speed Limit 115" 38 "Speed Limit 120" 39 "Speed Limit 125" 40 "Speed Limit 130" 41 "Speed Limit 135" 42 "Speed Limit 140" 43 "Speed Limit 145" 44 "Speed Limit 150" 45 "Speed Limit 155" 46 "Speed Limit 160" 47 "Speed Limit 165" 48 "Speed Limit 170" 49 "Speed Limit 175" 50 "Speed Limit 180" 51 "Speed Limit 185" 52 "Speed Limit 190" 53 "Speed Limit 195" 54 "Speed Limit 200" ;
VAL_ 1501 Sig7567 0 "UnKnown" 1 "No Sign Detected" 2 "Begin of Passing Restriction US" 3 "End of Passing Restriction US" 4 "Begin of Passing Restriction Canada" 5 "End of Passing Restriction Canada" 6 "Speed Limit 5" 7 "Speed Limit 10" 8 "Speed Limit 15" 9 "Speed Limit 20" 10 "Speed Limit 25" 11 "Speed Limit 30" 12 "Speed Limit 35" 13 "Speed Limit 40" 14 "Speed Limit 45" 15 "Speed Limit 50" 16 "Speed Limit 55" 17 "Speed Limit 60" 18 "Speed Limit 65" 19 "Speed Limit 70" 20 "Speed Limit 75" 21 "Speed Limit 80" 22 "Speed Limit 85" 23 "Speed Limit 90" 24 "Speed Limit 95" 25 "Speed Limit 100" 26 "Speed Limit 105" 27 "Speed Limit 110" 28 "Speed Limit 115" 29 "Speed Limit 120" 30 "Speed Limit 125" 31 "Speed Limit 130" 32 "Speed Limit 135" 33 "Speed Limit 140" 34 "Speed Limit 145" 35 "Speed Limit 150" 36 "Speed Limit 155" 37 "Speed Limit 160" 38 "Speed Limit 165" 39 "Speed Limit 170" 40 "Speed Limit 175" 41 "Speed Limit 180" 42 "Speed Limit 185" 43 "Speed Limit 190" 44 "Speed Limit 195" 45 "Speed Limit 200" ;
VAL_ 1501 Sig7569 0 "UnKnown" 1 "No Sign Detected" 2 "Begin of Passing Restriction US" 3 "End of Passing Restriction US" 4 "Begin of Passing Restriction Canada" 5 "End of Passing Restriction Canada" 6 "Speed Limit 5" 7 "Speed Limit 10" 8 "Speed Limit 15" 9 "Speed Limit 20" 10 "Speed Limit 25" 11 "Speed Limit 30" 12 "Speed Limit 35" 13 "Speed Limit 40" 14 "Speed Limit 45" 15 "Speed Limit 50" 16 "Speed Limit 55" 17 "Speed Limit 60" 18 "Speed Limit 65" 19 "Speed Limit 70" 20 "Speed Limit 75" 21 "Speed Limit 80" 22 "Speed Limit 85" 23 "Speed Limit 90" 24 "Speed Limit 95" 25 "Speed Limit 100" 26 "Speed Limit 105" 27 "Speed Limit 110" 28 "Speed Limit 115" 29 "Speed Limit 120" 30 "Speed Limit 125" 31 "Speed Limit 130" 32 "Speed Limit 135" 33 "Speed Limit 140" 34 "Speed Limit 145" 35 "Speed Limit 150" 36 "Speed Limit 155" 37 "Speed Limit 160" 38 "Speed Limit 165" 39 "Speed Limit 170" 40 "Speed Limit 175" 41 "Speed Limit 180" 42 "Speed Limit 185" 43 "Speed Limit 190" 44 "Speed Limit 195" 45 "Speed Limit 200" ;
VAL_ 1501 Sig7558 0 "UnKnown" 1 "None" 2 "Supp Sign Generic" 3 "Rain" 4 "Snow" 5 "Snow Rain" 6 "Rain Cloud" 7 "Fog" 8 "Time" 9 "Wet Conditions" 10 "Trailer" 11 "Tractor Passable" 12 "Arrow Left" 13 "Arrow Right" 14 "Distance Arrow" 15 "School" ;
VAL_ 1501 Sig7556 0 "UnKnown" 1 "None" 2 "Supp Sign Generic" 3 "Rain" 4 "Snow" 5 "Snow Rain" 6 "Rain Cloud" 7 "Fog" 8 "Time" 9 "Wet Conditions" 10 "Trailer" 11 "Tractor Passable" 12 "Arrow Left" 13 "Arrow Right" 14 "Distance Arrow" 15 "School" ;
VAL_ 1501 Sig3474 0 "FALSE" 1 "TRUE" ;
VAL_ 1501 Sig3473 0 "FALSE" 1 "TRUE" ;
VAL_ 1501 Sig7568 0 "None" 1 "Supp Sign Generic" 2 "School" 3 "School When Flashing" 4 "End of Speed Limit" 5 "Where Workers Present" ;
VAL_ 1501 Sig7566 0 "None" 1 "Supp Sign Generic" 2 "School" 3 "School When Flashing" 4 "End of Speed Limit" 5 "Where Workers Present" ;
VAL_ 1501 Sig7711 0 "FALSE" 1 "TRUE" ;
VAL_ 1501 Sig7700 0 "FALSE" 1 "TRUE" ;
VAL_ 1501 Sig7564 0 "FALSE" 1 "TRUE" ;
VAL_ 1501 Sig7562 0 "FALSE" 1 "TRUE" ;
VAL_ 1501 Sig7561 0 "FALSE" 1 "TRUE" ;
VAL_ 1501 Sig7560 0 "FALSE" 1 "TRUE" ;
VAL_ 1501 Sig7553 0 "FALSE" 1 "TRUE" ;
VAL_ 1501 Sig3475 0 "FALSE" 1 "TRUE" ;
VAL_ 1501 Sig7712 0 "FALSE" 1 "TRUE" ;
VAL_ 1427 SBZALCAVisIndStatLt 0 "FLASHING" 1 "SOLID" 2 "OFF" ;
VAL_ 1428 SBZALCAVisIndStatRt 0 "FLASHING" 1 "SOLID" 2 "OFF" ;
VAL_ 1432 AutoHgBmActReq 0 "FALSE" 1 "TRUE" ;
VAL_ 706 LtFstAprchgVehObjDtd 0 "FALSE" 1 "TRUE" ;
VAL_ 1410 RrCrsTrfcAlrtLftIndCtrl 0 "ON" 1 "OFF" 2 "FLASH" ;
VAL_ 1410 RrCrsTrfcAlrtCstCrStVal 0 "SETTING_UNKNOWN" 1 "OFF" 2 "ALERT" 3 "ALERT and BRAKE" 4 "RESERVED_4" 5 "RESERVED_5" 6 "RESERVED_6" 7 "RESERVED_7" ;
VAL_ 1410 LnChgAlrtCstCrStVal 0 "SETTING_UNKNOWN" 1 "OFF" 2 "ON" 3 "RESERVED_3" 4 "RESERVED_4" 5 "RESERVED_5" 6 "RESERVED_6" 7 "RESERVED_7" ;
VAL_ 1444 LtSdVehObjDtd 0 "FALSE" 1 "TRUE" ;
VAL_ 1444 SBZALCAOvrllOplSts 0 "NORMAL OPERATION" 1 "NEEDS SERVICE" 2 "TEMPORARY UNAVAILABLE" ;
VAL_ 182 RCTBAD_BrkgReqd 0 "FALSE" 1 "TRUE" ;
VAL_ 182 RCTBAD_BrkgReqTyp 0 "None" 1 "Hold" ;
VAL_ 708 RtFstAprchgVehObjDtd 0 "FALSE" 1 "TRUE" ;
VAL_ 1412 RtSdVehObjDtd 0 "FALSE" 1 "TRUE" ;
VAL_ 1412 RrCrsTrfcAlrtRgIndCtrl 0 "ON" 1 "OFF" 2 "FLASH" ;
VAL_ 162 E44OG1_Hght1 0 "Unknown" 1 "Traversable" 2 "High Object" 3 "Low Object" ;
VAL_ 162 E44OG1_Cnfd1 0 "Highly Speculative" 1 "Speculative" 2 "Confident" 3 "Highly Confident" ;
VAL_ 162 E44OG1_Typ1 0 "NoObject" 1 "Straight_0Corner" 2 "Straight_1Corner" 3 "Straight_2Corners" 4 "Point" 5 "Curbstone" 6 "Blind Area" ;
VAL_ 164 E44OG2_Hght2 0 "Unknown" 1 "Traversable" 2 "High Object" 3 "Low Object" ;
VAL_ 164 E44OG2_Cnfd2 0 "Highly Speculative" 1 "Speculative" 2 "Confident" 3 "Highly Confident" ;
VAL_ 164 E44OG2_Typ2 0 "NoObject" 1 "Straight_0Corner" 2 "Straight_1Corner" 3 "Straight_2Corners" 4 "Point" 5 "Curbstone" 6 "Blind Area" ;
VAL_ 168 E44OG3_Hght3 0 "Unknown" 1 "Traversable" 2 "High Object" 3 "Low Object" ;
VAL_ 168 E44OG3_Cnfd3 0 "Highly Speculative" 1 "Speculative" 2 "Confident" 3 "Highly Confident" ;
VAL_ 168 E44OG3_Typ3 0 "NoObject" 1 "Straight_0Corner" 2 "Straight_1Corner" 3 "Straight_2Corners" 4 "Point" 5 "Curbstone" 6 "Blind Area" ;
VAL_ 2147745821 Sig4007 0 "FALSE" 1 "TRUE" ;
VAL_ 1421 LnFllwgFtrStat 0 "Off" 1 "Unavailable" 2 "Disabled" 3 "Enabled" 4 "Active" 5 "Cautionary" 6 "Override" 7 "Degraded" 8 "No Return" 9 "Ended" 10 "Non-Responsive Driver" ;
VAL_ 1027 PrkAsstCustSeltn 0 "Off" 1 "On" 2 "Failed" ;
VAL_ 1027 E44OprtlSts 0 "Unavailable" 1 "Available" 2 "Failed" ;
VAL_ 1027 PrkAsstONOFFCstCrStVal 0 "SETTING_UNKNOWN" 1 "OFF" 2 "ALERT" 3 "ALERT_BRAKE" 4 "RESERVED_4" 5 "RESERVED_5" 6 "RESERVED_6" 7 "RESERVED_7" ;
VAL_ 75 ElecPSOvrlyTrqDlvd_Inv 0 "FALSE" 1 "TRUE" ;
VAL_ 75 ElecPSTrqOvrlySts 0 "Unknown" 1 "Temporarily Inhibited" 2 "Inactive" 3 "Active" 4 "Temporarily Limited" 5 "Failed" ;
VAL_ 32 StrgEstdRckF_Inv 0 "FALSE" 1 "TRUE" ;
VAL_ 739 Sig7811 0 "FALSE" 1 "TRUE" ;
VAL_ 739 Sig7810 0 "FALSE" 1 "TRUE" ;
VAL_ 739 Sig7813 0 "FALSE" 1 "TRUE" ;
VAL_ 946 Sig0417 0 "NO INDICATION" 1 "FAILURE INDICATION" 2 "TOURIST MODE SETTING CHANGED" 3 "TOURIST MODE REMINDER" ;
VAL_ 946 Sig4160 0 "SETTING_UNKNOWN" 1 "LEFT_HAND_DRIVE" 2 "RIGHT_HAND_DRIVE" 3 "AUTOMATIC_WITH_GPS" 4 "RESERVED_4" 5 "RESERVED_5" 6 "RESERVED_6" 7 "RESERVED_7" ;
VAL_ 946 Sig0415 0 "SETTING_UNKNOWN" 1 "OFF" 2 "CORNER_AND_CURVE_LIGHTING" 3 "INTELLIGENT_LIGHT_DISTRIBUTION" 4 "INTELLIGENT_LIGHT_DISTRIBUTION_GPS_ASSISTANCE" 5 "RESERVED_5" 6 "RESERVED_6" 7 "RESERVED_7" ;
VAL_ 946 Sig0109 0 "FALSE" 1 "TRUE" ;
VAL_ 946 AFLServHdlmpsIndOn 0 "FALSE" 1 "TRUE" ;
VAL_ 946 Sig0108 0 "FALSE" 1 "TRUE" ;
VAL_ 946 Sig0107 0 "FALSE" 1 "TRUE" ;
VAL_ 946 Sig0106 0 "FALSE" 1 "TRUE" ;
VAL_ 946 Sig0105 0 "FALSE" 1 "TRUE" ;
VAL_ 946 Sig0104 0 "FALSE" 1 "TRUE" ;
VAL_ 946 Sig0103 0 "FALSE" 1 "TRUE" ;
VAL_ 946 Sig0413 0 "FALSE" 1 "TRUE" ;
VAL_ 946 Sig0412 0 "FALSE" 1 "TRUE" ;
VAL_ 946 Sig0411 0 "FALSE" 1 "TRUE" ;
VAL_ 946 Sig0410 0 "FALSE" 1 "TRUE" ;
VAL_ 946 Sig0409 0 "FALSE" 1 "TRUE" ;
VAL_ 946 Sig0408 0 "FALSE" 1 "TRUE" ;
VAL_ 946 Sig0407 0 "FALSE" 1 "TRUE" ;
VAL_ 946 Sig0110 0 "FALSE" 1 "TRUE" ;
VAL_ 946 Sig4157 0 "FALSE" 1 "TRUE" ;
VAL_ 946 Sig4156 0 "FALSE" 1 "TRUE" ;
VAL_ 946 Sig4155 0 "FALSE" 1 "TRUE" ;
VAL_ 946 Sig4154 0 "FALSE" 1 "TRUE" ;
VAL_ 946 Sig4153 0 "FALSE" 1 "TRUE" ;
VAL_ 946 Sig4152 0 "FALSE" 1 "TRUE" ;
VAL_ 946 AdvdFrtLgtSysHiBmIndOnReqd 0 "FALSE" 1 "TRUE" ;
VAL_ 946 Sig0416 0 "FALSE" 1 "TRUE" ;
VAL_ 946 Sig4161 0 "FALSE" 1 "TRUE" ;
VAL_ 946 Sig4158 0 "FALSE" 1 "TRUE" ;
VAL_ 701 AE44CtrlTctlFdbk 0 "FALSE" 1 "TRUE" ;
VAL_ 1406 AE44CR_SptFndChmEvntStat 0 "NO_ACTION" 1 "ACTIVE" 2 "CANCEL_CHIME" ;
VAL_ 1406 AE44CR_FaildChmEvntStat 0 "NO_ACTION" 1 "ACTIVE" 2 "CANCEL_CHIME" ;
VAL_ 1406 AE44CR_CncldChmEvntStat 0 "NO_ACTION" 1 "ACTIVE" 2 "CANCEL_CHIME" ;
VAL_ 1406 AE44CR_CmpltChmEvntStat 0 "NO_ACTION" 1 "ACTIVE" 2 "CANCEL_CHIME" ;
VAL_ 1406 AE44CR_StopChmEvntStat 0 "NO_ACTION" 1 "ACTIVE" 2 "CANCEL_CHIME" ;
VAL_ 1422 AE44WI_FcsReq 0 "NO_REQUEST" 1 "FOCUS_REQUEST_IPC" 2 "FOCUS_REQUEST_CSM" ;
VAL_ 1422 AE44WI_AutoStrgIconReq 0 "NO_ICON" 1 "ACTIVE" 2 "DEACTIVATED" ;
VAL_ 1422 AE44WI_WrnIndReq 0 "OFF" 1 "SEARCHING_PARALLEL_RIGHT" 2 "SEARCHING_PARALLEL_LEFT" 3 "SEARCHING_CROSS_RIGHT" 4 "SEARCHING_CROSS_LEFT" 5 "SPOT_FOUND" 6 "SPOT_FOUND_PARALLEL_LEFT" 7 "SPOT_FOUND_CROSS_LEFT" 8 "SPOT_FOUND_PARALLEL_RIGHT" 9 "SPOT_FOUND_CROSS_RIGHT" 10 "MOVE_AHEAD" 11 "MOVE_AHEAD_PARALLEL_LEFT" 12 "MOVE_AHEAD_CROSS_LEFT" 13 "MOVE_AHEAD_PARALLEL_RIGHT" 14 "MOVE_AHEAD_CROSS_RIGHT" 15 "STOP_AND_R_PARALLEL_LEFT" 16 "STOP_AND_R_CROSS_BACK_LEFT" 17 "STOP_AND_R_CROSS_FRONT_LEFT" 18 "STOP_AND_R_PARALLEL_RIGHT" 19 "STOP_AND_R_CROSS_BACK_RIGHT" 20 "STOP_AND_R_CROSS_FRONT_RIGHT" 21 "SEARCH_SPEED_WARNING" 22 "SEARCH_DEACTIVATED" 23 "EXIT_PARK_TO_LEFT" 24 "EXIT_PARK_TO_RIGHT" 25 "SELECT_DRIVE_GEAR" 26 "AUTO_STEERING_ACTIVE" 27 "AUTO_PARKING_ACTIVE" 28 "DRIVE_BACKWARD" 29 "BACKWARD_MOVE" 30 "DRIVE_FORWARD" 31 "FORWARD_MOVE" 32 "STOP" 33 "SHIFTING" 34 "POSITION_REACHED" 35 "TAKE_CONTROL" 36 "PARKING_COMPLETE" 37 "EXIT_PARK_COMPLETE" 38 "DEACTIVATED" 39 "CANCELED_GENERAL" 40 "CANCELED_MOVES" 41 "CANCELED_SPEED" 42 "CANCELED_INTERFERENCE" 43 "CANCELED_EXIT_PARK" 44 "STOPPING" 45 "AUTO_PARKING_COMPLETE" 46 "RELEASE_BRAKE" 47 "IN_VEHICLE_OR_REMOTE" 48 "REMOTE_STAY_ALERT" 49 "REMOTE_CONNECTING" 50 "REMOTE_CANNOT_CONNECT" 51 "REMOTE_NO_DEVICE" 52 "REMOTE_SHIFT_TO_PARK" 53 "REMOTE_RETRY" 54 "REMOTE_CANCELED_RANGE" 55 "REMOTE_CANCELED_SUPERVISION" 56 "REMOTE_CANCELED_CONNECTION" 57 "REMOTE_PAUSED_RANGE" 58 "REMOTE_PAUSED_SUPERVISION" 59 "REMOTE_PAUSED_CONNECTION" ;
VAL_ 1422 AE44LftSftBtnRqst 0 "HIDDEN" 1 "DISABLED" 2 "ENABLED" 3 "HIGHLIGHTED" ;
VAL_ 1422 AE44ExtPrkSftBtnRqst 0 "HIDDEN" 1 "DISABLED" 2 "ENABLED" 3 "HIGHLIGHTED" ;
VAL_ 1422 AE44CrssFrntInSftBtnRqst 0 "HIDDEN" 1 "DISABLED" 2 "ENABLED" 3 "HIGHLIGHTED" ;
VAL_ 1422 AE44CrssBckInSftBtnRqst 0 "HIDDEN" 1 "DISABLED" 2 "ENABLED" 3 "HIGHLIGHTED" ;
VAL_ 1422 AE44VMR_SloDnIndOn 0 "FALSE" 1 "TRUE" ;
VAL_ 1422 AE44VMR_NAvalIndOn 0 "FALSE" 1 "TRUE" ;
VAL_ 1422 AE44SrchSftBtnRqst 0 "HIDDEN" 1 "DISABLED" 2 "ENABLED" 3 "HIGHLIGHTED" ;
VAL_ 1422 AE44RghtSftBtnRqst 0 "HIDDEN" 1 "DISABLED" 2 "ENABLED" 3 "HIGHLIGHTED" ;
VAL_ 1422 AE44PrllPrkSftBtnRqst 0 "HIDDEN" 1 "DISABLED" 2 "ENABLED" 3 "HIGHLIGHTED" ;
VAL_ 206 HVBI_BatPackPrcdVltg_Inv 0 "FALSE" 1 "TRUE" ;
VAL_ 206 HVBI_BatPackPrcdVltg_DuD 0 "FALSE" 1 "TRUE" ;
VAL_ 206 HiVltgBatPrcdCurr_DuD 0 "FALSE" 1 "TRUE" ;
VAL_ 206 HiVltgBatPrcdCurr_Inv 0 "FALSE" 1 "TRUE" ;
VAL_ 722 HVBSOC_BatSOC_Inv 0 "FALSE" 1 "TRUE" ;
VAL_ 1526 HiVltgBatMaxTemp_Inv 0 "FALSE" 1 "TRUE" ;
VAL_ 1526 HiVltgBatMaxTemp_DuD 0 "FALSE" 1 "TRUE" ;
VAL_ 1526 HiVltgBatMinTemp_Inv 0 "FALSE" 1 "TRUE" ;
VAL_ 1526 HiVltgBatMinTemp_DuD 0 "FALSE" 1 "TRUE" ;
VAL_ 721 Sig2661 0 "FALSE" 1 "TRUE" ;
VAL_ 1527 Sig4453 0 "FALSE" 1 "TRUE" ;
VAL_ 1527 Sig4449 0 "FALSE" 1 "TRUE" ;
VAL_ 112 Sig3606 0 "Indeterminate" 1 "False" 2 "True" ;
VAL_ 112 Sig3546 0 "Indeterminate" 1 "False" 2 "True" ;
VAL_ 112 Sig3545 0 "Indeterminate" 1 "False" 2 "True" ;
VAL_ 1436 Sig0521 0 "P0_Powertrain Codes SAE Controlled" 1 "P1_Powertrain Codes MFG Controlled" 2 "P2_Powertrain Codes Reserved" 3 "P3_Powertrain Codes Reserved" 4 "C0_Chassis Codes SAE Controlled" 5 "C1_Chassis Codes MFG Controlled" 6 "C2_Chassis Codes Reserved" 7 "C3_Chassis Codes Reserved" 8 "B0_Body Codes SAE Controlled" 9 "B1_Body Codes MFG Controlled" 10 "B2_Body Codes Reserved" 11 "B3_Body Codes Reserved" 12 "U0_Network Codes SAE Controlled" 13 "U1_Network Codes MFG Controlled" 14 "U2_Network Codes Reserved" 15 "U3_Network Codes Reserved" ;
VAL_ 1436 Sig0526 0 "FALSE" 1 "TRUE" ;
VAL_ 1528 Sig4451 0 "FALSE" 1 "TRUE" ;
VAL_ 1528 Sig4450 0 "FALSE" 1 "TRUE" ;
VAL_ 928 Sig4919 0 "NONE" 1 "SETPOINT1" 2 "SETPOINT2" 3 "SETPOINT3" 4 "SETPOINT4" ;
VAL_ 928 HiVltgBatOutOfEngyIndReq 0 "No Action" 1 "Charge Soon" 2 "Charge Now" 3 "Out of Energy" 4 "Start Engine" ;
VAL_ 723 PrplDispEngTrq_Inv 0 "FALSE" 1 "TRUE" ;
VAL_ 723 PrplDispEngTrq_DuD 0 "FALSE" 1 "TRUE" ;
VAL_ 723 HiVltgThrmlTotPwrUsd_Inv 0 "FALSE" 1 "TRUE" ;
VAL_ 723 ChrgSysShfToPrkReqd 0 "FALSE" 1 "TRUE" ;
VAL_ 723 JmpStrtEnbld 0 "FALSE" 1 "TRUE" ;
VAL_ 723 HiVltgBatGridCnctd 0 "FALSE" 1 "TRUE" ;
VAL_ 723 CoolFanFrtEndOutEnbl 0 "FALSE" 1 "TRUE" ;
VAL_ 1437 HiVltgBatCoolTempSnsrVal_Inv 0 "FALSE" 1 "TRUE" ;
VAL_ 1437 ChrgSysAudblIndReq 0 "No Action" 1 "Off" 2 "Charge Cord Sound 1" 3 "Charge Cord Sound 2" 4 "Charge Cord Sound 3" 5 "Charge Cord Sound 4" 6 "Charge Cord Sound 5" 7 "Theft" ;
VAL_ 1437 PwrElecCoolPmpSpdActlDgFltActv 0 "FALSE" 1 "TRUE" ;
VAL_ 1437 HiVltgBatThrmlMode 0 "Not Active" 1 "Active Cool" 2 "Active Heat" ;
VAL_ 725 GPSV_PPSCalcdSpd_Inv 0 "FALSE" 1 "TRUE" ;
VAL_ 725 GPSV_PPSElvtn_Inv 0 "FALSE" 1 "TRUE" ;
VAL_ 725 GPSQM_PPSPstnDilutnPrcsn_Inv 0 "FALSE" 1 "TRUE" ;
VAL_ 725 GPSV_PPSHdg_Inv 0 "FALSE" 1 "TRUE" ;
VAL_ 725 GPSQM_PPSAbsVelErrEst_Inv 0 "FALSE" 1 "TRUE" ;
VAL_ 725 GPST_PPSTmOfDy_Inv 0 "FALSE" 1 "TRUE" ;
VAL_ 720 JmpStrtReqd 0 "FALSE" 1 "TRUE" ;
VAL_ 930 HillDscntCtlModeSwActv 0 "FALSE" 1 "TRUE" ;
VAL_ 930 HillDscntCtlModeSwActv_Inv 0 "FALSE" 1 "TRUE" ;
VAL_ 726 WndPstnStsRF 0 "Denormalized" 1 "Fully Closed" 2 "Less Than Position A" 3 "Position A" 4 "Greater Than A but less than Position C" 5 "Position C" 6 "Greater than Position C but less than Fully open" 7 "Fully Open" ;
VAL_ 726 WndPstnStsLF 0 "Denormalized" 1 "Fully Closed" 2 "Less Than Position A" 3 "Position A" 4 "Greater Than A but less than Position C" 5 "Position C" 6 "Greater than Position C but less than Fully open" 7 "Fully Open" ;
VAL_ 726 PrkLmpsAct 0 "FALSE" 1 "TRUE" ;
VAL_ 726 FgLmpFrtRtCmd 0 "FALSE" 1 "TRUE" ;
VAL_ 726 FgLmpFrtLftCmd 0 "FALSE" 1 "TRUE" ;
VAL_ 726 LogisticModeStatus 0 "Off" 1 "Plant" 2 "Transport Mode" 3 "Storage Mode" ;
VAL_ 726 AutoBmSlctAllwd 0 "FALSE" 1 "TRUE" ;
VAL_ 726 AutoBmSlctAllwd_Inv 0 "FALSE" 1 "TRUE" ;
VAL_ 726 GPSQM_PPS2DAbsPstnErrEst_Inv 0 "FALSE" 1 "TRUE" ;
VAL_ 726 ValetModeActive 0 "FALSE" 1 "TRUE" ;
VAL_ 726 GPSQM_PPS3DAbsPstnErrEst_Inv 0 "FALSE" 1 "TRUE" ;
VAL_ 944 EE46etptPrty 0 "Low Priority" 1 "Medium Priority" 2 "High Priority" ;
VAL_ 1407 FrntPCMRspTypCstChgSetReq 0 "NO_ACTION" 1 "OFF" 2 "ALERT" 3 "ALERT_AND_BRAKE" 4 "ALERT_AND_BRAKE_AND_STEER" 5 "RESERVED_5" 6 "RESERVED_6" 7 "RESERVED_7" ;
VAL_ 1407 Sig0414 0 "NO_ACTION" 1 "OFF" 2 "CORNER_AND_CURVE_LIGHTING" 3 "INTELLIGENT_LIGHT_DISTRIBUTION" 4 "INTELLIGENT_LIGHT_DISTRIBUTION_GPS_ASSISTANCE" 5 "RESERVED_5" 6 "RESERVED_6" 7 "RESERVED_7" ;
VAL_ 1407 Sig3505 0 "NO_ACTION" 1 "AUTOMATIC_HIGH_BEAM" 2 "GLARE_FREE_HIGH_BEAM" 3 "RESERVED_3" 4 "RESERVED_4" 5 "RESERVED_5" 6 "RESERVED_6" 7 "RESERVED_7" ;
VAL_ 1407 FrwdImpMtgnOpSlctCstChgSetReq 0 "NO_ACTION" 1 "OFF" 2 "ALERT" 3 "ALERT_BRAKE" 4 "ALERT_BRAKE_STEER" 5 "RESERVED_5" 6 "RESERVED_6" 7 "RESERVED_7" ;
VAL_ 1407 Sig7708 0 "NO_ACTION" 1 "OFF" 2 "ALERT" 3 "RESERVED_3" 4 "RESERVED_4" 5 "RESERVED_5" 6 "RESERVED_6" 7 "RESERVED_7" ;
VAL_ 1407 Sig4159 0 "NO_ACTION" 1 "LEFT_HAND_DRIVE" 2 "RIGHT_HAND_DRIVE" 3 "AUTOMATIC_WITH_GPS" 4 "RESERVED_4" 5 "RESERVED_5" 6 "RESERVED_6" 7 "RESERVED_7" ;
VAL_ 1407 GoNotfrCstChgSetReq 0 "NO_ACTION" 1 "OFF" 2 "ON" 3 "RESERVED_3" 4 "RESERVED_4" 5 "RESERVED_5" 6 "RESERVED_6" 7 "RESERVED_7" ;
VAL_ 1407 Sig2570 0 "No Action" 1 "Off" 2 "On" ;
VAL_ 1407 DispMeasSysExtnd 0 "US" 1 "IMPERIAL" 2 "Metric KM/L" 3 "Metric L/100KM" ;
VAL_ 1407 CoDrvDrAjrStat 0 "FALSE" 1 "TRUE" ;
VAL_ 1407 CoDrvDrAjrStat_Inv 0 "FALSE" 1 "TRUE" ;
VAL_ 1407 AutoVehHldSwActv 0 "FALSE" 1 "TRUE" ;
VAL_ 1407 AutoVehHldSwActv_Inv 0 "FALSE" 1 "TRUE" ;
VAL_ 1407 LRDrAjrStat_Inv 0 "FALSE" 1 "TRUE" ;
VAL_ 1407 LDWCtrlIndStat 0 "OFF" 1 "ON" 2 "FAULT" 3 "UNKNOWN" ;
VAL_ 1407 HtdStrgWhlInd 0 "Off" 1 "Low" 2 "Med" 3 "High" ;
VAL_ 1407 HtdStrgWhlCmd 0 "Off" 1 "Low" 2 "Med" 3 "High" ;
VAL_ 1407 AE44CrssBckInSftBtnStat 0 "NOT_PRESSED" 1 "PRESSED" ;
VAL_ 1407 RRDrAjrStat 0 "FALSE" 1 "TRUE" ;
VAL_ 1407 RRDrAjrStat_Inv 0 "FALSE" 1 "TRUE" ;
VAL_ 1407 Sig4423 0 "No Action" 1 "Increase" 2 "Decrease" 3 "Set to default" ;
VAL_ 1407 Sig4421 0 "No Action" 1 "Increase" 2 "Decrease" 3 "Set to default" ;
VAL_ 1407 LRDrAjrStat 0 "FALSE" 1 "TRUE" ;
VAL_ 1407 AE44RghtSftBtnStatIPC 0 "NOT_PRESSED" 1 "PRESSED" ;
VAL_ 1407 AE44RghtSftBtnStat 0 "NOT_PRESSED" 1 "PRESSED" ;
VAL_ 1407 AE44PrllPrkSftBtnStat 0 "NOT_PRESSED" 1 "PRESSED" ;
VAL_ 1407 AE44LftSftBtnStatIPC 0 "NOT_PRESSED" 1 "PRESSED" ;
VAL_ 1407 AE44LftSftBtnStat 0 "NOT_PRESSED" 1 "PRESSED" ;
VAL_ 1407 AE44FcStatIPC 0 "NO_FOCUS" 1 "FOCUS" ;
VAL_ 1407 AE44FcStatCSM 0 "NO_FOCUS" 1 "FOCUS" ;
VAL_ 1407 AE44ExtPrkSftBtnStat 0 "NOT_PRESSED" 1 "PRESSED" ;
VAL_ 1407 DM5Denied 0 "FALSE" 1 "TRUE" ;
VAL_ 1407 DM4Denied 0 "FALSE" 1 "TRUE" ;
VAL_ 1407 DM3Denied 0 "FALSE" 1 "TRUE" ;
VAL_ 1407 DM2Denied 0 "FALSE" 1 "TRUE" ;
VAL_ 1407 DM1Denied 0 "FALSE" 1 "TRUE" ;
VAL_ 1407 CrshEvntEnbld 0 "FALSE" 1 "TRUE" ;
VAL_ 1407 ClsnEvntDatRcrdgTrgrd 0 "FALSE" 1 "TRUE" ;
VAL_ 1407 AE44SrchSftBtnStat 0 "NOT_PRESSED" 1 "PRESSED" ;
VAL_ 1407 Sig3484 0 "FALSE" 1 "TRUE" ;
VAL_ 1407 FlToPsSwAtv 0 "FALSE" 1 "TRUE" ;
VAL_ 1407 DispMeasSys 0 "Metric" 1 "English" ;
VAL_ 1407 DM8Denied 0 "FALSE" 1 "TRUE" ;
VAL_ 1407 DM7Denied 0 "FALSE" 1 "TRUE" ;
VAL_ 1407 DM6Denied 0 "FALSE" 1 "TRUE" ;
VAL_ 1407 RstrCstDfltReq 0 "FALSE" 1 "TRUE" ;
VAL_ 1407 LowBmAct 0 "FALSE" 1 "TRUE" ;
VAL_ 1407 LDWCSwCktShrtGndDiagFltActv 0 "FALSE" 1 "TRUE" ;
VAL_ 1407 LDWCSwCktShrtBatOpnDiagFltActv 0 "FALSE" 1 "TRUE" ;
VAL_ 1407 HtdWhlTempAmbtAirEstdOrgn 0 "Inside" 1 "Outside" ;
VAL_ 1407 HtdStrgWhlEnbl 0 "FALSE" 1 "TRUE" ;
VAL_ 1407 HtdStrgWhlCtlSrc 0 "Local_Switch_Control" 1 "Remote_Switch_Control" ;
VAL_ 1407 HighBmAct 0 "FALSE" 1 "TRUE" ;
VAL_ 1407 SBZAlrtCstCrStVal 0 "SETTING_UNKNOWN" 1 "OFF" 2 "ON" 3 "RESERVED_3" 4 "RESERVED_4" 5 "RESERVED_5" 6 "RESERVED_6" 7 "RESERVED_7" ;
VAL_ 1407 WlcmLgtsActv 0 "FALSE" 1 "TRUE" ;
VAL_ 1407 Sig7578 0 "12 Hour Mode" 1 "24 Hour Mode" ;
VAL_ 1407 TargaTopAjrStat 0 "FALSE" 1 "TRUE" ;
VAL_ 1407 Sig7570 0 "TSM Warning Off" 1 "TSM Warning On" ;
VAL_ 1407 Sig7565 0 "FALSE" 1 "TRUE" ;
VAL_ 1407 Sig7563 0 "FALSE" 1 "TRUE" ;
VAL_ 1407 Sig7555 0 "FALSE" 1 "TRUE" ;
VAL_ 1407 AE44LtSftBtnSts 0 "Not Pressed" 1 "Pressed" ;
VAL_ 1407 AE44ExtPrkSftBtnSts 0 "Not Pressed" 1 "Pressed" ;
VAL_ 1407 AE44CrssFrntInSftBtnStat 0 "Not Pressed" 1 "Pressed" ;
VAL_ 1407 AE44CrsBkInSftBtnSts 0 "Not Pressed" 1 "Pressed" ;
VAL_ 1407 Sig0604 0 "Unknown" 1 "Healthy" 2 "Faulted" ;
VAL_ 1407 SuprRmtPrkDctvSoftBtnSts 0 "Not Pressed" 1 "Pressed" ;
VAL_ 1407 AE44SrchingSftBtnSts 0 "Not Pressed" 1 "Pressed" ;
VAL_ 1407 AE44RtSftBtnStsIPC 0 "Not Pressed" 1 "Pressed" ;
VAL_ 1407 AE44RtSftBtnSts 0 "Not Pressed" 1 "Pressed" ;
VAL_ 1407 AE44ParallelPrkSftBtnSts 0 "Not Pressed" 1 "Pressed" ;
VAL_ 1407 AE44LtSftBtnStsIPC 0 "Not Pressed" 1 "Pressed" ;
VAL_ 1407 SRPUnableCnctExtSftBtnSts 0 "Not Pressed" 1 "Pressed" ;
VAL_ 1407 SRPUnableCnctTryAgnSftBtnSts 0 "Not Pressed" 1 "Pressed" ;
VAL_ 1407 SRPSptSeltnRmtSftBtnSts 0 "Not Pressed" 1 "Pressed" ;
VAL_ 1407 SRPSptSeltnKeepLkSftBtnSts 0 "Not Pressed" 1 "Pressed" ;
VAL_ 1407 SRPSptSeltnAcceptSftBtnSts 0 "Not Pressed" 1 "Pressed" ;
VAL_ 1424 Sig0076 0 "UNKNOWN" 1 "<= 5 KM/H [MPH]" 2 "7 KM/H [MPH]" 3 "10 KM/H [MPH]" 4 "15 KM/H [MPH]" 5 "20 KM/H [MPH]" 6 "25 KM/H [MPH]" 7 "30 KM/H [MPH]" 8 "35 KM/H [MPH]" 9 "40 KM/H [MPH]" 10 "45 KM/H [MPH]" 11 "50 KM/H [MPH]" 12 "55 KM/H [MPH]" 13 "60 KM/H" 14 "MPH]65 KM/H [MPH]" 15 "70 KM/H [MPH]" 16 "75 KM/H [MPH]" 17 "80 KM/H [MPH]" 18 "85 KM/H [MPH]" 19 "90 KM/H [MPH]" 20 "95 KM/H [MPH]" 21 "100 KM/H [MPH]" 22 "105 KM/H [MPH]" 23 "110 KM/H [MPH]" 24 "115 KM/H [MPH]" 25 "120 KM/H[MPH]" 26 "130 KM/H [MPH]" 27 "140 KM/H [MPH]" 28 "150 KM/H [MPH]" 29 "160 KM/H [MPH]" 30 "UNLIMITED" 31 "NOT AVAILABLE" ;
VAL_ 1424 Sig0074 0 "AD" 1 "AT" 2 "BE" 3 "CZ" 4 "DK" 5 "EE" 6 "FR" 7 "DE" 8 "GR" 9 "HU" 10 "IE" 11 "IT" 12 "BY" 13 "BG" 14 "CY" 15 "MT" 16 "HR" 17 "TR" 18 "RS" 19 "ME" 20 "LV" 21 "LT" 22 "LU" 23 "NL" 24 "NO" 25 "PL" 26 "PT" 27 "UK" 28 "SK" 29 "SI" 30 "ES" 31 "SE" 32 "CH" 33 "RO" 34 "RU" 35 "UA" 36 "BA" 37 "AL" 38 "MD" 39 "IS" 40 "MK" 41 "US" 42 "ZA" 43 "AU" 44 "NZ" 45 "KR" 46 "CN" ;
VAL_ 1424 InfoSysStat 0 "Sleep" 1 "AnimationInit" 2 "HMI_Init" 3 "HMI_Inactive" 4 "Start" 5 "Run" 6 "Propulsion" 7 "Accessory" 8 "LocalInfotainment" 9 "LocalPhone" 10 "LocalValet" 11 "LocalEject" 12 "ValetMode" 13 "TheftLocked" 14 "NoCalibration" 15 "NoVIN" 16 "RemoteReflashProgramming" 17 "OffMode" 18 "VirtualSwitchDisplay" 19 "NoInVehicleInfotainment" ;
VAL_ 1424 Sig0077 0 "NO PASSING RESTRICTIONS" 1 "GENERAL NO OVERTAKE" 2 "FLUCTUATING (E.G. LED SIGNS)" 3 "CONDITIONAL PASSENGER CAR WITH TRAILER" 4 "CONDITIONAL TRACTORS ARE ALLOWED TO OVERTAKE" 5 "CONDITIONAL WHEN WET" 6 "CONDITIONAL WHEN SNOW" 7 "UNKNOWN CONDITION" ;
VAL_ 1424 CTGI2P_CnvtTopStsAuth_Inv 0 "FALSE" 1 "TRUE" ;
VAL_ 1424 CTGI2P_CnvtTopStsAuth_DuD 0 "FALSE" 1 "TRUE" ;
VAL_ 1424 CTGI2P_CnvtTopStsAuth 0 "Indeterminate" 1 "Fully Closed" 2 "Fully Open" 3 "Closing" 4 "Opening" 5 "Halted" ;
VAL_ 1424 TDAP_DrvrIdfrAuth 0 "Driver 1" 1 "Driver 2" 2 "Driver 3" 3 "Driver 4" 4 "Driver 5" 5 "Driver 6" 6 "Driver 7" 7 "Unknown" ;
VAL_ 1424 Sig0075 0 "LANE DEPENDENT" 1 "ONLY BY FOG" 2 "ONLY BY NIGHT" 3 "ONLY BY DAY" 4 "BY TIME OF DAY" 5 "ONLY BY RAIN" 6 "ONLY BY SNOW" 7 "UNKNOWN" ;
VAL_ 1424 Sig0073 0 "ROAD IS NOT CONTROLLED ACCESS ROAD" 1 "ROAD IS CONTROLLED ACCESS ROAD" ;
VAL_ 1424 Sig0072 0 "NOT VALID" 1 "VALID" ;
VAL_ 1424 TrnSwAct 0 "NO_ACTIVATION" 1 "LEFT" 2 "RIGHT" ;
VAL_ 1424 FrtStrgeCmptAjr 0 "FALSE" 1 "TRUE" ;
VAL_ 1424 FrtStrgeCmptAjr_Inv 0 "FALSE" 1 "TRUE" ;
VAL_ 1424 AE44SftBtnSeltdStatRw 0 "Not_Pressed" 1 "Pressed" 2 "Unknown" 3 "Failed" ;
VAL_ 1424 PrkAsstTrHtchPsntCstChgSetReq 0 "NO_ACTION" 1 "OFF_NOT_ATTACHED" 2 "ON_ATTACHED" 3 "RESERVED_3" 4 "RESERVED_4" 5 "RESERVED_5" 6 "RESERVED_6" 7 "RESERVED_7" ;
VAL_ 1424 PrkAsstOnOffCstChgSetReq 0 "No_Action" 1 "Off" 2 "Alert" 3 "Alert_Brake" ;
VAL_ 1424 SuprRmtPrkFcsStsVCU 0 "No Focus" 1 "Focus" ;
VAL_ 1441 RPSU_Mth 0 "Unknown" 1 "January" 2 "February" 3 "March" 4 "April" 5 "May" 6 "June" 7 "July" 8 "August" 9 "September" 10 "October" 11 "November" 12 "December" ;
VAL_ 1441 RPSU_Sts 0 "Unknown" 1 "Inactive" 2 "Scheduled" ;
VAL_ 1441 ONPC_DprtrDyOfWkReq 0 "Unknown" 1 "Sunday" 2 "Monday" 3 "Tuesday" 4 "Wednesday" 5 "Thursday" 6 "Friday" 7 "Saturday" ;
VAL_ 1441 ONPC_Req 0 "No Action" 1 "Charge Now" 2 "Charge Later" ;
VAL_ 1441 LnchCtlEngRPMReq 0 "No Action" 1 "800" 2 "900" 3 "1000" 4 "1100" 5 "1200" 6 "1300" 7 "1400" 8 "1500" 9 "1600" 10 "1700" 11 "1800" 12 "1900" 13 "2000" 14 "2100" 15 "2200" 16 "2300" 17 "2400" 18 "2500" 19 "2600" 20 "2700" 21 "2800" 22 "2900" 23 "3000" 24 "3100" 25 "3200" 26 "3300" 27 "3400" 28 "3500" 29 "3600" 30 "3700" 31 "3800" 32 "3900" 33 "4000" 34 "FlexibleRPM 1" 35 "FlexibleRPM 2" 36 "FlexibleRPM 3" 37 "FlexibleRPM 4" 38 "FlexibleRPM 5" ;
VAL_ 1441 LBCCDRR_PstnNumReq 0 "No Action" 1 "Position Number 1" 2 "Position Number 2" 3 "Position Number 3" 4 "Position Number 4" ;
VAL_ 1441 LBCCDRR_ClrStrdPstnReq 0 "No Action" 1 "Request to Clear Position" 2 "Confirmation to Clear Position" ;
VAL_ 1441 LnchCtlWhlSlReq 0 "No Action" 1 "Five Percent" 2 "Five And A Half Percent" 3 "Six Percent" 4 "Six And A Half Percent" 5 "Seven Percent" 6 "Seven And A Half Percent" 7 "Eight Percent" 8 "Eight And A Half Percent" 9 "Nine Percent" 10 "Nine And A Half Percent" 11 "Ten Percent" 12 "Ten And A Half Percent" 13 "Eleven Percent" 14 "Eleven And a Half Percent" 15 "Twelve Percent" 16 "Twelve And A Half Percent" 17 "Thirteen Percent" 18 "Thirteen And A Half Percent" 19 "Fourteen Percent" 20 "Fourteen And A Half Percent" 21 "Fifteen Percent" ;
VAL_ 1441 Sig4819 0 "No Action" 1 "RPM 1100" 2 "RPM 1200" 3 "RPM 1300" 4 "RPM 1400" 5 "RPM 1500" 6 "RPM 1600" 7 "RPM 1700" 8 "RPM 1800" 9 "RPM 1900" 10 "RPM 2000" 11 "RPM 2100" 12 "RPM 2200" 13 "RPM 2300" 14 "RPM 2400" 15 "RPM 2500" ;
VAL_ 1441 Sig4614 0 "No Action" 1 "Min 10" 2 "Min 30" 3 "Min 90" 4 "Min 120" 5 "Min 150" 6 "Min 180" 7 "Min 210" 8 "Min 240" 9 "Min 270" 10 "Min 200" 11 "Min 330" 12 "Min 360" 13 "Min 390" 14 "Min 420" 15 "Min 450" ;
VAL_ 1441 AutoLnChgCstChgSetReq 0 "No Action" 1 "Off" 2 "On" 3 "LCOD" 4 "LCOD and ALC" ;
VAL_ 1441 Sig4842 0 "No Action" 1 "RPM 1700" 2 "RPM 1800" 3 "RPM 1900" 4 "RPM 2000" 5 "RPM 2100" 6 "RPM 2200" 7 "RPM 2300" 8 "RPM 2400" 9 "RPM 2500" 10 "RPM 2600" 11 "RPM 2700" 12 "RPM 2800" 13 "RPM 2900" 14 "RPM 3000" 15 "RPM 3100" ;
VAL_ 1441 Sig4867 0 "No Action" 1 "RPM 900" 2 "RPM 1000" 3 "RPM 1100" 4 "RPM 1200" 5 "RPM 1300" 6 "RPM 1400" 7 "RPM 1500" ;
VAL_ 1441 LocBsdChrgPstnMdfnReq 0 "No Action" 1 "Store Position 1" 2 "Store Position 2" 3 "Store Position 3" 4 "Store Position 4" ;
VAL_ 1441 BrkPadLifeSysDrvrReq 0 "No Action" 1 "Disable" 2 "Enable" 3 "Reset Front" 4 "Reset Rear" ;
VAL_ 1441 PrkAsstStat 0 "OFF" 1 "STANDBY" 2 "DISABLED" 3 "FAILED" 4 "FRONT_REAR_ACTIVE" 5 "REAR_ACTIVE" 6 "FRONT_ACTIVE" 7 "UNKNOWN" ;
VAL_ 1441 Sig4889 0 "No Action" 1 "RPM 5" 2 "RPM 10" 3 "RPM 25" 4 "RPM 50" 5 "RPM 100" 6 "RPM 250" 7 "RPM 500" ;
VAL_ 1441 ChrgDatReq 0 "No Action" 1 "Wakeup Init All" 2 "Reinit All" 3 "Reinit Partial" ;
VAL_ 1441 ChrgCordThftAlrtCstSetReq 0 "No Action" 1 "Off" 2 "On" ;
VAL_ 1441 LnchCtlModeReq 0 "No Action" 1 "Automatic" 2 "Custom" 3 "Line Lock" ;
VAL_ 1441 HillDscntCtlCurrStatReq 0 "No Action" 1 "Disable" 2 "Enable" ;
VAL_ 1441 ChrgSysAudblIndCstSetReq 0 "No Action" 1 "Off" 2 "On" ;
VAL_ 1441 ChrgPwrLossAlrtCstSetReq 0 "No Action" 1 "Off" 2 "On" ;
VAL_ 1441 Sig4693 0 "No Action" 1 "Standard" 2 "Remote" ;
VAL_ 1441 Sig4631 0 "No Action" 1 "Preset" 2 "Variable" ;
VAL_ 1441 LocBsdChrgCstSetReq 0 "No Action" 1 "Off" 2 "On" ;
VAL_ 1441 Sig3636 0 "FALSE" 1 "TRUE" ;
VAL_ 1441 HiVltgBatStopChrgReq 0 "FALSE" 1 "TRUE" ;
VAL_ 1441 Sig3585 0 "FALSE" 1 "TRUE" ;
VAL_ 1441 Sig2638 0 "FALSE" 1 "TRUE" ;
VAL_ 1441 DrvrSeltdTrlrPrsnt 0 "Trailer Present" 1 "No Trailer" ;
VAL_ 1441 Sig0628 0 "FALSE" 1 "TRUE" ;
VAL_ 1441 Sig7788 0 "No Request" 1 "Reset Request Active" ;
VAL_ 1441 TripBEleclEngyEconRstReqd 0 "FALSE" 1 "TRUE" ;
VAL_ 1441 TripAEleclEngyEconRstReqd 0 "FALSE" 1 "TRUE" ;
VAL_ 1441 StlthModeActv 0 "FALSE" 1 "TRUE" ;
VAL_ 1441 LnchCtlRelLineLckReqd 0 "FALSE" 1 "TRUE" ;
VAL_ 1441 LifetmEleclEngyEconRstReqd 0 "FALSE" 1 "TRUE" ;
VAL_ 1441 HzrdReqActv 0 "FALSE" 1 "TRUE" ;
VAL_ 1441 OvrrdNextPlndCbnPrcndtngReq 0 "No Action" 1 "Off" 2 "On" ;
VAL_ 1441 TrlrProfDrvrReqdSeltn 0 "No Action" 1 "Default Profile" 2 "Profile1" 3 "Profile2" 4 "Profile3" 5 "Profile4" 6 "Profile5" 7 "Profile6" 8 "Profile7" 9 "Profile8" 10 "Profile9" 11 "Profile10" 12 "Profile11" 13 "Profile12" 14 "Profile13" 15 "Profile14" 16 "Profile15" 17 "Profile16" 18 "Profile17" 19 "Profile18" 20 "Profile19" 21 "Profile20" ;
VAL_ 1441 UIDInStatusSD 0 "Not Present" 1 "Present" ;
VAL_ 1529 UTCDay_Inv 0 "FALSE" 1 "TRUE" ;
VAL_ 1529 UTCHrs_Inv 0 "FALSE" 1 "TRUE" ;
VAL_ 1529 UTCMth_Inv 0 "FALSE" 1 "TRUE" ;
VAL_ 1529 UTCMth 0 "Unknown" 1 "January" 2 "February" 3 "March" 4 "April" 5 "May" 6 "June" 7 "July" 8 "August" 9 "September" 10 "October" 11 "November" 12 "December" ;
VAL_ 1529 UTCMin_Inv 0 "FALSE" 1 "TRUE" ;
VAL_ 1529 UTCSec_Inv 0 "FALSE" 1 "TRUE" ;
VAL_ 1529 UTCYr_Inv 0 "FALSE" 1 "TRUE" ;
VAL_ 1529 HtrCoreInltClntTmpCalc_Inv 0 "FALSE" 1 "TRUE" ;
VAL_ 1529 ClmCtlCustSetChgd 0 "FALSE" 1 "TRUE" ;
VAL_ 1529 ClmCtlCmfSetRchd 0 "FALSE" 1 "TRUE" ;
VAL_ 1529 ClmCtlCustSeltn 0 "Off" 1 "Remote Start" 2 "Auto" 3 "Manual" ;
VAL_ 1529 RVCOprtgMd 0 "Plant Assembly Mode" 1 "Remote Startup Mode" 2 "Ignition Startup Mode" 3 "Charge Recovery Mode" 4 "Normal Mode" 5 "Fuel Economy Mode" 6 "LI Safe Mode" 7 "LI Warming Mode" 8 "LI Cooling Mode" 9 "SOC Reconfirmation" 10 "RVC Inactive" ;
VAL_ 1529 ExtEnvCondChgDtd 0 "FALSE" 1 "TRUE" ;
VAL_ 183 Sig4991 0 "FALSE" 1 "TRUE" ;
VAL_ 183 Sig4993 0 "FALSE" 1 "TRUE" ;
VAL_ 183 DrvModeConfDrvrResp 0 "No Indication" 1 "Baja ESC Confirm" 2 "Baja ESC Cancel" 3 "Terrain ESC Confirm" 4 "Terrain ESC Cancel" 5 "Response 5" 6 "Response 6" 7 "Response 7" 8 "Response 8" 9 "Response 9" 10 "Response 10" 11 "Response 11" 12 "Response 12" 13 "Response 13" 14 "Response 14" 15 "Response 15" ;
VAL_ 183 Sig6842 0 "FALSE" 1 "TRUE" ;
VAL_ 76 eLSDActrDelTrq_Inv 0 "FALSE" 1 "TRUE" ;
VAL_ 76 eLSDActrThrCapUsd_Inv 0 "FALSE" 1 "TRUE" ;
VAL_ 1480 Sig8080 0 "FALSE" 1 "TRUE" ;
VAL_ 192 BrkSysRdGrdAccel_Inv 0 "FALSE" 1 "TRUE" ;
VAL_ 703 MaxPwrModeReqd 0 "FALSE" 1 "TRUE" ;
VAL_ 703 MaxPwrModeOvrrd 0 "FALSE" 1 "TRUE" ;
VAL_ 703 RrVirtBmpBrkgSts 0 "Not Active" 1 "Active" 2 "Failed" ;
VAL_ 703 BrkPulsSts 0 "Not Active" 1 "In Progress" 2 "Pulse Failed" 3 "Pulse Complete" ;
VAL_ 938 WhlSlpSt 0 "No Slip Detected" 1 "Negative Slip Detected" 2 "Positive Slip Detected" 3 "Slip Detection Fault" ;
VAL_ 938 BrkSysStatCrwlModeOvrrd 0 "No Override" 1 "Override to Not Crawl" 2 "Override to Crawl" ;
VAL_ 938 BrkSysHillRollCtrlStat 0 "Inactive" 1 "Control Target Vehicle Speed" 2 "Reserved_2" 3 "Reserved_3" ;
VAL_ 938 BrkSysHillStrtAsstStat 0 "Inactive" 1 "Brake Pressure Hold" 2 "Normal Pressure Decay" 3 "Drive-off Pressure Decay" 4 "Reserved_4" 5 "Reserved_5" 6 "Reserved_6" 7 "Reserved_7" ;
VAL_ 938 TrlrBrkDtd 0 "FALSE" 1 "TRUE" ;
VAL_ 938 EngDrgCtlFaild 0 "FALSE" 1 "TRUE" ;
VAL_ 938 EngDrgCtlActv 0 "FALSE" 1 "TRUE" ;
VAL_ 938 BrkSysHillRollCtrlAvl 0 "FALSE" 1 "TRUE" ;
VAL_ 945 RdWhlAng_Inv 0 "FALSE" 1 "TRUE" ;
VAL_ 945 VehPtchAng_Inv 0 "FALSE" 1 "TRUE" ;
VAL_ 945 VehRollAng_Inv 0 "FALSE" 1 "TRUE" ;
VAL_ 1414 BSTGR_ReqdGr 0 "No Action" 1 "First Gear" 2 "Second Gear" 3 "Third Gear" 4 "Fourth Gear" 5 "Fifth Gear" 6 "Sixth Gear" 7 "Seventh Gear" 8 "Eighth Gear" 9 "Ninth Gear" 10 "Tenth Gear" ;
VAL_ 1414 BSTGR_ReqTyp 0 "No Action" 1 "Max Gear Request" 2 "Min Gear Request" 3 "Hold Gear" ;
VAL_ 1430 RrCrsTrfcBrkgSysSts 0 "Not Active" 1 "Active" 2 "Failed" ;
VAL_ 1481 BSCERDTC_SysDes 0 "P0-Powertrain Codes SAE Controlled" 1 "P1-Powertrain Codes MFG Controlled" 2 "P2-Powertrain Codes Reserved" 3 "P3-Powertrain Codes Reserved" 4 "C0-Chassis Codes SAE Controlled" 5 "C1-Chassis Codes MFG Controlled" 6 "C2-Chassis Codes Reserved" 7 "C3-Chassis Codes Reserved" 8 "B0-Body Codes SAE Controlled" 9 "B1-Body Codes MFG Controlled" 10 "B2-Body Codes Reserved" 11 "B3-Body Codes Reserved" 12 "U0-Network Codes SAE Controlled" 13 "U1-Network Codes MFG Controlled" 14 "U2- Network Codes Reserved" 15 "U3-Network Codes Reserved" ;
VAL_ 1481 EngMntPrfMdRq 0 "No Action" 1 "Eco Mode" 2 "Sport Mode" 3 "Ice Mode" 4 "Performance Mode 4" 5 "Performance Mode 5" 6 "Performance Mode 6" 7 "Performance Mode 7" ;
VAL_ 1481 ACCPrfMdRq 0 "No Action" 1 "NORMAL" 2 "SPORTY" 3 "COMFORTABLE" 4 "ECO" 5 "Performance Mode 5" 6 "Performance Mode 6" 7 "Performance Mode 7" ;
VAL_ 1481 TireRRLoTracIndOn 0 "FALSE" 1 "TRUE" ;
VAL_ 1481 TireRFLoTracIndOn 0 "FALSE" 1 "TRUE" ;
VAL_ 1481 TireLRLoTracIndOn 0 "FALSE" 1 "TRUE" ;
VAL_ 1481 TireLFLoTracIndOn 0 "FALSE" 1 "TRUE" ;
VAL_ 1481 RrStrPrfMdRq 0 "No Action" 1 "Normal" 2 "Sport" 3 "Comfort" 4 "Track" 5 "Tow/Haul" 6 "Offroad" 7 "Terrain" ;
VAL_ 1481 ExhSndPrfMdRq 0 "No Action" 1 "Tour" 2 "Sport" 3 "Track" 4 "Stealth" 5 "Performance Mode 5" 6 "Performance Mode 6" 7 "Performance Mode 7" ;
VAL_ 1481 WthrSnwModeBrkPedVisDispVal 0 "Setting_Unknown" 1 "Custom_Mode_1" 2 "Custom_Mode_2" 3 "Custom_Mode_3" 4 "Custom_Mode_4" 5 "Custom_Mode_5" 6 "Custom_Mode_6" 7 "Custom_Mode_7" ;
VAL_ 1481 WthrSnwModeActvAeroVisDispVal 0 "Setting_Unknown" 1 "Custom_Mode_1" 2 "Custom_Mode_2" 3 "Custom_Mode_3" 4 "Custom_Mode_4" 5 "Custom_Mode_5" 6 "Custom_Mode_6" 7 "Custom_Mode_7" ;
VAL_ 1481 StrPrfMdRq 0 "No Action" 1 "Normal" 2 "Sport" 3 "Comfort" 4 "Track" 5 "Tow/Haul" 6 "Offroad" 7 "Terrain" ;
VAL_ 1481 WthrSnwModePwrtrnVisDispVal 0 "Setting_Unknown" 1 "Custom_Mode_1" 2 "Custom_Mode_2" 3 "Custom_Mode_3" 4 "Custom_Mode_4" 5 "Custom_Mode_5" 6 "Custom_Mode_6" 7 "Custom_Mode_7" ;
VAL_ 1481 WthrSnwModeESCVisDispVal 0 "Setting_Unknown" 1 "Custom_Mode_1" 2 "Custom_Mode_2" 3 "Custom_Mode_3" 4 "Custom_Mode_4" 5 "Custom_Mode_5" 6 "Custom_Mode_6" 7 "Custom_Mode_7" ;
VAL_ 1481 WthrSnwModeDrvlineVisDispVal 0 "Setting_Unknown" 1 "Custom_Mode_1" 2 "Custom_Mode_2" 3 "Custom_Mode_3" 4 "Custom_Mode_4" 5 "Custom_Mode_5" 6 "Custom_Mode_6" 7 "Custom_Mode_7" ;
VAL_ 1481 WthrSnwModeSndVisDispVal 0 "Setting_Unknown" 1 "Custom_Mode_1" 2 "Custom_Mode_2" 3 "Custom_Mode_3" 4 "Custom_Mode_4" 5 "Custom_Mode_5" 6 "Custom_Mode_6" 7 "Custom_Mode_7" ;
VAL_ 1481 WthrSnwModeRideHghtVisDispVal 0 "Setting_Unknown" 1 "Custom_Mode_1" 2 "Custom_Mode_2" 3 "Custom_Mode_3" 4 "Custom_Mode_4" 5 "Custom_Mode_5" 6 "Custom_Mode_6" 7 "Custom_Mode_7" ;
VAL_ 1481 DrvModeConfIndReq 0 "No Indication" 1 "Baja ESC Reduced" 2 "Terrain ESC Off" 3 "Max Power" 4 "Confirmation 4" 5 "Confirmation 5" 6 "Confirmation 6" 7 "Confirmation 7" ;
VAL_ 1481 ESCPrs 0 "FALSE" 1 "TRUE" ;
VAL_ 1481 BrkSysCtlEmsnsRltdMalfActv 0 "FALSE" 1 "TRUE" ;
VAL_ 1481 WthrSnwModeSpnsnVisDispVal 0 "Setting_Unknown" 1 "Custom_Mode_1" 2 "Custom_Mode_2" 3 "Custom_Mode_3" 4 "Custom_Mode_4" 5 "Custom_Mode_5" 6 "Custom_Mode_6" 7 "Custom_Mode_7" ;
VAL_ 1265 BrkFldLvlSt 0 "Normal" 1 "Low" 2 "Unknown" ;
VAL_ 1265 PIMRI_EBCM_PrmntDTCInd 0 "FALSE" 1 "TRUE" ;
VAL_ 1265 PIMRI_EBCM_FltsPrsntInd 0 "FALSE" 1 "TRUE" ;
VAL_ 1265 MaxPwrModeDndIndOn 0 "FALSE" 1 "TRUE" ;
VAL_ 1265 Sig4246 0 "Uninitialized" 1 "Healthy" 2 "Recoverable" 3 "Degraded" 4 "Failed" ;
VAL_ 1265 Sig4244 0 "Normal" 1 "Medium" 2 "High" 3 "Overtemp" ;
VAL_ 1265 Sig4248 0 "Uninitialized" 1 "Healthy" 2 "Recoverable" 3 "Degraded" 4 "Failed" ;
VAL_ 1265 Sig4247 0 "Uninitialized" 1 "Healthy" 2 "Recoverable" 3 "Degraded" 4 "Failed" ;
VAL_ 1265 Sig4249 0 "Uninitialized" 1 "Healthy" 2 "Recoverable" 3 "Degraded" 4 "Failed" ;
VAL_ 69 Sig0677 0 "FALSE" 1 "TRUE" ;
VAL_ 69 Sig0679 0 "FALSE" 1 "TRUE" ;
VAL_ 69 Sig0681 0 "FALSE" 1 "TRUE" ;
VAL_ 69 Sig0685 0 "FALSE" 1 "TRUE" ;
VAL_ 69 Sig0687 0 "FALSE" 1 "TRUE" ;
VAL_ 69 Sig2629 0 "FALSE" 1 "TRUE" ;
VAL_ 69 EngPrdctStdyStTrq_Inv 0 "FALSE" 1 "TRUE" ;
VAL_ 69 Sig0606 0 "Level 0" 1 "Level 1" 2 "Level 2" 3 "Level 3" 4 "Level 4" 5 "Level 5" 6 "Level 6" 7 "Level 7" ;
VAL_ 69 Sig2624 0 "Not Limited" 1 "Rate Limited" 2 "Value Limited Low" 3 "Value Limited High" 4 "Unused and Reserved 1" 5 "Unused and Reserved 2" 6 "Unused and Reserved 3" 7 "Unused and Reserved 4" ;
VAL_ 69 Sig0607 0 "Normal Stability" 1 "Torque High Pulsation" 2 "Torque Decrease Pending" 3 "Torque Increase Pending" 4 "Unused and Reserved 1" 5 "Unused and Reserved 2" 6 "Unused and Reserved 3" 7 "Unused and Reserved 4" ;
VAL_ 69 Sig2657 0 "No Request" 1 "Request Honored" 2 "Lost Arbitration" 3 "Serial Data Failure Temporary" 4 "Serial Data Failure Permanent" 5 "Control System Failure Temporary" 6 "Control System Failure Permanent" ;
VAL_ 69 Sig2656 0 "Not Limited" 1 "Rate Limited" 2 "Value Limited Low" 3 "Value Limited High" 4 "Unused and Reserved 1" 5 "Unused and Reserved 2" 6 "Unused and Reserved 3" 7 "Unused and Reserved 4" ;
VAL_ 69 Sig2625 0 "No Request" 1 "Request Honored" 2 "Lost Arbitration" 3 "Serial Data Failure Temporary" 4 "Serial Data Failure Permanent" 5 "Control System Failure Temporary" 6 "Control System Failure Permanent" ;
VAL_ 69 Sig7777 0 "FALSE" 1 "TRUE" ;
VAL_ 69 Sig7778 0 "FALSE" 1 "TRUE" ;
VAL_ 69 Sig2622 0 "FALSE" 1 "TRUE" ;
VAL_ 69 Sig2609 0 "FALSE" 1 "TRUE" ;
VAL_ 69 Sig0474 0 "FALSE" 1 "TRUE" ;
VAL_ 204 Sig0683 0 "FALSE" 1 "TRUE" ;
VAL_ 681 Sig2613 0 "FALSE" 1 "TRUE" ;
VAL_ 681 Sig2611 0 "All Cylinders Active" 1 "Deactivation In Progress" 2 "Half of Total Cylinders Active" 3 "Reactivation In Progress" ;
VAL_ 933 Sig2522 0 "None" 1 "First Gear" 2 "Second Gear" 3 "Third Gear" 4 "Fourth Gear" 5 "Fifth Gear" 6 "Sixth Gear" 7 "Seventh Gear" 8 "Eighth Gear" 9 "Ninth Gear" 10 "Tenth Gear" 11 "Unused" 12 "Unused" 13 "Unused" 14 "Unused" 15 "Unused" ;
VAL_ 933 Sig2521 0 "FALSE" 1 "TRUE" ;
VAL_ 933 Sig2520 0 "None" 1 "First Gear" 2 "Second Gear" 3 "Third Gear" 4 "Fourth Gear" 5 "Fifth Gear" 6 "Sixth Gear" 7 "Seventh Gear" 8 "Eighth Gear" 9 "Ninth Gear" 10 "Tenth Gear" 11 "Unused" 12 "Unused" 13 "Unused" 14 "Unused" 15 "Unused" ;
VAL_ 933 Sig2523 0 "Shift Down" 1 "Shift Up" 2 "No Shift" ;
VAL_ 933 EASSI_StrtStpSt 0 "Engine Off" 1 "Engine Running" 2 "Engine Starting" 3 "Engine Stopping" ;
VAL_ 933 EASSI_StlDtd 0 "FALSE" 1 "TRUE" ;
VAL_ 933 EASSI_FlRqOn 0 "FALSE" 1 "TRUE" ;
VAL_ 933 Sig2466 0 "FALSE" 1 "TRUE" ;
VAL_ 933 Sig2465 0 "FALSE" 1 "TRUE" ;
VAL_ 933 Sig2464 0 "FALSE" 1 "TRUE" ;
VAL_ 933 Sig2463 0 "No Start" 1 "Type A" 2 "Type B" 3 "Type C" 4 "Type D" 5 "Type E" 6 "Type F" 7 "Type G" ;
VAL_ 933 Sig2554 0 "No Action" 1 "Max Gear Request" 2 "Min Gear Request" 3 "Hold Gear" ;
VAL_ 933 Sig2562 0 "Full Torque Capacity" 1 "Reduced Capacity 1" ;
VAL_ 933 Sig2561 0 "Full Torque Capacity" 1 "Reduced Capacity 1" ;
VAL_ 933 Sig2555 0 "No Action" 1 "First Gear" 2 "Second Gear" 3 "Third Gear" 4 "Fourth Gear" 5 "Fifth Gear" 6 "Sixth Gear" 7 "Seventh Gear" 8 "Eighth Gear" 9 "Ninth Gear" 10 "Tenth Gear" ;
VAL_ 933 Sig7805 0 "Motor Disabled Mode" 1 "Conventional Generation Mode" 2 "Hybrid Optimization Mode" ;
VAL_ 933 Sig2608 0 "Inactive" 1 "Engaged" 2 "Resume" 3 "Accel" 4 "Coast" 5 "Tap" ;
VAL_ 933 EngAtStpNtPrbl 0 "FALSE" 1 "TRUE" ;
VAL_ 933 Sig0470 0 "FALSE" 1 "TRUE" ;
VAL_ 933 Sig2589 0 "Inactive" 1 "Active Not Absorbing Torque" 2 "Active Absorbing Torque" ;
VAL_ 933 Sig2571 0 "No Action" 1 "Off" 2 "On" ;
VAL_ 933 CltTpTrvAchv 0 "FALSE" 1 "TRUE" ;
VAL_ 933 CltTpTrvAchv_Inv 0 "FALSE" 1 "TRUE" ;
VAL_ 933 Sig8060 0 "Inactive" 1 "Active" ;
VAL_ 933 Sig7665 0 "FALSE" 1 "TRUE" ;
VAL_ 933 Sig5015 0 "FALSE" 1 "TRUE" ;
VAL_ 933 GlwPlgCrnkDlyActv 0 "FALSE" 1 "TRUE" ;
VAL_ 933 Sig2662 0 "FALSE" 1 "TRUE" ;
VAL_ 933 Sig2632 0 "FALSE" 1 "TRUE" ;
VAL_ 933 Sig2616 0 "FALSE" 1 "TRUE" ;
VAL_ 933 Sig2603 0 "Inactive" 1 "Active" ;
VAL_ 933 Sig2559 0 "No Indication" 1 "Complete" 2 "Phase 1" 3 "Phase 2" 4 "Phase 3" 5 "Skip Phase 2" ;
VAL_ 933 Sig0665 0 "FALSE" 1 "TRUE" ;
